VERSION ""

NS_ :

BS_:

BU_: SGW RFHM MPAD IPC GNMM EVCU2 ESL ECM DTCM DMSM BSM BCM AGSM ADCAM

BO_ 1056 EPS_FD_2: 32 BCM
 SG_ EPS_Warn_Disp_Rq : 87|3@0+ (1,0) [0|3] "" MPAD,SGW,BSM,IPC
 SG_ MessageCounter_EPS2 : 179|4@0+ (1,0) [0|15] ""  MPAD,BSM,IPC
 SG_ CRC_EPS2 : 191|8@0+ (1,0) [0|255] ""  MPAD,BSM,IPC
 SG_ MAC_EPS2 : 215|48@0+ (1,0) [0|0] "-"  MPAD,BSM
 SG_ Cntr_EPS2 : 199|16@0+ (1,0) [0|0] "-"  MPAD,BSM

BO_ 264 EPS_FD_1: 32 BCM
 SG_ LwsAngle : 7|16@0+ (0.1,-720) [-720|720] "°"  MPAD,EVCU2,DMSM,GNMM,BSM,IPC,DTCM
 SG_ LwsSpeed : 19|12@0+ (1,-2000) [-2000|2094] "°/s"  MPAD,EVCU2,BSM,DTCM
 SG_ MessageCounter_EPS1 : 179|4@0+ (1,0) [0|15] "-"  MPAD,EVCU2,BSM
 SG_ CRC_EPS1 : 191|8@0+ (1,0) [0|255] "-"  MPAD,EVCU2,BSM
 SG_ LwsCalibration : 36|1@0+ (1,0) [0|1] "-"  BSM,DTCM
 SG_ LwsAngleType : 52|2@0+ (1,0) [0|2] "-"  BSM
 SG_ EngineFanRequestActivation : 38|1@0+ (1,0) [0|1] "-"  MPAD,BSM
 SG_ ElectricSteeringFailSts : 37|1@0+ (1,0) [0|1] "-"  MPAD,BSM,DTCM
 SG_ LwsAngle_F : 105|16@0+ (0.1,-720) [-720|720] "°"  MPAD,BSM
 SG_ MAC_EPS1 : 215|48@0+ (1,0) [0|0] "-"  MPAD,BSM
 SG_ Cntr_EPS1 : 199|16@0+ (1,0) [0|0] "-"  MPAD,BSM

BO_ 1055 ENGINE_FD_8: 32 ECM
 SG_ RevOilLifeRst : 167|16@0+ (1000,0) [0|65534000] "Rev's"  BCM
 SG_ RefuelEvent : 44|3@0+ (1,0) [0|0] "-"  BCM
 SG_ OIL_PRESS : 159|8@0+ (4,0) [0|1016] "kPaG"  SGW,IPC
 SG_ MAP_4_BAR : 96|9@0+ (0.8,0) [0|408] "kPa"  SGW,BCM
 SG_ AM_ECM_Prsnt : 103|2@0+ (1,0) [0|2] "-"  BCM
 SG_ MessageCounter_ENGINE8 : 179|4@0+ (1,0) [0|15] "-"  EVCU2
 SG_ CRC_ENGINE8 : 191|8@0+ (1,0) [0|255] "-"  EVCU2
 SG_ RefuelIndication : 47|3@0+ (1,0) [0|7] "-"  IPC

BO_ 1448 ENGINE_FD_7: 32 EVCU2
 SG_ ExhaustTemperature : 135|8@0+ (4,0) [0|1020] "°C"  Vector__XXX
 SG_ ETCFailSts : 115|2@0+ (1,0) [0|3] "-"  IPC
 SG_ EngineOperatingMode : 124|3@0+ (1,0) [0|7] "-"  Vector__XXX
 SG_ EMSFailSts : 82|2@0+ (1,0) [0|3] "-"  BCM,IPC
 SG_ ECM_WARN : 159|5@0+ (1,0) [0|31] "-"  IPC
 SG_ OilPressureSts : 119|1@0+ (1,0) [0|1] "-"  SGW,BCM,IPC
 SG_ HoursOilLifeRst : 35|12@0+ (1,0) [0|4000] "Hours"  BCM
 SG_ MntncSts : 137|2@0+ (1,0) [0|3] "-"  IPC

BO_ 751 ENGINE_FD_6: 32 ECM
 SG_ EngineWaterTemp : 95|8@0+ (1,-40) [-40|215] "°C"  SGW,BCM,IPC
 SG_ MessageCounter_ENGINE6 : 179|4@0+ (1,0) [0|15] "-"  SGW
 SG_ LeakTestSts : 169|2@0+ (1,0) [0|0] ""  BCM
 SG_ LeakTestRequest : 160|1@0+ (1,0) [0|1] "-"  BCM
 SG_ LeakCheckTimerValue : 56|9@0+ (1,0) [0|510] "min"  BCM
 SG_ CRC_ENGINE6 : 191|8@0+ (1,0) [0|255] "-"  SGW
 SG_ ECM_FOTA_Conflict : 8|1@0+ (1,0) [0|1] "-"  Vector__XXX

BO_ 518 ENGINE_FD_5: 32 ECM
 SG_ RPMOverRev_W : 115|1@0+ (1,0) [0|1] "-"  Vector__XXX
 SG_ PdlPosActual : 87|8@0+ (0.4,0) [0|100] "%"  SGW,BCM
 SG_ MessageCounter_ENGINE5 : 179|4@0+ (1,0) [0|15] "-"  EVCU2
 SG_ ECM_READINESS_RESET_W : 140|1@0+ (1,0) [0|0] ""  EVCU2,BSM
 SG_ ECM_CODE_CLR_W : 141|1@0+ (1,0) [0|0] ""  EVCU2,BSM
 SG_ CRC_ENGINE5 : 191|8@0+ (1,0) [0|255] "-"  EVCU2

BO_ 1054 ENGINE_FD_1: 32 ECM
 SG_ ThrottlePosition : 87|8@0+ (0.392,0) [0|99.96] "%"  SGW,BCM
 SG_ ThermalManagementActive_W : 1|1@0+ (1,0) [0|1] "-"  EVCU2
 SG_ RawTPS2 : 55|8@0+ (0.019607843,0) [0|4.98] "V"  SGW
 SG_ RawTPS1 : 63|8@0+ (0.019607843,0) [0|4.98] "V"  SGW,BCM
 SG_ MessageCounter_ENGINE1 : 179|4@0+ (1,0) [0|15] "-"  EVCU2
 SG_ Lv1CrsCtrlOff : 7|1@0+ (1,0) [0|1] "-"  SGW,BCM
 SG_ ESP_TrqRqEnabl : 6|1@0+ (1,0) [0|1] "-"  SGW,BCM
 SG_ EngMaxRPM_W : 127|8@0+ (50,0) [0|10000] "-"  EVCU2
 SG_ CRC_ENGINE1 : 191|8@0+ (1,0) [0|255] "-"  EVCU2
 SG_ BrkSw2Stat : 5|1@0+ (1,0) [0|1] "-"  SGW,BCM
 SG_ BrkSw1Stat : 4|1@0+ (1,0) [0|1] "-"  SGW
 SG_ AtmosphericPressureFailSts_W : 0|1@0+ (1,0) [0|1] "-"  Vector__XXX
 SG_ AtmosphericPressure_W : 143|8@0+ (3.6,300) [300|1214.4] "mbar"  RFHM
 SG_ HighPressureFuelSystemFailure : 2|1@0+ (1,0) [0|1] "-"  IPC

BO_ 2654817991 ECU_APPL_FD_RFHM: 64 RFHM
 SG_ ECU_APPL_FD_RFHM : 455|64@0+ (1,0) [0|0] "" Vector__XXX

BO_ 2654817818 ECU_APPL_FD_DTCM: 64 DTCM
 SG_ ECU_APPL_FD_DTCM : 455|64@0+ (1,0) [0|0] "" SGW

BO_ 2654817823 ECU_APPL_FD_AGSM: 64 AGSM
 SG_ ECU_APPL_FD_AGSM : 455|64@0+ (1,0) [0|0] "" SGW

BO_ 1068 DRIVETRAIN_FD_3: 32 DTCM
 SG_ DTCM_Vehicle_Hold_Rq : 103|1@0+ (1,0) [0|1] "" Vector__XXX
 SG_ TCASERANGESTATUS : 89|2@0+ (1,0) [0|2] "" ADCAM,MPAD,EVCU2,SGW,BCM,BSM,IPC,DTCM
 SG_ RrAxleLockerIndRq : 5|2@0+ (1,0) [0|2] "" BCM,IPC
 SG_ AxleLckrEvicDisp : 23|5@0+ (1,0) [0|30] "" IPC
 SG_ AxleLckr_Stat : 7|2@0+ (1,0) [0|2] "" SGW,IPC
 SG_ AxleLckr_SRV_RQ : 1|2@0+ (1,0) [0|2] "" IPC
 SG_ MessageCounter_DRIVETRAIN3 : 179|4@0+ (1,0) [0|15] "-" BCM,EVCU2
 SG_ CRC__DRIVETRAIN3 : 191|8@0+ (1,0) [0|255] "-" BCM,EVCU2

BO_ 1447 DRIVETRAIN_FD_2: 32 DTCM
 SG_ TerSt_SWITCH2 : 87|2@0+ (1,0) [0|3] "-"  SGW,BCM,IPC
 SG_ TerSt_SWITCH1 : 85|2@0+ (1,0) [0|3] "-"  SGW,BCM,IPC
 SG_ DTCM_HMI_Rq : 109|5@0+ (1,0) [0|31] "-"  IPC
 SG_ Ft_RrCouplingTrq_percentage : 119|8@0+ (0.5,0) [0|127.5] "%"  Vector__XXX

BO_ 517 DRIVETRAIN_FD_1: 32 DTCM
 SG_ Ft_RrCouplingTrq_Desired : 111|8@0+ (12,0) [1|3000] "Nm"  EVCU2,SGW
 SG_ Ft_RrCouplingTrq_Actual : 103|8@0+ (12,0) [1|3000] "Nm"  EVCU2,SGW,BSM
 SG_ DrvLnMinTrqMd : 84|1@0+ (1,0) [0|1] "-"  EVCU2
 SG_ CCMFailSts : 83|1@0+ (1,0) [0|1] "-"  EVCU2,SGW,BSM,IPC
 SG_ AWDSysStat : 87|3@0+ (1,0) [0|7] "-"  EVCU2,SGW,BCM,BSM,IPC,RFHM,DTCM
 SG_ TCASE_TargetRangeState : 9|2@0+ (1,0) [0|3] "" EVCU2
 SG_ SpeedSyncRq : 20|3@0+ (1,0) [0|7] "" EVCU2
 SG_ RDU_State : 41|2@0+ (1,0) [0|3] "" EVCU2
 SG_ PTU_State : 44|3@0+ (1,0) [0|7] "" EVCU2
 SG_ DrvLnTrqRq_Axle : 31|16@0+ (1,0) [0|65535] "Nm"  EVCU2
 SG_ MessageCounter_DRIVETRAIN1 : 179|4@0+ (1,0) [0|15] "-" EVCU2
 SG_ CRC_DRIVETRAIN1 : 191|8@0+ (1,0) [0|255] "-" EVCU2

BO_ 2564682015 DIAGNOSTIC_ROE_SHIFTER: 8 AGSM
 SG_ N_PDU : 7|64@0+ (1,0) [0|0] "" SGW

BO_ 2564682183 DIAGNOSTIC_ROE_RFHM: 8 RFHM
 SG_ N_PDU : 7|64@0+ (1,0) [0|0] "" SGW

BO_ 2564682080 DIAGNOSTIC_ROE_IPC: 8 IPC
 SG_ N_PDU : 7|64@0+ (1,0) [0|0] "" SGW

BO_ 2564682256 DIAGNOSTIC_ROE_FD_ECM: 64 ECM
 SG_ N_PDU : 7|64@0+ (1,0) [0|0] "" SGW

BO_ 2564682266 DIAGNOSTIC_ROE_FD_DTCM: 64 DTCM
 SG_ N_PDU : 7|64@0+ (1,0) [0|0] "" SGW

BO_ 2564682180 DIAGNOSTIC_ROE_ESL: 8 ESL
 SG_ N_PDU : 7|64@0+ (1,0) [0|0] "" SGW

BO_ 2564682000 DIAGNOSTIC_ROE_ECM: 8 ECM
 SG_ N_PDU : 7|64@0+ (1,0) [0|0] "" SGW

BO_ 2564682010 DIAGNOSTIC_ROE_DTCM: 8 DTCM
 SG_ N_PDU : 7|64@0+ (1,0) [0|0] "" SGW

BO_ 2564682024 DIAGNOSTIC_ROE_BSM: 8 BSM
 SG_ N_PDU : 7|64@0+ (1,0) [0|0] "" SGW

BO_ 2564485663 DIAGNOSTIC_RESPONSE_FD_SHIFTER: 64 AGSM
 SG_ N_PDU : 7|64@0+ (1,0) [0|0] "" SGW

BO_ 2564485831 DIAGNOSTIC_RESPONSE_FD_RFHM: 64 RFHM
 SG_ N_PDU : 7|64@0+ (1,0) [0|0] "" SGW

BO_ 2564485728 DIAGNOSTIC_RESPONSE_FD_IPC: 64 IPC
 SG_ N_PDU : 7|64@0+ (1,0) [0|0] "" SGW

BO_ 2564485828 DIAGNOSTIC_RESPONSE_FD_ESL: 64 ESL
 SG_ N_PDU : 7|64@0+ (1,0) [0|0] "" SGW

BO_ 2564485648 DIAGNOSTIC_RESPONSE_FD_ECM: 64 ECM
 SG_ N_PDU : 7|64@0+ (1,0) [0|0] "" SGW

BO_ 2564485658 DIAGNOSTIC_RESPONSE_FD_DTCM: 64 DTCM
 SG_ N_PDU : 7|64@0+ (1,0) [0|0] "" SGW

BO_ 2564485672 DIAGNOSTIC_RESPONSE_FD_BSM: 64 BSM
 SG_ N_PDU : 7|64@0+ (1,0) [0|0] "" SGW

BO_ 2564431858 DIAGNOSTIC_REQUEST_FD_SHIFTER: 64 SGW
 SG_ N_PDU : 7|64@0+ (1,0) [0|0] "" AGSM

BO_ 2564474866 DIAGNOSTIC_REQUEST_FD_RFHM: 64 SGW
 SG_ N_PDU : 7|64@0+ (1,0) [0|0] "" RFHM

BO_ 2564448498 DIAGNOSTIC_REQUEST_FD_IPC: 64 SGW
 SG_ N_PDU : 7|64@0+ (1,0) [0|0] "" IPC

BO_ 2564554482 DIAGNOSTIC_REQUEST_FD_FUNCTIONAL: 64 SGW
 SG_ N_PDU : 7|64@0+ (1,0) [0|0] "" ADCAM,MPAD,EVCU2,DMSM,GNMM,AGSM,ESL,BCM,BSM,IPC,RFHM,ECM,DTCM

BO_ 2564474098 DIAGNOSTIC_REQUEST_FD_ESL: 64 SGW
 SG_ N_PDU : 7|64@0+ (1,0) [0|0] "" EVCU2,ESL

BO_ 2564428018 DIAGNOSTIC_REQUEST_FD_ECM: 64 SGW
 SG_ N_PDU : 7|64@0+ (1,0) [0|0] "" ECM

BO_ 2564430578 DIAGNOSTIC_REQUEST_FD_DTCM: 64 SGW
 SG_ N_PDU : 7|64@0+ (1,0) [0|0] "" DTCM

BO_ 2564434162 DIAGNOSTIC_REQUEST_FD_BSM: 64 SGW
 SG_ N_PDU : 7|64@0+ (1,0) [0|0] "" BSM

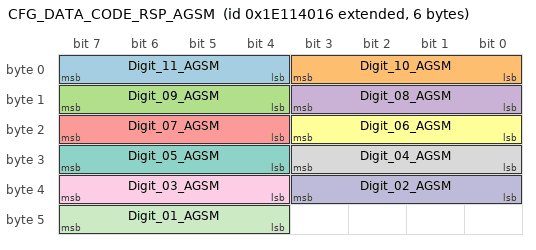
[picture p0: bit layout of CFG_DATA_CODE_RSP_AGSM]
BO_ 2651930646 CFG_DATA_CODE_RSP_AGSM: 6 AGSM
 SG_ Digit_11_AGSM : 7|4@0+ (1,0) [0|15] "-"  BCM
 SG_ Digit_10_AGSM : 3|4@0+ (1,0) [0|15] "-"  BCM
 SG_ Digit_09_AGSM : 15|4@0+ (1,0) [0|15] "-"  BCM
 SG_ Digit_08_AGSM : 11|4@0+ (1,0) [0|15] "-"  BCM
 SG_ Digit_07_AGSM : 23|4@0+ (1,0) [0|15] "-"  BCM
 SG_ Digit_06_AGSM : 19|4@0+ (1,0) [0|15] "-"  BCM
 SG_ Digit_05_AGSM : 31|4@0+ (1,0) [0|15] "-"  BCM
 SG_ Digit_04_AGSM : 27|4@0+ (1,0) [0|15] "-"  BCM
 SG_ Digit_03_AGSM : 39|4@0+ (1,0) [0|15] "-"  BCM
 SG_ Digit_02_AGSM : 35|4@0+ (1,0) [0|15] "-"  BCM
 SG_ Digit_01_AGSM : 47|4@0+ (1,0) [0|15] "-"  BCM

BO_ 514 BRAKE_FD_7: 32 BSM
 SG_ PAM_Brk_Rq_RspSts : 28|2@0+ (1,0) [0|3] "-"  BCM,IPC
 SG_ MessageCounter_BRAKE7 : 179|4@0+ (1,0) [0|15] "-"  ADCAM,MPAD,EVCU2,BCM
 SG_ HoldnGoLEDSts : 91|2@0+ (1,0) [0|2] "" BCM
 SG_ CRC_BRAKE7 : 191|8@0+ (1,0) [0|255] "-"  ADCAM,MPAD,EVCU2,BCM
 SG_ BrkPdl_Stat : 85|2@0+ (1,0) [0|2] "-"  MPAD,EVCU2,SGW,BCM,IPC,RFHM,ECM,DTCM
 SG_ BrkPdl_Flt : 86|1@0+ (1,0) [0|1] "-"  MPAD,EVCU2,SGW,BCM,ECM,DTCM
 SG_ BrakePdlPosn : 63|8@0+ (0.4,0) [0|100] "%"  EVCU2,SGW,BCM,ECM
 SG_ AVHTextDispaly : 71|4@0+ (1,0) [0|15] "-"  IPC
 SG_ AutoVehHoldSts : 30|2@0+ (1,0) [0|3] "-"  MPAD,EVCU2,BCM,IPC
 SG_ Rear_Diff_BSM_RQ : 77|2@0+ (1,0) [0|2] "-"  BCM,DTCM
 SG_ R_DIFF_TRQ_RQ : 40|9@0+ (10,0) [0|5100] "Nm"  DTCM
 SG_ BSM_OpStat : 74|3@0+ (1,0) [0|5] "" MPAD,BCM,DTCM
 SG_ Brake_OpStat_Prim : 82|3@0+ (1,0) [0|5] "" MPAD
 SG_ AEB_Type_Brk : 67|4@0+ (1,0) [0|14] "-"  ADCAM,MPAD

BO_ 1155 BRAKE_FD_5: 32 BSM
 SG_ TSCActive : 110|1@0+ (1,0) [0|1] "-"  MPAD,BCM
 SG_ RollsModeAct : 91|1@0+ (1,0) [0|1] "-"  MPAD,EVCU2,DTCM
 SG_ FunctionIntervention : 80|1@0+ (1,0) [0|1] "-"  DTCM
 SG_ FunctionFailSts : 81|1@0+ (1,0) [0|1] "-"  DTCM
 SG_ Function2Sts : 94|1@0+ (1,0) [0|1] "-"  MPAD,SGW,BCM,IPC,DTCM
 SG_ ESCIntervention : 82|1@0+ (1,0) [0|1] "-"  BCM,IPC,DTCM
 SG_ ESCFailSts : 83|1@0+ (1,0) [0|1] "-"  MPAD,EVCU2,SGW,BCM,IPC,DTCM
 SG_ ERMActive : 111|1@0+ (1,0) [0|1] "-"  BCM,DTCM
 SG_ EBDFailSts : 84|1@0+ (1,0) [0|1] "-"  SGW,BCM,IPC
 SG_ CMMIntervention : 86|1@0+ (1,0) [0|1] "-"  Vector__XXX
 SG_ BSMSysSts : 89|2@0+ (1,0) [0|3] "-"  SGW,DTCM
 SG_ ACCEngaged : 92|1@0+ (1,0) [0|1] "-"  EVCU2,SGW
 SG_ ABSFailSts : 87|1@0+ (1,0) [0|1] "-"  MPAD,EVCU2,SGW,BCM,IPC,DTCM
 SG_ MessageCounter_BRAKE5 : 179|4@0+ (1,0) [0|15] "-"  MPAD,EVCU2,IPC
 SG_ HDCUserFdBck : 124|2@0+ (1,0) [0|3] "-"  IPC
 SG_ CRC_BRAKE5 : 191|8@0+ (1,0) [0|255] "-"  MPAD,EVCU2,IPC
 SG_ FunctionSts : 95|1@0+ (1,0) [0|1] "-"  ADCAM,MPAD,BCM,IPC,DTCM
 SG_ HillHolderFailSts : 7|1@0+ (1,0) [0|1] "-"  Vector__XXX

BO_ 609 BRAKE_FD_4: 32 BSM
 SG_ TravelDistance : 87|8@0+ (1,0) [0|255] "m"  EVCU2,SGW,IPC,ECM
 SG_ RedLampReq : 131|2@0+ (1,0) [0|3] "-"  IPC
 SG_ MSRActive : 92|1@0+ (1,0) [0|1] "-"  EVCU2,BCM
 SG_ EPBSwitchPosition : 119|2@0+ (1,0) [0|3] "-"  BCM
 SG_ EPBSts : 115|4@0+ (1,0) [0|14] "-"  MPAD,EVCU2,SGW,BCM,IPC,DTCM
 SG_ EPBMaintenanceSts : 128|1@0+ (1,0) [0|1] "-"  SGW
 SG_ EPBAutoAppSts : 127|1@0+ (1,0) [0|1] "-"  Vector__XXX
 SG_ EPB_HMI_Management : 148|5@0+ (1,0) [0|31] "-"  SGW,IPC
 SG_ ClampForce : 88|9@0+ (0.1,-0.1) [0|51] "KN"  SGW,BCM
 SG_ ASRActive : 90|1@0+ (1,0) [0|1] "-"  MPAD,EVCU2,SGW,BCM,DTCM
 SG_ REPRGD_PFC_CLR_BSM : 175|1@0+ (1,0) [0|1] "-"  ECM
 SG_ MIL_OnRq_BSM : 172|1@0+ (1,0) [0|1] "-"  SGW,ECM
 SG_ MessageCounter_BRAKE4 : 179|4@0+ (1,0) [0|15] "-"  MPAD,EVCU2,BCM,IPC
 SG_ ESCSysEmsMlfAtv : 159|1@0+ (1,0) [0|0] "-"  Vector__XXX
 SG_ EPBWarningLampReq : 174|2@0+ (1,0) [0|0] "-"  BCM,IPC
 SG_ CRC_BRAKE4 : 191|8@0+ (1,0) [0|255] "-"  MPAD,EVCU2,BCM,IPC
 SG_ CODE_CLR_BSM : 160|1@0+ (1,0) [0|1] "-"  ECM
 SG_ ESC_OFF_Hrd_Sft_Button_sts : 151|3@0+ (1,0) [0|6] "-"  SGW,BCM

BO_ 259 BRAKE_FD_3: 32 BSM
 SG_ RHR_WheelSensorFailSts : 103|1@0+ (1,0) [0|1] "-"  MPAD,EVCU2,SGW,BCM,DTCM
 SG_ RHR_Spin : 102|2@0+ (1,0) [0|3] "-"  MPAD,EVCU2,SGW,BCM,DTCM
 SG_ RHR_FastPulseCounter : 159|8@0+ (1,0) [0|255] "pulse"  MPAD,EVCU2,GNMM,SGW,BCM,RFHM
 SG_ RHF_WheelSensorFailSts : 182|1@0+ (1,0) [0|1] "-"  MPAD,EVCU2,SGW,BCM,DTCM
 SG_ RHF_FastPulseCounter : 175|8@0+ (1,0) [0|255] "pulse"  MPAD,EVCU2,GNMM,SGW,BCM,RFHM
 SG_ LHR_WheelSensorFailSts : 87|1@0+ (1,0) [0|1] "-"  MPAD,EVCU2,SGW,BCM,DTCM
 SG_ LHR_Spin : 86|2@0+ (1,0) [0|3] "-"  MPAD,EVCU2,SGW,BCM,DTCM
 SG_ LHR_FastPulseCounter : 151|8@0+ (1,0) [0|255] "pulse"  MPAD,EVCU2,GNMM,SGW,BCM,RFHM
 SG_ LHF_WheelSensorFailSts : 181|1@0+ (1,0) [0|1] "-"  MPAD,EVCU2,SGW,BCM,DTCM
 SG_ LHF_FastPulseCounter : 167|8@0+ (1,0) [0|255] "pulse"  MPAD,EVCU2,GNMM,SGW,BCM,RFHM
 SG_ RHRWheelSpeed : 68|13@0+ (0.0625,0) [0|511.875] "Km/h"  MPAD,EVCU2,GNMM,SGW,BCM,ECM,DTCM
 SG_ RHFWheelSpeed : 52|13@0+ (0.0625,0) [0|511.875] "Km/h"  MPAD,EVCU2,GNMM,SGW,BCM,ECM,DTCM
 SG_ RHF_Spin : 7|2@0+ (1,0) [0|3] "-"  MPAD,EVCU2,SGW,BCM,DTCM
 SG_ MessageCounter_BRAKE3 : 179|4@0+ (1,0) [0|15] "-"  MPAD,EVCU2,GNMM,BCM
 SG_ LHRWheelSpeed : 4|13@0+ (0.0625,0) [0|511.875] "Km/h"  MPAD,EVCU2,GNMM,SGW,BCM,ECM,DTCM
 SG_ LHFWheelSpeed : 20|13@0+ (0.0625,0) [0|511.875] "Km/h"  MPAD,EVCU2,GNMM,SGW,BCM,ECM,DTCM
 SG_ LHF_Spin : 23|2@0+ (1,0) [0|3] "-"  MPAD,EVCU2,SGW,BCM,DTCM
 SG_ CRC__BRAKE3 : 191|8@0+ (1,0) [0|255] "-"  MPAD,EVCU2,GNMM,BCM
 SG_ LongAccelerationOffset_BSM : 119|8@0+ (0.02,-2.56) [-2.56|2.52] "m/s^2"  Vector__XXX
 SG_ LatAccelerationOffset_BSM : 127|8@0+ (0.02,-2.56) [-2.56|2.52] "m/s^2"  Vector__XXX
 SG_ LwsAngleOffset_BSM : 81|10@0+ (0.1,-51.1) [-51.1|51.1] "°"  GNMM

BO_TX_BU_ 1448 : EVCU2,ECM;
CM_ SG_ 1056 CRC_EPS2 "CRC according to SAE J1850 standard at each frame transmission.";
CM_ SG_ 1056 Cntr_EPS2 "-";
CM_ SG_ 1056 EPS_Warn_Disp_Rq "Electric Power Steering Warning Display Request";
CM_ SG_ 1056 MessageCounter_EPS2 "This signal is a counter used for safety checks strategies. This counter is incremented of 1 (one) unit at each frame transmission.";
CM_ SG_ 1056 MAC_EPS2 "-";
CM_ SG_ 264 LwsAngle "This signal indicates the steering angle value, counterclockwise positive.";
CM_ SG_ 264 LwsSpeed "This signal indicates the steering speed value, counterclockwise positive.";
CM_ SG_ 264 LwsAngle_F "This signal indicates the steering angle value, counterclockwise positive - duplicated signal for FUSA";
CM_ SG_ 264 LwsAngleType "This signal indicates whether the angle sensor is absolute (all the possible turns/degrees) or not absolute (relative, torque only, etc.).";
CM_ SG_ 264 LwsCalibration "This signal indicates if the sensor has been calibrated and therefore the steering angle value is exported over Can.";
CM_ SG_ 264 MAC_EPS1 "-";
CM_ SG_ 264 MessageCounter_EPS1 "This signal is a counter used for safety checks strategies. This counter is incremented of 1 (one) unit at each frame transmission.";
CM_ SG_ 264 EngineFanRequestActivation "This signal is used to activate the cooling fun by the electric power steering.";
CM_ SG_ 264 ElectricSteeringFailSts "It indicates if system EPS has an internal fault.";
CM_ SG_ 264 Cntr_EPS1 "-";
CM_ SG_ 264 CRC_EPS1 "CRC according to SAE J1850 standard at each frame transmission.";
CM_ SG_ 1055 RefuelIndication "Indication to the driver about the status of the refuel system";
CM_ SG_ 1055 RevOilLifeRst "Engine revolutions since last oil life reset";
CM_ SG_ 1055 AM_ECM_Prsnt "Aftermarket ECM present";
CM_ SG_ 1055 CRC_ENGINE8 "CRC according to SAE J1850 standard at each frame transmission.";
CM_ SG_ 1055 MAP_4_BAR "Engine manifold pressure (4 bar range)";
CM_ SG_ 1055 MessageCounter_ENGINE8 "This signal is a counter used for safety checks strategies. This counter is incremented of 1 (one) unit at each frame transmission.";
CM_ SG_ 1055 OIL_PRESS "Oil pressure";
CM_ SG_ 1055 RefuelEvent "Status of refuel event";
CM_ SG_ 1448 MntncSts "Maintenance reminder status";
CM_ SG_ 1448 ECM_WARN "This signal will be used to drive warning messages on Cluster.";
CM_ SG_ 1448 HoursOilLifeRst "Hours since last oil life reset";
CM_ SG_ 1448 OilPressureSts "This signal  indicates oil pressure status (High or low).";
CM_ SG_ 1448 EMSFailSts "This signal is used  to switch on and off the engine control system warning lamp (called MI for EOBD applications)";
CM_ SG_ 1448 EngineOperatingMode "This signal indicates the engine operating mode (normal or after-treatment systems regeneration)";
CM_ SG_ 1448 ETCFailSts "This signal is used  to switch on and off  ETC lamp to give informations about faults not EOBD relevant.";
CM_ SG_ 1448 ExhaustTemperature "This signal indicates the exhaust engine temperature after combustion or after-treatment systems (if applicable)";
CM_ SG_ 751 LeakTestRequest "Leak test is requested after powerdown; No request = [0], Leak test requested = [1]";
CM_ SG_ 751 LeakCheckTimerValue "Requested leak test timer value";
CM_ SG_ 751 ECM_FOTA_Conflict "ECM Conflict with FOTA";
CM_ SG_ 751 CRC_ENGINE6 "CRC according to SAE J1850 standard at each frame transmission.";
CM_ SG_ 751 EngineWaterTemp "-";
CM_ SG_ 751 MessageCounter_ENGINE6 "This signal is a counter used for safety checks strategies. This counter is incremented of 1 (one) unit at each frame transmission.";
CM_ SG_ 751 LeakTestSts "Status of leak test";
CM_ SG_ 518 RPMOverRev_W "-";
CM_ SG_ 518 PdlPosActual "Actual pedal position.";
CM_ SG_ 518 MessageCounter_ENGINE5 "This signal is a counter used for safety checks strategies. This counter is incremented of 1 (one) unit at each frame transmission.";
CM_ SG_ 518 ECM_READINESS_RESET_W "Handshake for not to send";
CM_ SG_ 518 ECM_CODE_CLR_W "Handshake for not to send";
CM_ SG_ 518 CRC_ENGINE5 "CRC according to SAE J1850 standard at each frame transmission.";
CM_ SG_ 1054 AtmosphericPressure_W "-";
CM_ SG_ 1054 AtmosphericPressureFailSts_W "-";
CM_ SG_ 1054 BrkSw1Stat "EDR ONLY - Brake switch1 status, off = [0]";
CM_ SG_ 1054 BrkSw2Stat "EDR ONLY - Brake switch2 status, off = [0]";
CM_ SG_ 1054 CRC_ENGINE1 "CRC according to SAE J1850 standard at each frame transmission.";
CM_ SG_ 1054 EngMaxRPM_W "-";
CM_ SG_ 1054 ESP_TrqRqEnabl "EDR ONLY - ESP torque requests are allowed = [1]";
CM_ SG_ 1054 HighPressureFuelSystemFailure "High Pressure Fuel Pump (HPFP) system failure where torque is limited to the amount of available fuel from supply pump.";
CM_ SG_ 1054 Lv1CrsCtrlOff "EDR ONLY - Level is requested cruise off";
CM_ SG_ 1054 MessageCounter_ENGINE1 "This signal is a counter used for safety checks strategies. This counter is incremented of 1 (one) unit at each frame transmission.";
CM_ SG_ 1054 RawTPS1 "EDR ONLY - Raw throttle position sensor #1";
CM_ SG_ 1054 RawTPS2 "EDR ONLY - Raw throttle position sensor #2";
CM_ SG_ 1054 ThermalManagementActive_W "-";
CM_ SG_ 1054 ThrottlePosition "GASOLINE APPLICATION ONLY This signal represents throttle position evaluated on the basis of throttle position sensor.";
CM_ SG_ 2654817991 ECU_APPL_FD_RFHM "ECU to external application";
CM_ SG_ 2654817818 ECU_APPL_FD_DTCM "ECU to external application";
CM_ SG_ 2654817823 ECU_APPL_FD_AGSM "ECU to external application";
CM_ SG_ 1068 DTCM_Vehicle_Hold_Rq "DTCM receives EPB status and triggers, then sends EPB hold request.";
CM_ SG_ 1068 TCASERANGESTATUS "This signal is used for update the Transfer case Range status";
CM_ SG_ 1068 RrAxleLockerIndRq "Rear Axle Locker LED Indicator";
CM_ SG_ 1068 AxleLckr_SRV_RQ "Axle Locker Service Request";
CM_ SG_ 1068 AxleLckr_Stat "Axle locker status";
CM_ SG_ 1068 AxleLckrEvicDisp "Axle Locker EVIC Display";
CM_ SG_ 1068 CRC__DRIVETRAIN3 "CRC according to SAE J1850 standard at each frame transmission.";
CM_ SG_ 1068 MessageCounter_DRIVETRAIN3 "This signal is a counter used for safety checks strategies. This counter is incremented of 1 (one) unit at each frame transmission.";
CM_ SG_ 1447 TerSt_SWITCH1 "Used to manage the signaling switch status";
CM_ SG_ 1447 TerSt_SWITCH2 "Used to manage the signaling switch status";
CM_ SG_ 1447 DTCM_HMI_Rq "DTCM AWD_4WD HMI display request";
CM_ SG_ 1447 Ft_RrCouplingTrq_percentage "Front Rear Coupling Torque percentage";
CM_ SG_ 517 Ft_RrCouplingTrq_Actual "-";
CM_ SG_ 517 Ft_RrCouplingTrq_Desired "-";
CM_ SG_ 517 SpeedSyncRq "Speed Sync Request by DTCM when transmission output is able to spin independently from driveline";
CM_ SG_ 517 AWDSysStat "-";
CM_ SG_ 517 CCMFailSts "-";
CM_ SG_ 517 DrvLnMinTrqMd "-";
CM_ SG_ 517 CRC_DRIVETRAIN1 "CRC according to SAE J1850 standard at each frame transmission.";
CM_ SG_ 517 MessageCounter_DRIVETRAIN1 "This signal is a counter used for safety checks strategies. This counter is incremented of 1 (one) unit at each frame transmission.";
CM_ SG_ 2564682015 N_PDU "This signal is used for diagnostic purposes";
CM_ SG_ 2564682183 N_PDU "This signal is used for diagnostic purposes";
CM_ SG_ 2564682080 N_PDU "This signal is used for diagnostic purposes";
CM_ SG_ 2564682256 N_PDU "This signal is used for diagnostic purposes";
CM_ SG_ 2564682266 N_PDU "This signal is used for diagnostic purposes";
CM_ SG_ 2564682180 N_PDU "This signal is used for diagnostic purposes";
CM_ SG_ 2564682000 N_PDU "This signal is used for diagnostic purposes";
CM_ SG_ 2564682010 N_PDU "This signal is used for diagnostic purposes";
CM_ SG_ 2564682024 N_PDU "This signal is used for diagnostic purposes";
CM_ SG_ 2564485663 N_PDU "This signal is used for diagnostic purposes";
CM_ SG_ 2564485831 N_PDU "This signal is used for diagnostic purposes";
CM_ SG_ 2564485728 N_PDU "This signal is used for diagnostic purposes";
CM_ SG_ 2564485828 N_PDU "This signal is used for diagnostic purposes";
CM_ SG_ 2564485648 N_PDU "This signal is used for diagnostic purposes";
CM_ SG_ 2564485658 N_PDU "This signal is used for diagnostic purposes";
CM_ SG_ 2564485672 N_PDU "This signal is used for diagnostic purposes";
CM_ SG_ 2564431858 N_PDU "This signal is used for diagnostic purposes";
CM_ SG_ 2564474866 N_PDU "This signal is used for diagnostic purposes";
CM_ SG_ 2564448498 N_PDU "This signal is used for diagnostic purposes";
CM_ SG_ 2564554482 N_PDU "This signal is used for diagnostic purposes";
CM_ SG_ 2564474098 N_PDU "This signal is used for diagnostic purposes";
CM_ SG_ 2564428018 N_PDU "This signal is used for diagnostic purposes";
CM_ SG_ 2564430578 N_PDU "This signal is used for diagnostic purposes";
CM_ SG_ 2564434162 N_PDU "This signal is used for diagnostic purposes";
CM_ SG_ 514 Rear_Diff_BSM_RQ "ESP Requested Rear Differential State";
CM_ SG_ 514 R_DIFF_TRQ_RQ "Desired Torque for Rear Diff.";
CM_ SG_ 514 PAM_Brk_Rq_RspSts "PAM Brake Request Response Status made by the BSM for Park Assist with Stop.";
CM_ SG_ 514 HoldnGoLEDSts "Command BCM to illuminate Hold n Go LED";
CM_ SG_ 514 MessageCounter_BRAKE7 "This signal is a counter used for safety checks strategies. This counter is incremented of 1 (one) unit at each frame transmission.";
CM_ SG_ 514 CRC_BRAKE7 "CRC according to SAE J1850 standard at each frame transmission.";
CM_ SG_ 514 BSM_OpStat "Capability of the primary brake control module to provide deceleration and/or stability control";
CM_ SG_ 514 BrkPdl_Stat "Brake pedal state";
CM_ SG_ 514 BrkPdl_Flt "Brake Pedal Fault is active, 1=Faulted";
CM_ SG_ 514 BrakePdlPosn "Brake pedal travel sensor 0-100% (0 = upstop)";
CM_ SG_ 514 Brake_OpStat_Prim "Capability of the Braking system to perform deceleration and/or stability control as reported by primary actuator";
CM_ SG_ 514 AVHTextDispaly "Command Cluster to indicate right messages";
CM_ SG_ 514 AEB_Type_Brk "AEB type brake signal";
CM_ SG_ 514 AutoVehHoldSts "New ESC comfort feature called auto vehicle hold. Allows driver to remove his foor from the brake and the vehicle will hydraulically hold vehicle still until throttle is applied";
CM_ SG_ 1155 RollsModeAct "This signal indicates when the brake system module is in the Rolls Test mode.";
CM_ SG_ 1155 HillHolderFailSts "Hill Holder function fail status";
CM_ SG_ 1155 HDCUserFdBck "This signal is used by BSM drive the feedback to the driver command";
CM_ SG_ 1155 ACCEngaged "ACC is engaged";
CM_ SG_ 1155 CRC_BRAKE5 "CRC according to SAE J1850 standard at each frame transmission.";
CM_ SG_ 1155 ABSFailSts "0";
CM_ SG_ 1155 MessageCounter_BRAKE5 "This signal is a counter used for safety checks strategies. This counter is incremented of 1 (one) unit at each frame transmission.";
CM_ SG_ 1155 FunctionSts "Indicates the full off status of the ESC/TCS system. [0]: Not_Active - Indicates that the ESC/TCS system is enabled, [1]: Active - Indicates that the ESC/TCS system is completely disabled";
CM_ SG_ 1155 FunctionIntervention "This signal indicates the BSM is actively controlling the vehicle through either engine torque management or brake pressure modulation.";
CM_ SG_ 1155 FunctionFailSts "This signal indicates the health status of the traction control system. [0]: Fail_Not_Present, [1]: Fail_Present";
CM_ SG_ 1155 Function2Sts "Indicates the partial off status of the ESC/TCS system. [0]: Not_Active - Indicates that the ESC/TCS system is enabled, [1]: Active - Indicates that the ESC/TCS engine management is disabled";
CM_ SG_ 1155 ESCIntervention "0";
CM_ SG_ 1155 ERMActive "This signal is set to \"active\" when Electronic Roll Mitigation functionality is acting.";
CM_ SG_ 1155 ESCFailSts "0";
CM_ SG_ 1155 EBDFailSts "0";
CM_ SG_ 1155 CMMIntervention "0";
CM_ SG_ 1155 BSMSysSts "This signal is used by BSM to indicate its mode";
CM_ SG_ 1155 TSCActive "This signal is set to \"active\" when Trailer Sway Control functionality is acting";
CM_ SG_ 609 ASRActive "This signal is set to Active when the intervention by ASR is Active";
CM_ SG_ 609 ClampForce "This signal is used to give information about the EPB Clamp Force";
CM_ SG_ 609 CODE_CLR_BSM "Clear emission related faults";
CM_ SG_ 609 CRC_BRAKE4 "CRC according to SAE J1850 standard at each frame transmission.";
CM_ SG_ 609 EPBSts "0";
CM_ SG_ 609 EPB_HMI_Management "Management IPC/VP pop-up";
CM_ SG_ 609 EPBAutoAppSts "Status of AutoApply Functionality";
CM_ SG_ 609 EPBMaintenanceSts "Status of Maintenance Functionality";
CM_ SG_ 609 EPBSwitchPosition "This signal is used to give information about the postition of the EPB switch";
CM_ SG_ 609 EPBWarningLampReq "EPB warning (fault) lamp active request";
CM_ SG_ 609 ESC_OFF_Hrd_Sft_Button_sts "ESC hard button status";
CM_ SG_ 609 ESCSysEmsMlfAtv "ESC emissions related malfunction active";
CM_ SG_ 609 MessageCounter_BRAKE4 "This signal is a counter used for safety checks strategies. This counter is incremented of 1 (one) unit at each frame transmission.";
CM_ SG_ 609 TravelDistance "This signal indicates the travel distance value.";
CM_ SG_ 609 MIL_OnRq_BSM "MIL switch on request";
CM_ SG_ 609 MSRActive "0";
CM_ SG_ 609 RedLampReq "This signal is used to request the EPB RED Indication";
CM_ SG_ 609 REPRGD_PFC_CLR_BSM "Set readiness to \"incomplete\"";
CM_ SG_ 259 LongAccelerationOffset_BSM "LongAccelerationOffset_BSM";
CM_ SG_ 259 LHRWheelSpeed "This is the value of the left rear wheel speed";
CM_ SG_ 259 LHR_WheelSensorFailSts "This signal indicates the fail status of LHR sensor";
CM_ SG_ 259 LHR_Spin "This signal indicates the left hand rear wheel status";
CM_ SG_ 259 LHR_FastPulseCounter "This signal is the left rear wheel pulse counter.";
CM_ SG_ 259 LHFWheelSpeed "This is the value of the left front wheel speed";
CM_ SG_ 259 LHF_WheelSensorFailSts "This signal indicates the fail status of LHF sensor";
CM_ SG_ 259 LHF_Spin "This signal indicates the left hand front wheel status";
CM_ SG_ 259 LHF_FastPulseCounter "This signal is the left front wheel pulse counter.";
CM_ SG_ 259 LatAccelerationOffset_BSM "LatAccelerationOffset_BSM";
CM_ SG_ 259 CRC__BRAKE3 "CRC according to SAE J1850 standard at each frame transmission.";
CM_ SG_ 259 RHFWheelSpeed "This is the value of the right front wheel speed";
CM_ SG_ 259 RHF_WheelSensorFailSts "This signal indicates the fail status of RHF sensor";
CM_ SG_ 259 RHF_Spin "This signal indicates the right hand front wheel status";
CM_ SG_ 259 RHF_FastPulseCounter "This signal is the right front wheel pulse counter.";
CM_ SG_ 259 MessageCounter_BRAKE3 "This signal is a counter used for safety checks strategies. This counter is incremented of 1 (one) unit at each frame transmission.";
CM_ SG_ 259 LwsAngleOffset_BSM "LwsAngleOffset_BSM";
CM_ SG_ 259 RHR_FastPulseCounter "This signal is the right rear wheel pulse counter.";
CM_ SG_ 259 RHR_Spin "This signal indicates the right hand rear wheel status";
CM_ SG_ 259 RHR_WheelSensorFailSts "This signal indicates the fail status of RHR sensor";
CM_ SG_ 259 RHRWheelSpeed "This is the value of the right rear wheel speed";
BA_DEF_ BO_ "CANFD_BRS" ENUM "0","1";
BA_DEF_ BO_ "VFrameFormat" ENUM "StandardCAN","ExtendedCAN","reserved","reserved","reserved","reserved","reserved","reserved","reserved","reserved","reserved","reserved","reserved","reserved","StandardCAN_FD","ExtendedCAN_FD";
BA_DEF_ BO_ "DiagConnection" HEX 0 65535;
BA_DEF_ BO_ "DiagState" ENUM "No","Yes";
BA_DEF_ BO_ "NmAsrMessage" ENUM "No","Yes";
BA_DEF_ BO_ "GenMsgDelayTime" INT 0 65535;
BA_DEF_ BO_ "GenMsgCycleTime" INT 0 65535;
BA_DEF_ BO_ "GenMsgCycleTimeFast" INT 0 65535;
BA_DEF_ BO_ "GenMsgStartDelayTime" INT 0 65535;
BA_DEF_ BO_ "GenMsgILSupport" ENUM "No","Yes";
BA_DEF_ BO_ "GenMsgNrOfRepetition" INT 0 255;
BA_DEF_ BO_ "GenMsgSendType" ENUM "Cyclic","NotUsed","NotUsed","NotUsed","NotUsed","NotUsed","NotUsed","NotUsed","NoMsgSendType";
BA_DEF_ BO_ "NmMessage" ENUM "No","Yes";
BA_DEF_ BO_ "DiagResponse" ENUM "No","Yes";
BA_DEF_ BO_ "Type" ENUM "P","C","PE","COC","PE_Cntrl","E","E_Cntrl","OC","S","BAF","DC","EM","MM","ISO-TP","-";
BA_DEF_ BO_ "DiagRequest" ENUM "No","Yes";
BA_DEF_ SG_ "GenSigTimeoutTime_SGW" INT 0 65535;
BA_DEF_ SG_ "GenSigTimeoutTime_RFHM" INT 0 65535;
BA_DEF_ SG_ "GenSigTimeoutTime_MPAD" INT 0 65535;
BA_DEF_ SG_ "GenSigTimeoutTime_IPC" INT 0 65535;
BA_DEF_ SG_ "GenSigTimeoutTime_GNMM" INT 0 65535;
BA_DEF_ SG_ "GenSigTimeoutTime_EVCU2" INT 0 65535;
BA_DEF_ SG_ "GenSigTimeoutTime_ESL" INT 0 65535;
BA_DEF_ SG_ "GenSigTimeoutTime_ECM" INT 0 65535;
BA_DEF_ SG_ "GenSigTimeoutTime_DTCM" INT 0 65535;
BA_DEF_ SG_ "GenSigTimeoutTime_DMSM" INT 0 65535;
BA_DEF_ SG_ "GenSigTimeoutTime_BSM" INT 0 65535;
BA_DEF_ SG_ "GenSigTimeoutTime_BCM" INT 0 65535;
BA_DEF_ SG_ "GenSigTimeoutTime_AGSM" INT 0 65535;
BA_DEF_ SG_ "GenSigTimeoutTime_ADCAM" INT 0 65535;
BA_DEF_ SG_ "SystemSignalLongSymbol" STRING ;
BA_DEF_ SG_ "GenSigSendType" ENUM "NotUsed","OnWrite","OnWriteWithRepetition","OnChange","OnChangeWithRepetition","IfActive","IfActiveWithRepetition","NoSigSendType";
BA_DEF_ SG_ "GenSigInactiveValue" INT 0 2147483647;
BA_DEF_ SG_ "GenSigStartValue" INT 0 2147483647;
BA_DEF_DEF_ "CANFD_BRS" "0";
BA_DEF_DEF_ "VFrameFormat" "StandardCAN_FD";
BA_DEF_DEF_ "DiagConnection" 0;
BA_DEF_DEF_ "DiagState" "No";
BA_DEF_DEF_ "NmAsrMessage" "No";
BA_DEF_DEF_ "GenMsgDelayTime" 0;
BA_DEF_DEF_ "GenMsgCycleTime" 0;
BA_DEF_DEF_ "GenMsgCycleTimeFast" 0;
BA_DEF_DEF_ "GenMsgStartDelayTime" 0;
BA_DEF_DEF_ "GenMsgILSupport" "No";
BA_DEF_DEF_ "GenMsgNrOfRepetition" 0;
BA_DEF_DEF_ "GenMsgSendType" "NoMsgSendType";
BA_DEF_DEF_ "NmMessage" "No";
BA_DEF_DEF_ "DiagResponse" "No";
BA_DEF_DEF_ "Type" "-";
BA_DEF_DEF_ "DiagRequest" "No";
BA_DEF_DEF_ "GenSigTimeoutTime_SGW" 2500;
BA_DEF_DEF_ "GenSigTimeoutTime_RFHM" 2500;
BA_DEF_DEF_ "GenSigTimeoutTime_MPAD" 2500;
BA_DEF_DEF_ "GenSigTimeoutTime_IPC" 2500;
BA_DEF_DEF_ "GenSigTimeoutTime_GNMM" 2500;
BA_DEF_DEF_ "GenSigTimeoutTime_EVCU2" 2500;
BA_DEF_DEF_ "GenSigTimeoutTime_ESL" 2500;
BA_DEF_DEF_ "GenSigTimeoutTime_ECM" 2500;
BA_DEF_DEF_ "GenSigTimeoutTime_DTCM" 2500;
BA_DEF_DEF_ "GenSigTimeoutTime_DMSM" 2500;
BA_DEF_DEF_ "GenSigTimeoutTime_BSM" 2500;
BA_DEF_DEF_ "GenSigTimeoutTime_BCM" 2500;
BA_DEF_DEF_ "GenSigTimeoutTime_AGSM" 2500;
BA_DEF_DEF_ "GenSigTimeoutTime_ADCAM" 2500;
BA_DEF_DEF_ "SystemSignalLongSymbol" "";
BA_DEF_DEF_ "GenSigSendType" "NoSigSendType";
BA_DEF_DEF_ "GenSigInactiveValue" 0;
BA_DEF_DEF_ "GenSigStartValue" 0;
BA_ "CANFD_BRS" BO_ 1056 1;
BA_ "GenMsgCycleTime" BO_ 1056 100;
BA_ "GenMsgStartDelayTime" BO_ 1056 70;
BA_ "GenMsgILSupport" BO_ 1056 1;
BA_ "GenMsgSendType" BO_ 1056 0;
BA_ "Type" BO_ 1056 1;
BA_ "CANFD_BRS" BO_ 264 1;
BA_ "GenMsgCycleTime" BO_ 264 10;
BA_ "GenMsgStartDelayTime" BO_ 264 5;
BA_ "GenMsgILSupport" BO_ 264 1;
BA_ "GenMsgSendType" BO_ 264 0;
BA_ "Type" BO_ 264 1;
BA_ "CANFD_BRS" BO_ 1055 1;
BA_ "GenMsgCycleTime" BO_ 1055 100;
BA_ "GenMsgILSupport" BO_ 1055 1;
BA_ "GenMsgSendType" BO_ 1055 0;
BA_ "Type" BO_ 1055 1;
BA_ "CANFD_BRS" BO_ 1448 1;
BA_ "GenMsgDelayTime" BO_ 1448 20;
BA_ "GenMsgCycleTime" BO_ 1448 1000;
BA_ "GenMsgCycleTimeFast" BO_ 1448 20;
BA_ "GenMsgILSupport" BO_ 1448 1;
BA_ "GenMsgNrOfRepetition" BO_ 1448 2;
BA_ "GenMsgSendType" BO_ 1448 0;
BA_ "Type" BO_ 1448 3;
BA_ "GenMsgCycleTime" BO_ 751 50;
BA_ "GenMsgILSupport" BO_ 751 1;
BA_ "GenMsgSendType" BO_ 751 0;
BA_ "Type" BO_ 751 1;
BA_ "CANFD_BRS" BO_ 751 1;
BA_ "CANFD_BRS" BO_ 518 1;
BA_ "GenMsgCycleTime" BO_ 518 20;
BA_ "GenMsgILSupport" BO_ 518 1;
BA_ "GenMsgSendType" BO_ 518 0;
BA_ "Type" BO_ 518 1;
BA_ "GenMsgSendType" BO_ 1054 0;
BA_ "CANFD_BRS" BO_ 1054 1;
BA_ "GenMsgCycleTime" BO_ 1054 100;
BA_ "GenMsgILSupport" BO_ 1054 1;
BA_ "Type" BO_ 1054 1;
BA_ "CANFD_BRS" BO_ 2654817991 1;
BA_ "VFrameFormat" BO_ 2654817991 15;
BA_ "GenMsgILSupport" BO_ 2654817991 1;
BA_ "Type" BO_ 2654817991 8;
BA_ "CANFD_BRS" BO_ 2654817818 1;
BA_ "VFrameFormat" BO_ 2654817818 15;
BA_ "GenMsgILSupport" BO_ 2654817818 1;
BA_ "Type" BO_ 2654817818 8;
BA_ "CANFD_BRS" BO_ 2654817823 1;
BA_ "VFrameFormat" BO_ 2654817823 15;
BA_ "GenMsgILSupport" BO_ 2654817823 1;
BA_ "Type" BO_ 2654817823 8;
BA_ "CANFD_BRS" BO_ 1068 1;
BA_ "GenMsgDelayTime" BO_ 1068 20;
BA_ "GenMsgCycleTime" BO_ 1068 100;
BA_ "GenMsgCycleTimeFast" BO_ 1068 20;
BA_ "GenMsgILSupport" BO_ 1068 1;
BA_ "GenMsgNrOfRepetition" BO_ 1068 2;
BA_ "GenMsgSendType" BO_ 1068 0;
BA_ "Type" BO_ 1068 3;
BA_ "CANFD_BRS" BO_ 1447 1;
BA_ "GenMsgDelayTime" BO_ 1447 20;
BA_ "GenMsgCycleTime" BO_ 1447 1000;
BA_ "GenMsgCycleTimeFast" BO_ 1447 20;
BA_ "GenMsgILSupport" BO_ 1447 1;
BA_ "GenMsgNrOfRepetition" BO_ 1447 2;
BA_ "GenMsgSendType" BO_ 1447 0;
BA_ "Type" BO_ 1447 3;
BA_ "CANFD_BRS" BO_ 517 1;
BA_ "GenMsgCycleTime" BO_ 517 20;
BA_ "GenMsgILSupport" BO_ 517 1;
BA_ "GenMsgSendType" BO_ 517 0;
BA_ "Type" BO_ 517 1;
BA_ "VFrameFormat" BO_ 2564682015 1;
BA_ "DiagConnection" BO_ 2564682015 61727;
BA_ "DiagResponse" BO_ 2564682015 1;
BA_ "Type" BO_ 2564682015 8;
BA_ "VFrameFormat" BO_ 2564682183 1;
BA_ "DiagConnection" BO_ 2564682183 61895;
BA_ "DiagResponse" BO_ 2564682183 1;
BA_ "Type" BO_ 2564682183 8;
BA_ "VFrameFormat" BO_ 2564682080 1;
BA_ "DiagConnection" BO_ 2564682080 61792;
BA_ "DiagResponse" BO_ 2564682080 1;
BA_ "Type" BO_ 2564682080 8;
BA_ "CANFD_BRS" BO_ 2564682256 1;
BA_ "VFrameFormat" BO_ 2564682256 15;
BA_ "DiagConnection" BO_ 2564682256 61968;
BA_ "DiagResponse" BO_ 2564682256 1;
BA_ "Type" BO_ 2564682256 8;
BA_ "CANFD_BRS" BO_ 2564682266 1;
BA_ "VFrameFormat" BO_ 2564682266 15;
BA_ "DiagConnection" BO_ 2564682266 61978;
BA_ "DiagResponse" BO_ 2564682266 1;
BA_ "Type" BO_ 2564682266 8;
BA_ "VFrameFormat" BO_ 2564682180 1;
BA_ "DiagConnection" BO_ 2564682180 61892;
BA_ "DiagResponse" BO_ 2564682180 1;
BA_ "Type" BO_ 2564682180 8;
BA_ "VFrameFormat" BO_ 2564682000 1;
BA_ "DiagConnection" BO_ 2564682000 61712;
BA_ "DiagResponse" BO_ 2564682000 1;
BA_ "Type" BO_ 2564682000 8;
BA_ "VFrameFormat" BO_ 2564682010 1;
BA_ "DiagConnection" BO_ 2564682010 61722;
BA_ "DiagResponse" BO_ 2564682010 1;
BA_ "Type" BO_ 2564682010 8;
BA_ "VFrameFormat" BO_ 2564682024 1;
BA_ "DiagConnection" BO_ 2564682024 61736;
BA_ "DiagResponse" BO_ 2564682024 1;
BA_ "Type" BO_ 2564682024 8;
BA_ "CANFD_BRS" BO_ 2564485663 1;
BA_ "VFrameFormat" BO_ 2564485663 15;
BA_ "DiagConnection" BO_ 2564485663 61983;
BA_ "DiagResponse" BO_ 2564485663 1;
BA_ "Type" BO_ 2564485663 8;
BA_ "CANFD_BRS" BO_ 2564485831 1;
BA_ "VFrameFormat" BO_ 2564485831 15;
BA_ "DiagConnection" BO_ 2564485831 62151;
BA_ "DiagResponse" BO_ 2564485831 1;
BA_ "Type" BO_ 2564485831 8;
BA_ "CANFD_BRS" BO_ 2564485728 1;
BA_ "VFrameFormat" BO_ 2564485728 15;
BA_ "DiagConnection" BO_ 2564485728 62048;
BA_ "DiagResponse" BO_ 2564485728 1;
BA_ "Type" BO_ 2564485728 8;
BA_ "CANFD_BRS" BO_ 2564485828 1;
BA_ "VFrameFormat" BO_ 2564485828 15;
BA_ "DiagConnection" BO_ 2564485828 62148;
BA_ "DiagResponse" BO_ 2564485828 1;
BA_ "Type" BO_ 2564485828 8;
BA_ "CANFD_BRS" BO_ 2564485648 1;
BA_ "VFrameFormat" BO_ 2564485648 15;
BA_ "DiagConnection" BO_ 2564485648 61968;
BA_ "DiagResponse" BO_ 2564485648 1;
BA_ "Type" BO_ 2564485648 8;
BA_ "CANFD_BRS" BO_ 2564485658 1;
BA_ "VFrameFormat" BO_ 2564485658 15;
BA_ "DiagConnection" BO_ 2564485658 61978;
BA_ "DiagResponse" BO_ 2564485658 1;
BA_ "Type" BO_ 2564485658 8;
BA_ "CANFD_BRS" BO_ 2564485672 1;
BA_ "VFrameFormat" BO_ 2564485672 15;
BA_ "DiagConnection" BO_ 2564485672 61992;
BA_ "DiagResponse" BO_ 2564485672 1;
BA_ "Type" BO_ 2564485672 8;
BA_ "CANFD_BRS" BO_ 2564431858 1;
BA_ "VFrameFormat" BO_ 2564431858 15;
BA_ "DiagConnection" BO_ 2564431858 61983;
BA_ "Type" BO_ 2564431858 8;
BA_ "DiagRequest" BO_ 2564431858 1;
BA_ "CANFD_BRS" BO_ 2564474866 1;
BA_ "VFrameFormat" BO_ 2564474866 15;
BA_ "DiagConnection" BO_ 2564474866 62151;
BA_ "Type" BO_ 2564474866 8;
BA_ "DiagRequest" BO_ 2564474866 1;
BA_ "CANFD_BRS" BO_ 2564448498 1;
BA_ "VFrameFormat" BO_ 2564448498 15;
BA_ "DiagConnection" BO_ 2564448498 62048;
BA_ "Type" BO_ 2564448498 8;
BA_ "DiagRequest" BO_ 2564448498 1;
BA_ "CANFD_BRS" BO_ 2564554482 1;
BA_ "VFrameFormat" BO_ 2564554482 15;
BA_ "DiagConnection" BO_ 2564554482 62206;
BA_ "DiagState" BO_ 2564554482 1;
BA_ "Type" BO_ 2564554482 8;
BA_ "CANFD_BRS" BO_ 2564474098 1;
BA_ "VFrameFormat" BO_ 2564474098 15;
BA_ "DiagConnection" BO_ 2564474098 62148;
BA_ "Type" BO_ 2564474098 8;
BA_ "DiagRequest" BO_ 2564474098 1;
BA_ "CANFD_BRS" BO_ 2564428018 1;
BA_ "VFrameFormat" BO_ 2564428018 15;
BA_ "DiagConnection" BO_ 2564428018 61968;
BA_ "Type" BO_ 2564428018 8;
BA_ "DiagRequest" BO_ 2564428018 1;
BA_ "CANFD_BRS" BO_ 2564430578 1;
BA_ "VFrameFormat" BO_ 2564430578 15;
BA_ "DiagConnection" BO_ 2564430578 61978;
BA_ "Type" BO_ 2564430578 8;
BA_ "DiagRequest" BO_ 2564430578 1;
BA_ "CANFD_BRS" BO_ 2564434162 1;
BA_ "VFrameFormat" BO_ 2564434162 15;
BA_ "DiagConnection" BO_ 2564434162 61992;
BA_ "Type" BO_ 2564434162 8;
BA_ "DiagRequest" BO_ 2564434162 1;
BA_ "CANFD_BRS" BO_ 2651930646 1;
BA_ "VFrameFormat" BO_ 2651930646 15;
BA_ "GenMsgILSupport" BO_ 2651930646 1;
BA_ "Type" BO_ 2651930646 11;
BA_ "CANFD_BRS" BO_ 514 1;
BA_ "GenMsgCycleTime" BO_ 514 20;
BA_ "GenMsgILSupport" BO_ 514 1;
BA_ "GenMsgSendType" BO_ 514 0;
BA_ "Type" BO_ 514 1;
BA_ "GenMsgDelayTime" BO_ 1155 20;
BA_ "GenMsgCycleTime" BO_ 1155 500;
BA_ "GenMsgCycleTimeFast" BO_ 1155 20;
BA_ "GenMsgILSupport" BO_ 1155 1;
BA_ "GenMsgNrOfRepetition" BO_ 1155 2;
BA_ "GenMsgSendType" BO_ 1155 0;
BA_ "Type" BO_ 1155 3;
BA_ "CANFD_BRS" BO_ 1155 1;
BA_ "CANFD_BRS" BO_ 609 1;
BA_ "GenMsgCycleTime" BO_ 609 100;
BA_ "GenMsgCycleTimeFast" BO_ 609 20;
BA_ "GenMsgILSupport" BO_ 609 1;
BA_ "GenMsgNrOfRepetition" BO_ 609 2;
BA_ "GenMsgSendType" BO_ 609 0;
BA_ "Type" BO_ 609 3;
BA_ "CANFD_BRS" BO_ 259 1;
BA_ "GenMsgCycleTime" BO_ 259 10;
BA_ "GenMsgILSupport" BO_ 259 1;
BA_ "GenMsgSendType" BO_ 259 0;
BA_ "Type" BO_ 259 1;
BA_ "GenSigTimeoutTime_ESL" SG_ 264 LwsCalibration 0;
BA_ "GenSigTimeoutTime_ECM" SG_ 264 LwsCalibration 0;
BA_ "GenSigTimeoutTime_DMSM" SG_ 264 LwsCalibration 0;
BA_ "GenSigTimeoutTime_BCM" SG_ 264 LwsCalibration 0;
BA_ "GenSigTimeoutTime_AGSM" SG_ 264 LwsCalibration 0;
BA_ "GenSigTimeoutTime_ADCAM" SG_ 264 LwsCalibration 0;
BA_ "GenSigTimeoutTime_SGW" SG_ 264 LwsCalibration 0;
BA_ "GenSigTimeoutTime_RFHM" SG_ 264 LwsCalibration 0;
BA_ "GenSigTimeoutTime_MPAD" SG_ 264 LwsCalibration 0;
BA_ "GenSigTimeoutTime_IPC" SG_ 264 LwsCalibration 0;
BA_ "GenSigTimeoutTime_GNMM" SG_ 264 LwsCalibration 0;
BA_ "GenSigTimeoutTime_EVCU2" SG_ 264 LwsCalibration 0;
BA_ "GenSigTimeoutTime_SGW" SG_ 264 LwsAngleType 0;
BA_ "GenSigTimeoutTime_RFHM" SG_ 264 LwsAngleType 0;
BA_ "GenSigTimeoutTime_MPAD" SG_ 264 LwsAngleType 0;
BA_ "GenSigTimeoutTime_IPC" SG_ 264 LwsAngleType 0;
BA_ "GenSigTimeoutTime_GNMM" SG_ 264 LwsAngleType 0;
BA_ "GenSigTimeoutTime_EVCU2" SG_ 264 LwsAngleType 0;
BA_ "GenSigTimeoutTime_ESL" SG_ 264 LwsAngleType 0;
BA_ "GenSigTimeoutTime_ECM" SG_ 264 LwsAngleType 0;
BA_ "GenSigTimeoutTime_DTCM" SG_ 264 LwsAngleType 0;
BA_ "GenSigTimeoutTime_DMSM" SG_ 264 LwsAngleType 0;
BA_ "GenSigTimeoutTime_BCM" SG_ 264 LwsAngleType 0;
BA_ "GenSigTimeoutTime_AGSM" SG_ 264 LwsAngleType 0;
BA_ "GenSigTimeoutTime_ADCAM" SG_ 264 LwsAngleType 0;
BA_ "GenSigTimeoutTime_SGW" SG_ 264 MessageCounter_EPS1 0;
BA_ "GenSigTimeoutTime_RFHM" SG_ 264 MessageCounter_EPS1 0;
BA_ "GenSigTimeoutTime_IPC" SG_ 264 MessageCounter_EPS1 0;
BA_ "GenSigTimeoutTime_GNMM" SG_ 264 MessageCounter_EPS1 0;
BA_ "GenSigTimeoutTime_ESL" SG_ 264 MessageCounter_EPS1 0;
BA_ "GenSigTimeoutTime_ECM" SG_ 264 MessageCounter_EPS1 0;
BA_ "GenSigTimeoutTime_DTCM" SG_ 264 MessageCounter_EPS1 0;
BA_ "GenSigTimeoutTime_DMSM" SG_ 264 MessageCounter_EPS1 0;
BA_ "GenSigTimeoutTime_BCM" SG_ 264 MessageCounter_EPS1 0;
BA_ "GenSigTimeoutTime_AGSM" SG_ 264 MessageCounter_EPS1 0;
BA_ "GenSigTimeoutTime_ADCAM" SG_ 264 MessageCounter_EPS1 0;
BA_ "GenSigTimeoutTime_SGW" SG_ 1055 RevOilLifeRst 0;
BA_ "GenSigTimeoutTime_RFHM" SG_ 1055 RevOilLifeRst 0;
BA_ "GenSigTimeoutTime_DMSM" SG_ 1448 ETCFailSts 0;
BA_ "GenSigTimeoutTime_BSM" SG_ 1448 ETCFailSts 0;
BA_ "GenSigTimeoutTime_BCM" SG_ 1448 ETCFailSts 0;
BA_ "GenSigTimeoutTime_AGSM" SG_ 1448 ETCFailSts 0;
BA_ "GenSigTimeoutTime_ADCAM" SG_ 1448 ETCFailSts 0;
BA_ "GenSigSendType" SG_ 1448 ETCFailSts 3;
BA_ "GenSigTimeoutTime_SGW" SG_ 1448 EngineOperatingMode 0;
BA_ "GenSigTimeoutTime_RFHM" SG_ 1448 EngineOperatingMode 0;
BA_ "GenSigTimeoutTime_MPAD" SG_ 1448 EngineOperatingMode 0;
BA_ "GenSigTimeoutTime_IPC" SG_ 1448 EngineOperatingMode 0;
BA_ "GenSigTimeoutTime_GNMM" SG_ 1448 EngineOperatingMode 0;
BA_ "GenSigTimeoutTime_EVCU2" SG_ 1448 EngineOperatingMode 0;
BA_ "GenSigTimeoutTime_ESL" SG_ 1448 EngineOperatingMode 0;
BA_ "GenSigTimeoutTime_ECM" SG_ 1448 EngineOperatingMode 0;
BA_ "GenSigTimeoutTime_DTCM" SG_ 1448 EngineOperatingMode 0;
BA_ "GenSigTimeoutTime_DMSM" SG_ 1448 EngineOperatingMode 0;
BA_ "GenSigTimeoutTime_BSM" SG_ 1448 EngineOperatingMode 0;
BA_ "GenSigTimeoutTime_BCM" SG_ 1448 EngineOperatingMode 0;
BA_ "GenSigTimeoutTime_AGSM" SG_ 1448 EngineOperatingMode 0;
BA_ "GenSigTimeoutTime_ADCAM" SG_ 1448 EngineOperatingMode 0;
BA_ "GenSigSendType" SG_ 1448 EngineOperatingMode 3;
BA_ "GenSigTimeoutTime_SGW" SG_ 1448 EMSFailSts 0;
BA_ "GenSigTimeoutTime_RFHM" SG_ 1448 EMSFailSts 0;
BA_ "GenSigTimeoutTime_MPAD" SG_ 1448 EMSFailSts 0;
BA_ "GenSigTimeoutTime_GNMM" SG_ 1448 EMSFailSts 0;
BA_ "GenSigTimeoutTime_EVCU2" SG_ 1448 EMSFailSts 0;
BA_ "GenSigTimeoutTime_ESL" SG_ 1448 EMSFailSts 0;
BA_ "GenSigTimeoutTime_SGW" SG_ 264 LwsAngle 0;
BA_ "GenSigTimeoutTime_RFHM" SG_ 264 LwsAngle 0;
BA_ "GenSigTimeoutTime_ESL" SG_ 264 LwsAngle 0;
BA_ "GenSigTimeoutTime_ECM" SG_ 264 LwsAngle 0;
BA_ "GenSigTimeoutTime_BCM" SG_ 264 LwsAngle 0;
BA_ "GenSigTimeoutTime_AGSM" SG_ 264 LwsAngle 0;
BA_ "GenSigTimeoutTime_ADCAM" SG_ 264 LwsAngle 0;
BA_ "GenSigTimeoutTime_RFHM" SG_ 1447 TerSt_SWITCH2 0;
BA_ "GenSigTimeoutTime_MPAD" SG_ 1447 TerSt_SWITCH2 0;
BA_ "GenSigTimeoutTime_GNMM" SG_ 1447 TerSt_SWITCH2 0;
BA_ "GenSigTimeoutTime_EVCU2" SG_ 1447 TerSt_SWITCH2 0;
BA_ "GenSigTimeoutTime_ESL" SG_ 1447 TerSt_SWITCH2 0;
BA_ "GenSigTimeoutTime_ECM" SG_ 1447 TerSt_SWITCH2 0;
BA_ "GenSigTimeoutTime_DTCM" SG_ 1447 TerSt_SWITCH2 0;
BA_ "GenSigTimeoutTime_DMSM" SG_ 1447 TerSt_SWITCH2 0;
BA_ "GenSigTimeoutTime_BSM" SG_ 1447 TerSt_SWITCH2 0;
BA_ "GenSigTimeoutTime_AGSM" SG_ 1447 TerSt_SWITCH2 0;
BA_ "GenSigTimeoutTime_ADCAM" SG_ 1447 TerSt_SWITCH2 0;
BA_ "GenSigSendType" SG_ 1447 TerSt_SWITCH2 3;
BA_ "GenSigTimeoutTime_RFHM" SG_ 1447 TerSt_SWITCH1 0;
BA_ "GenSigTimeoutTime_MPAD" SG_ 1447 TerSt_SWITCH1 0;
BA_ "GenSigTimeoutTime_GNMM" SG_ 1447 TerSt_SWITCH1 0;
BA_ "GenSigTimeoutTime_EVCU2" SG_ 1447 TerSt_SWITCH1 0;
BA_ "GenSigTimeoutTime_ESL" SG_ 1447 TerSt_SWITCH1 0;
BA_ "GenSigTimeoutTime_ECM" SG_ 1447 TerSt_SWITCH1 0;
BA_ "GenSigTimeoutTime_DTCM" SG_ 1447 TerSt_SWITCH1 0;
BA_ "GenSigTimeoutTime_DMSM" SG_ 1447 TerSt_SWITCH1 0;
BA_ "GenSigTimeoutTime_BSM" SG_ 1447 TerSt_SWITCH1 0;
BA_ "GenSigTimeoutTime_AGSM" SG_ 1447 TerSt_SWITCH1 0;
BA_ "GenSigTimeoutTime_ADCAM" SG_ 1447 TerSt_SWITCH1 0;
BA_ "GenSigSendType" SG_ 1447 TerSt_SWITCH1 3;
BA_ "GenSigTimeoutTime_SGW" SG_ 1447 DTCM_HMI_Rq 0;
BA_ "GenSigTimeoutTime_RFHM" SG_ 1447 DTCM_HMI_Rq 0;
BA_ "GenSigTimeoutTime_MPAD" SG_ 1447 DTCM_HMI_Rq 0;
BA_ "GenSigTimeoutTime_GNMM" SG_ 1447 DTCM_HMI_Rq 0;
BA_ "GenSigTimeoutTime_EVCU2" SG_ 1447 DTCM_HMI_Rq 0;
BA_ "GenSigTimeoutTime_ESL" SG_ 1447 DTCM_HMI_Rq 0;
BA_ "GenSigTimeoutTime_ECM" SG_ 1447 DTCM_HMI_Rq 0;
BA_ "GenSigTimeoutTime_DTCM" SG_ 1447 DTCM_HMI_Rq 0;
BA_ "GenSigTimeoutTime_DMSM" SG_ 1447 DTCM_HMI_Rq 0;
BA_ "GenSigTimeoutTime_BSM" SG_ 1447 DTCM_HMI_Rq 0;
BA_ "GenSigTimeoutTime_BCM" SG_ 1447 DTCM_HMI_Rq 0;
BA_ "GenSigTimeoutTime_AGSM" SG_ 1447 DTCM_HMI_Rq 0;
BA_ "GenSigTimeoutTime_ADCAM" SG_ 1447 DTCM_HMI_Rq 0;
BA_ "GenSigSendType" SG_ 1447 DTCM_HMI_Rq 3;
BA_ "GenSigTimeoutTime_RFHM" SG_ 517 Ft_RrCouplingTrq_Desired 0;
BA_ "GenSigTimeoutTime_MPAD" SG_ 517 Ft_RrCouplingTrq_Desired 0;
BA_ "GenSigTimeoutTime_IPC" SG_ 517 Ft_RrCouplingTrq_Desired 0;
BA_ "GenSigTimeoutTime_GNMM" SG_ 517 Ft_RrCouplingTrq_Desired 0;
BA_ "GenSigTimeoutTime_ESL" SG_ 517 Ft_RrCouplingTrq_Desired 0;
BA_ "GenSigTimeoutTime_ECM" SG_ 517 Ft_RrCouplingTrq_Desired 0;
BA_ "GenSigTimeoutTime_DTCM" SG_ 517 Ft_RrCouplingTrq_Desired 0;
BA_ "GenSigTimeoutTime_DMSM" SG_ 517 Ft_RrCouplingTrq_Desired 0;
BA_ "GenSigTimeoutTime_BSM" SG_ 517 Ft_RrCouplingTrq_Desired 0;
BA_ "GenSigTimeoutTime_BCM" SG_ 517 Ft_RrCouplingTrq_Desired 0;
BA_ "GenSigTimeoutTime_AGSM" SG_ 517 Ft_RrCouplingTrq_Desired 0;
BA_ "GenSigTimeoutTime_ADCAM" SG_ 517 Ft_RrCouplingTrq_Desired 0;
BA_ "GenSigStartValue" SG_ 517 Ft_RrCouplingTrq_Desired 255;
BA_ "GenSigTimeoutTime_SGW" SG_ 517 DrvLnMinTrqMd 0;
BA_ "GenSigTimeoutTime_RFHM" SG_ 517 DrvLnMinTrqMd 0;
BA_ "GenSigTimeoutTime_MPAD" SG_ 517 DrvLnMinTrqMd 0;
BA_ "GenSigTimeoutTime_IPC" SG_ 517 DrvLnMinTrqMd 0;
BA_ "GenSigTimeoutTime_GNMM" SG_ 517 DrvLnMinTrqMd 0;
BA_ "GenSigTimeoutTime_ESL" SG_ 517 DrvLnMinTrqMd 0;
BA_ "GenSigTimeoutTime_ECM" SG_ 517 DrvLnMinTrqMd 0;
BA_ "GenSigTimeoutTime_DTCM" SG_ 517 DrvLnMinTrqMd 0;
BA_ "GenSigTimeoutTime_DMSM" SG_ 517 DrvLnMinTrqMd 0;
BA_ "GenSigTimeoutTime_BSM" SG_ 517 DrvLnMinTrqMd 0;
BA_ "GenSigTimeoutTime_BCM" SG_ 517 DrvLnMinTrqMd 0;
BA_ "GenSigTimeoutTime_AGSM" SG_ 517 DrvLnMinTrqMd 0;
BA_ "GenSigTimeoutTime_ADCAM" SG_ 517 DrvLnMinTrqMd 0;
BA_ "GenSigTimeoutTime_DMSM" SG_ 517 AWDSysStat 0;
BA_ "GenSigTimeoutTime_AGSM" SG_ 517 AWDSysStat 0;
BA_ "GenSigTimeoutTime_ADCAM" SG_ 517 AWDSysStat 0;
BA_ "GenSigStartValue" SG_ 517 AWDSysStat 7;
BA_ "GenSigTimeoutTime_MPAD" SG_ 517 AWDSysStat 0;
BA_ "GenSigTimeoutTime_GNMM" SG_ 517 AWDSysStat 0;
BA_ "GenSigTimeoutTime_ESL" SG_ 517 AWDSysStat 0;
BA_ "GenSigTimeoutTime_ECM" SG_ 517 AWDSysStat 0;
BA_ "GenSigTimeoutTime_RFHM" SG_ 517 Ft_RrCouplingTrq_Actual 0;
BA_ "GenSigTimeoutTime_MPAD" SG_ 517 Ft_RrCouplingTrq_Actual 0;
BA_ "GenSigTimeoutTime_IPC" SG_ 517 Ft_RrCouplingTrq_Actual 0;
BA_ "GenSigTimeoutTime_GNMM" SG_ 517 Ft_RrCouplingTrq_Actual 0;
BA_ "GenSigTimeoutTime_ESL" SG_ 517 Ft_RrCouplingTrq_Actual 0;
BA_ "GenSigTimeoutTime_ECM" SG_ 517 Ft_RrCouplingTrq_Actual 0;
BA_ "GenSigTimeoutTime_DTCM" SG_ 517 Ft_RrCouplingTrq_Actual 0;
BA_ "GenSigTimeoutTime_DMSM" SG_ 517 Ft_RrCouplingTrq_Actual 0;
BA_ "GenSigTimeoutTime_BCM" SG_ 517 Ft_RrCouplingTrq_Actual 0;
BA_ "GenSigTimeoutTime_AGSM" SG_ 517 Ft_RrCouplingTrq_Actual 0;
BA_ "GenSigTimeoutTime_ADCAM" SG_ 517 Ft_RrCouplingTrq_Actual 0;
BA_ "GenSigStartValue" SG_ 517 Ft_RrCouplingTrq_Actual 255;
BA_ "GenSigTimeoutTime_RFHM" SG_ 517 CCMFailSts 0;
BA_ "GenSigTimeoutTime_MPAD" SG_ 517 CCMFailSts 0;
BA_ "GenSigTimeoutTime_GNMM" SG_ 517 CCMFailSts 0;
BA_ "GenSigTimeoutTime_ESL" SG_ 517 CCMFailSts 0;
BA_ "GenSigTimeoutTime_ECM" SG_ 517 CCMFailSts 0;
BA_ "GenSigTimeoutTime_DTCM" SG_ 517 CCMFailSts 0;
BA_ "GenSigTimeoutTime_DMSM" SG_ 517 CCMFailSts 0;
BA_ "GenSigTimeoutTime_BCM" SG_ 517 CCMFailSts 0;
BA_ "GenSigTimeoutTime_AGSM" SG_ 517 CCMFailSts 0;
BA_ "GenSigTimeoutTime_ADCAM" SG_ 517 CCMFailSts 0;
BA_ "GenSigTimeoutTime_SGW" SG_ 2564682015 N_PDU 0;
BA_ "GenSigTimeoutTime_RFHM" SG_ 2564682015 N_PDU 0;
BA_ "GenSigTimeoutTime_MPAD" SG_ 2564682015 N_PDU 0;
BA_ "GenSigTimeoutTime_IPC" SG_ 2564682015 N_PDU 0;
BA_ "GenSigTimeoutTime_GNMM" SG_ 2564682015 N_PDU 0;
BA_ "GenSigTimeoutTime_EVCU2" SG_ 2564682015 N_PDU 0;
BA_ "GenSigTimeoutTime_ESL" SG_ 2564682015 N_PDU 0;
BA_ "GenSigTimeoutTime_ECM" SG_ 2564682015 N_PDU 0;
BA_ "GenSigTimeoutTime_DTCM" SG_ 2564682015 N_PDU 0;
BA_ "GenSigTimeoutTime_DMSM" SG_ 2564682015 N_PDU 0;
BA_ "GenSigTimeoutTime_BSM" SG_ 2564682015 N_PDU 0;
BA_ "GenSigTimeoutTime_BCM" SG_ 2564682015 N_PDU 0;
BA_ "GenSigTimeoutTime_AGSM" SG_ 2564682015 N_PDU 0;
BA_ "GenSigTimeoutTime_ADCAM" SG_ 2564682015 N_PDU 0;
BA_ "GenSigTimeoutTime_BCM" SG_ 1068 DTCM_Vehicle_Hold_Rq 0;
BA_ "GenSigTimeoutTime_AGSM" SG_ 1068 DTCM_Vehicle_Hold_Rq 0;
BA_ "GenSigTimeoutTime_ADCAM" SG_ 1068 DTCM_Vehicle_Hold_Rq 0;
BA_ "GenSigSendType" SG_ 1068 DTCM_Vehicle_Hold_Rq 3;
BA_ "GenSigTimeoutTime_SGW" SG_ 2564682183 N_PDU 0;
BA_ "GenSigTimeoutTime_RFHM" SG_ 2564682183 N_PDU 0;
BA_ "GenSigTimeoutTime_MPAD" SG_ 2564682183 N_PDU 0;
BA_ "GenSigTimeoutTime_IPC" SG_ 2564682183 N_PDU 0;
BA_ "GenSigTimeoutTime_GNMM" SG_ 2564682183 N_PDU 0;
BA_ "GenSigTimeoutTime_EVCU2" SG_ 2564682183 N_PDU 0;
BA_ "GenSigTimeoutTime_ESL" SG_ 2564682183 N_PDU 0;
BA_ "GenSigTimeoutTime_ECM" SG_ 2564682183 N_PDU 0;
BA_ "GenSigTimeoutTime_DTCM" SG_ 2564682183 N_PDU 0;
BA_ "GenSigTimeoutTime_DMSM" SG_ 2564682183 N_PDU 0;
BA_ "GenSigTimeoutTime_BSM" SG_ 2564682183 N_PDU 0;
BA_ "GenSigTimeoutTime_BCM" SG_ 2564682183 N_PDU 0;
BA_ "GenSigTimeoutTime_AGSM" SG_ 2564682183 N_PDU 0;
BA_ "GenSigTimeoutTime_ADCAM" SG_ 2564682183 N_PDU 0;
BA_ "GenSigTimeoutTime_SGW" SG_ 2564682080 N_PDU 0;
BA_ "GenSigTimeoutTime_RFHM" SG_ 2564682080 N_PDU 0;
BA_ "GenSigTimeoutTime_MPAD" SG_ 2564682080 N_PDU 0;
BA_ "GenSigTimeoutTime_IPC" SG_ 2564682080 N_PDU 0;
BA_ "GenSigTimeoutTime_GNMM" SG_ 2564682080 N_PDU 0;
BA_ "GenSigTimeoutTime_EVCU2" SG_ 2564682080 N_PDU 0;
BA_ "GenSigTimeoutTime_ESL" SG_ 2564682080 N_PDU 0;
BA_ "GenSigTimeoutTime_ECM" SG_ 2564682080 N_PDU 0;
BA_ "GenSigTimeoutTime_DTCM" SG_ 2564682080 N_PDU 0;
BA_ "GenSigTimeoutTime_DMSM" SG_ 2564682080 N_PDU 0;
BA_ "GenSigTimeoutTime_BSM" SG_ 2564682080 N_PDU 0;
BA_ "GenSigTimeoutTime_BCM" SG_ 2564682080 N_PDU 0;
BA_ "GenSigTimeoutTime_AGSM" SG_ 2564682080 N_PDU 0;
BA_ "GenSigTimeoutTime_ADCAM" SG_ 2564682080 N_PDU 0;
BA_ "GenSigTimeoutTime_SGW" SG_ 2564682256 N_PDU 0;
BA_ "GenSigTimeoutTime_RFHM" SG_ 2564682256 N_PDU 0;
BA_ "GenSigTimeoutTime_MPAD" SG_ 2564682256 N_PDU 0;
BA_ "GenSigTimeoutTime_IPC" SG_ 2564682256 N_PDU 0;
BA_ "GenSigTimeoutTime_GNMM" SG_ 2564682256 N_PDU 0;
BA_ "GenSigTimeoutTime_EVCU2" SG_ 2564682256 N_PDU 0;
BA_ "GenSigTimeoutTime_ESL" SG_ 2564682256 N_PDU 0;
BA_ "GenSigTimeoutTime_ECM" SG_ 2564682256 N_PDU 0;
BA_ "GenSigTimeoutTime_DTCM" SG_ 2564682256 N_PDU 0;
BA_ "GenSigTimeoutTime_DMSM" SG_ 2564682256 N_PDU 0;
BA_ "GenSigTimeoutTime_BSM" SG_ 2564682256 N_PDU 0;
BA_ "GenSigTimeoutTime_BCM" SG_ 2564682256 N_PDU 0;
BA_ "GenSigTimeoutTime_AGSM" SG_ 2564682256 N_PDU 0;
BA_ "GenSigTimeoutTime_ADCAM" SG_ 2564682256 N_PDU 0;
BA_ "GenSigTimeoutTime_SGW" SG_ 2564682266 N_PDU 0;
BA_ "GenSigTimeoutTime_RFHM" SG_ 2564682266 N_PDU 0;
BA_ "GenSigTimeoutTime_MPAD" SG_ 2564682266 N_PDU 0;
BA_ "GenSigTimeoutTime_IPC" SG_ 2564682266 N_PDU 0;
BA_ "GenSigTimeoutTime_GNMM" SG_ 2564682266 N_PDU 0;
BA_ "GenSigTimeoutTime_EVCU2" SG_ 2564682266 N_PDU 0;
BA_ "GenSigTimeoutTime_ESL" SG_ 2564682266 N_PDU 0;
BA_ "GenSigTimeoutTime_ECM" SG_ 2564682266 N_PDU 0;
BA_ "GenSigTimeoutTime_DTCM" SG_ 2564682266 N_PDU 0;
BA_ "GenSigTimeoutTime_DMSM" SG_ 2564682266 N_PDU 0;
BA_ "GenSigTimeoutTime_BSM" SG_ 2564682266 N_PDU 0;
BA_ "GenSigTimeoutTime_BCM" SG_ 2564682266 N_PDU 0;
BA_ "GenSigTimeoutTime_AGSM" SG_ 2564682266 N_PDU 0;
BA_ "GenSigTimeoutTime_ADCAM" SG_ 2564682266 N_PDU 0;
BA_ "GenSigTimeoutTime_SGW" SG_ 2564682000 N_PDU 0;
BA_ "GenSigTimeoutTime_RFHM" SG_ 2564682000 N_PDU 0;
BA_ "GenSigTimeoutTime_MPAD" SG_ 2564682000 N_PDU 0;
BA_ "GenSigTimeoutTime_IPC" SG_ 2564682000 N_PDU 0;
BA_ "GenSigTimeoutTime_GNMM" SG_ 2564682000 N_PDU 0;
BA_ "GenSigTimeoutTime_EVCU2" SG_ 2564682000 N_PDU 0;
BA_ "GenSigTimeoutTime_ESL" SG_ 2564682000 N_PDU 0;
BA_ "GenSigTimeoutTime_ECM" SG_ 2564682000 N_PDU 0;
BA_ "GenSigTimeoutTime_DTCM" SG_ 2564682000 N_PDU 0;
BA_ "GenSigTimeoutTime_DMSM" SG_ 2564682000 N_PDU 0;
BA_ "GenSigTimeoutTime_BSM" SG_ 2564682000 N_PDU 0;
BA_ "GenSigTimeoutTime_BCM" SG_ 2564682000 N_PDU 0;
BA_ "GenSigTimeoutTime_AGSM" SG_ 2564682000 N_PDU 0;
BA_ "GenSigTimeoutTime_ADCAM" SG_ 2564682000 N_PDU 0;
BA_ "GenSigTimeoutTime_SGW" SG_ 2564682010 N_PDU 0;
BA_ "GenSigTimeoutTime_RFHM" SG_ 2564682010 N_PDU 0;
BA_ "GenSigTimeoutTime_MPAD" SG_ 2564682010 N_PDU 0;
BA_ "GenSigTimeoutTime_IPC" SG_ 2564682010 N_PDU 0;
BA_ "GenSigTimeoutTime_GNMM" SG_ 2564682010 N_PDU 0;
BA_ "GenSigTimeoutTime_EVCU2" SG_ 2564682010 N_PDU 0;
BA_ "GenSigTimeoutTime_ESL" SG_ 2564682010 N_PDU 0;
BA_ "GenSigTimeoutTime_ECM" SG_ 2564682010 N_PDU 0;
BA_ "GenSigTimeoutTime_DTCM" SG_ 2564682010 N_PDU 0;
BA_ "GenSigTimeoutTime_DMSM" SG_ 2564682010 N_PDU 0;
BA_ "GenSigTimeoutTime_BSM" SG_ 2564682010 N_PDU 0;
BA_ "GenSigTimeoutTime_BCM" SG_ 2564682010 N_PDU 0;
BA_ "GenSigTimeoutTime_AGSM" SG_ 2564682010 N_PDU 0;
BA_ "GenSigTimeoutTime_ADCAM" SG_ 2564682010 N_PDU 0;
BA_ "GenSigTimeoutTime_SGW" SG_ 2564682024 N_PDU 0;
BA_ "GenSigTimeoutTime_RFHM" SG_ 2564682024 N_PDU 0;
BA_ "GenSigTimeoutTime_MPAD" SG_ 2564682024 N_PDU 0;
BA_ "GenSigTimeoutTime_IPC" SG_ 2564682024 N_PDU 0;
BA_ "GenSigTimeoutTime_GNMM" SG_ 2564682024 N_PDU 0;
BA_ "GenSigTimeoutTime_EVCU2" SG_ 2564682024 N_PDU 0;
BA_ "GenSigTimeoutTime_ESL" SG_ 2564682024 N_PDU 0;
BA_ "GenSigTimeoutTime_ECM" SG_ 2564682024 N_PDU 0;
BA_ "GenSigTimeoutTime_DTCM" SG_ 2564682024 N_PDU 0;
BA_ "GenSigTimeoutTime_DMSM" SG_ 2564682024 N_PDU 0;
BA_ "GenSigTimeoutTime_BSM" SG_ 2564682024 N_PDU 0;
BA_ "GenSigTimeoutTime_BCM" SG_ 2564682024 N_PDU 0;
BA_ "GenSigTimeoutTime_AGSM" SG_ 2564682024 N_PDU 0;
BA_ "GenSigTimeoutTime_ADCAM" SG_ 2564682024 N_PDU 0;
BA_ "GenSigTimeoutTime_SGW" SG_ 2564682180 N_PDU 0;
BA_ "GenSigTimeoutTime_RFHM" SG_ 2564682180 N_PDU 0;
BA_ "GenSigTimeoutTime_MPAD" SG_ 2564682180 N_PDU 0;
BA_ "GenSigTimeoutTime_IPC" SG_ 2564682180 N_PDU 0;
BA_ "GenSigTimeoutTime_GNMM" SG_ 2564682180 N_PDU 0;
BA_ "GenSigTimeoutTime_EVCU2" SG_ 2564682180 N_PDU 0;
BA_ "GenSigTimeoutTime_ESL" SG_ 2564682180 N_PDU 0;
BA_ "GenSigTimeoutTime_ECM" SG_ 2564682180 N_PDU 0;
BA_ "GenSigTimeoutTime_DTCM" SG_ 2564682180 N_PDU 0;
BA_ "GenSigTimeoutTime_DMSM" SG_ 2564682180 N_PDU 0;
BA_ "GenSigTimeoutTime_BSM" SG_ 2564682180 N_PDU 0;
BA_ "GenSigTimeoutTime_BCM" SG_ 2564682180 N_PDU 0;
BA_ "GenSigTimeoutTime_AGSM" SG_ 2564682180 N_PDU 0;
BA_ "GenSigTimeoutTime_ADCAM" SG_ 2564682180 N_PDU 0;
BA_ "GenSigTimeoutTime_SGW" SG_ 2564485663 N_PDU 0;
BA_ "GenSigTimeoutTime_RFHM" SG_ 2564485663 N_PDU 0;
BA_ "GenSigTimeoutTime_MPAD" SG_ 2564485663 N_PDU 0;
BA_ "GenSigTimeoutTime_IPC" SG_ 2564485663 N_PDU 0;
BA_ "GenSigTimeoutTime_GNMM" SG_ 2564485663 N_PDU 0;
BA_ "GenSigTimeoutTime_EVCU2" SG_ 2564485663 N_PDU 0;
BA_ "GenSigTimeoutTime_ESL" SG_ 2564485663 N_PDU 0;
BA_ "GenSigTimeoutTime_ECM" SG_ 2564485663 N_PDU 0;
BA_ "GenSigTimeoutTime_DTCM" SG_ 2564485663 N_PDU 0;
BA_ "GenSigTimeoutTime_DMSM" SG_ 2564485663 N_PDU 0;
BA_ "GenSigTimeoutTime_BSM" SG_ 2564485663 N_PDU 0;
BA_ "GenSigTimeoutTime_BCM" SG_ 2564485663 N_PDU 0;
BA_ "GenSigTimeoutTime_AGSM" SG_ 2564485663 N_PDU 0;
BA_ "GenSigTimeoutTime_ADCAM" SG_ 2564485663 N_PDU 0;
BA_ "GenSigTimeoutTime_SGW" SG_ 2564485831 N_PDU 0;
BA_ "GenSigTimeoutTime_RFHM" SG_ 2564485831 N_PDU 0;
BA_ "GenSigTimeoutTime_MPAD" SG_ 2564485831 N_PDU 0;
BA_ "GenSigTimeoutTime_IPC" SG_ 2564485831 N_PDU 0;
BA_ "GenSigTimeoutTime_GNMM" SG_ 2564485831 N_PDU 0;
BA_ "GenSigTimeoutTime_EVCU2" SG_ 2564485831 N_PDU 0;
BA_ "GenSigTimeoutTime_ESL" SG_ 2564485831 N_PDU 0;
BA_ "GenSigTimeoutTime_ECM" SG_ 2564485831 N_PDU 0;
BA_ "GenSigTimeoutTime_DTCM" SG_ 2564485831 N_PDU 0;
BA_ "GenSigTimeoutTime_DMSM" SG_ 2564485831 N_PDU 0;
BA_ "GenSigTimeoutTime_BSM" SG_ 2564485831 N_PDU 0;
BA_ "GenSigTimeoutTime_BCM" SG_ 2564485831 N_PDU 0;
BA_ "GenSigTimeoutTime_AGSM" SG_ 2564485831 N_PDU 0;
BA_ "GenSigTimeoutTime_ADCAM" SG_ 2564485831 N_PDU 0;
BA_ "GenSigTimeoutTime_SGW" SG_ 2564474098 N_PDU 0;
BA_ "GenSigTimeoutTime_RFHM" SG_ 2564474098 N_PDU 0;
BA_ "GenSigTimeoutTime_MPAD" SG_ 2564474098 N_PDU 0;
BA_ "GenSigTimeoutTime_IPC" SG_ 2564474098 N_PDU 0;
BA_ "GenSigTimeoutTime_GNMM" SG_ 2564474098 N_PDU 0;
BA_ "GenSigTimeoutTime_EVCU2" SG_ 2564474098 N_PDU 0;
BA_ "GenSigTimeoutTime_ESL" SG_ 2564474098 N_PDU 0;
BA_ "GenSigTimeoutTime_ECM" SG_ 2564474098 N_PDU 0;
BA_ "GenSigTimeoutTime_SGW" SG_ 2564448498 N_PDU 0;
BA_ "GenSigTimeoutTime_RFHM" SG_ 2564448498 N_PDU 0;
BA_ "GenSigTimeoutTime_MPAD" SG_ 2564448498 N_PDU 0;
BA_ "GenSigTimeoutTime_IPC" SG_ 2564448498 N_PDU 0;
BA_ "GenSigTimeoutTime_GNMM" SG_ 2564448498 N_PDU 0;
BA_ "GenSigTimeoutTime_EVCU2" SG_ 2564448498 N_PDU 0;
BA_ "GenSigTimeoutTime_ESL" SG_ 2564448498 N_PDU 0;
BA_ "GenSigTimeoutTime_ECM" SG_ 2564448498 N_PDU 0;
BA_ "GenSigTimeoutTime_DTCM" SG_ 2564448498 N_PDU 0;
BA_ "GenSigTimeoutTime_DMSM" SG_ 2564448498 N_PDU 0;
BA_ "GenSigTimeoutTime_BSM" SG_ 2564448498 N_PDU 0;
BA_ "GenSigTimeoutTime_BCM" SG_ 2564448498 N_PDU 0;
BA_ "GenSigTimeoutTime_AGSM" SG_ 2564448498 N_PDU 0;
BA_ "GenSigTimeoutTime_ADCAM" SG_ 2564448498 N_PDU 0;
BA_ "GenSigTimeoutTime_MPAD" SG_ 2564554482 N_PDU 0;
BA_ "GenSigTimeoutTime_IPC" SG_ 2564554482 N_PDU 0;
BA_ "GenSigTimeoutTime_GNMM" SG_ 2564554482 N_PDU 0;
BA_ "GenSigTimeoutTime_EVCU2" SG_ 2564554482 N_PDU 0;
BA_ "GenSigTimeoutTime_ESL" SG_ 2564554482 N_PDU 0;
BA_ "GenSigTimeoutTime_ECM" SG_ 2564554482 N_PDU 0;
BA_ "GenSigTimeoutTime_DTCM" SG_ 2564554482 N_PDU 0;
BA_ "GenSigTimeoutTime_DMSM" SG_ 2564554482 N_PDU 0;
BA_ "GenSigTimeoutTime_BSM" SG_ 2564554482 N_PDU 0;
BA_ "GenSigTimeoutTime_BCM" SG_ 2564554482 N_PDU 0;
BA_ "GenSigTimeoutTime_AGSM" SG_ 2564554482 N_PDU 0;
BA_ "GenSigTimeoutTime_ADCAM" SG_ 2564554482 N_PDU 0;
BA_ "GenSigTimeoutTime_SGW" SG_ 2564554482 N_PDU 0;
BA_ "GenSigTimeoutTime_RFHM" SG_ 2564554482 N_PDU 0;
BA_ "GenSigTimeoutTime_SGW" SG_ 2564431858 N_PDU 0;
BA_ "GenSigTimeoutTime_RFHM" SG_ 2564431858 N_PDU 0;
BA_ "GenSigTimeoutTime_MPAD" SG_ 2564431858 N_PDU 0;
BA_ "GenSigTimeoutTime_IPC" SG_ 2564431858 N_PDU 0;
BA_ "GenSigTimeoutTime_GNMM" SG_ 2564431858 N_PDU 0;
BA_ "GenSigTimeoutTime_EVCU2" SG_ 2564431858 N_PDU 0;
BA_ "GenSigTimeoutTime_ESL" SG_ 2564431858 N_PDU 0;
BA_ "GenSigTimeoutTime_ECM" SG_ 2564431858 N_PDU 0;
BA_ "GenSigTimeoutTime_DTCM" SG_ 2564431858 N_PDU 0;
BA_ "GenSigTimeoutTime_DMSM" SG_ 2564431858 N_PDU 0;
BA_ "GenSigTimeoutTime_BSM" SG_ 2564431858 N_PDU 0;
BA_ "GenSigTimeoutTime_BCM" SG_ 2564431858 N_PDU 0;
BA_ "GenSigTimeoutTime_AGSM" SG_ 2564431858 N_PDU 0;
BA_ "GenSigTimeoutTime_ADCAM" SG_ 2564431858 N_PDU 0;
BA_ "GenSigTimeoutTime_SGW" SG_ 2564474866 N_PDU 0;
BA_ "GenSigTimeoutTime_RFHM" SG_ 2564474866 N_PDU 0;
BA_ "GenSigTimeoutTime_MPAD" SG_ 2564474866 N_PDU 0;
BA_ "GenSigTimeoutTime_IPC" SG_ 2564474866 N_PDU 0;
BA_ "GenSigTimeoutTime_GNMM" SG_ 2564474866 N_PDU 0;
BA_ "GenSigTimeoutTime_EVCU2" SG_ 2564474866 N_PDU 0;
BA_ "GenSigTimeoutTime_ESL" SG_ 2564474866 N_PDU 0;
BA_ "GenSigTimeoutTime_ECM" SG_ 2564474866 N_PDU 0;
BA_ "GenSigTimeoutTime_DTCM" SG_ 2564474866 N_PDU 0;
BA_ "GenSigTimeoutTime_DMSM" SG_ 2564474866 N_PDU 0;
BA_ "GenSigTimeoutTime_BSM" SG_ 2564474866 N_PDU 0;
BA_ "GenSigTimeoutTime_BCM" SG_ 2564474866 N_PDU 0;
BA_ "GenSigTimeoutTime_AGSM" SG_ 2564474866 N_PDU 0;
BA_ "GenSigTimeoutTime_ADCAM" SG_ 2564474866 N_PDU 0;
BA_ "GenSigTimeoutTime_GNMM" SG_ 1448 OilPressureSts 0;
BA_ "GenSigTimeoutTime_EVCU2" SG_ 1448 OilPressureSts 0;
BA_ "GenSigTimeoutTime_ESL" SG_ 1448 OilPressureSts 0;
BA_ "GenSigTimeoutTime_ECM" SG_ 1448 OilPressureSts 0;
BA_ "GenSigTimeoutTime_DTCM" SG_ 1448 OilPressureSts 0;
BA_ "GenSigTimeoutTime_DMSM" SG_ 1448 OilPressureSts 0;
BA_ "GenSigTimeoutTime_BSM" SG_ 1448 OilPressureSts 0;
BA_ "GenSigTimeoutTime_AGSM" SG_ 1448 OilPressureSts 0;
BA_ "GenSigTimeoutTime_ADCAM" SG_ 1448 OilPressureSts 0;
BA_ "GenSigSendType" SG_ 1448 OilPressureSts 3;
BA_ "GenSigStartValue" SG_ 1448 OilPressureSts 1;
BA_ "GenSigTimeoutTime_SGW" SG_ 264 EngineFanRequestActivation 0;
BA_ "GenSigTimeoutTime_RFHM" SG_ 264 EngineFanRequestActivation 0;
BA_ "GenSigTimeoutTime_IPC" SG_ 264 EngineFanRequestActivation 0;
BA_ "GenSigTimeoutTime_GNMM" SG_ 264 EngineFanRequestActivation 0;
BA_ "GenSigTimeoutTime_EVCU2" SG_ 264 EngineFanRequestActivation 0;
BA_ "GenSigTimeoutTime_ESL" SG_ 264 EngineFanRequestActivation 0;
BA_ "GenSigTimeoutTime_ECM" SG_ 264 EngineFanRequestActivation 0;
BA_ "GenSigTimeoutTime_DTCM" SG_ 264 EngineFanRequestActivation 0;
BA_ "GenSigTimeoutTime_DMSM" SG_ 264 EngineFanRequestActivation 0;
BA_ "GenSigTimeoutTime_BCM" SG_ 264 EngineFanRequestActivation 0;
BA_ "GenSigTimeoutTime_AGSM" SG_ 264 EngineFanRequestActivation 0;
BA_ "GenSigTimeoutTime_ADCAM" SG_ 264 EngineFanRequestActivation 0;
BA_ "GenSigTimeoutTime_SGW" SG_ 1055 MessageCounter_ENGINE8 0;
BA_ "GenSigTimeoutTime_RFHM" SG_ 1055 MessageCounter_ENGINE8 0;
BA_ "GenSigTimeoutTime_MPAD" SG_ 1055 MessageCounter_ENGINE8 0;
BA_ "GenSigTimeoutTime_IPC" SG_ 1055 MessageCounter_ENGINE8 0;
BA_ "GenSigTimeoutTime_GNMM" SG_ 1055 MessageCounter_ENGINE8 0;
BA_ "GenSigTimeoutTime_ESL" SG_ 1055 MessageCounter_ENGINE8 0;
BA_ "GenSigTimeoutTime_ECM" SG_ 1055 MessageCounter_ENGINE8 0;
BA_ "GenSigTimeoutTime_DTCM" SG_ 1055 MessageCounter_ENGINE8 0;
BA_ "GenSigTimeoutTime_DMSM" SG_ 1055 MessageCounter_ENGINE8 0;
BA_ "GenSigTimeoutTime_BSM" SG_ 1055 MessageCounter_ENGINE8 0;
BA_ "GenSigTimeoutTime_BCM" SG_ 1055 MessageCounter_ENGINE8 0;
BA_ "GenSigTimeoutTime_AGSM" SG_ 1055 MessageCounter_ENGINE8 0;
BA_ "GenSigTimeoutTime_ADCAM" SG_ 1055 MessageCounter_ENGINE8 0;
BA_ "GenSigTimeoutTime_SGW" SG_ 1055 CRC_ENGINE8 0;
BA_ "GenSigTimeoutTime_RFHM" SG_ 1055 CRC_ENGINE8 0;
BA_ "GenSigTimeoutTime_MPAD" SG_ 1055 CRC_ENGINE8 0;
BA_ "GenSigTimeoutTime_IPC" SG_ 1055 CRC_ENGINE8 0;
BA_ "GenSigTimeoutTime_GNMM" SG_ 1055 CRC_ENGINE8 0;
BA_ "GenSigTimeoutTime_ESL" SG_ 1055 CRC_ENGINE8 0;
BA_ "GenSigTimeoutTime_ECM" SG_ 1055 CRC_ENGINE8 0;
BA_ "GenSigTimeoutTime_DTCM" SG_ 1055 CRC_ENGINE8 0;
BA_ "GenSigTimeoutTime_DMSM" SG_ 1055 CRC_ENGINE8 0;
BA_ "GenSigTimeoutTime_BSM" SG_ 1055 CRC_ENGINE8 0;
BA_ "GenSigTimeoutTime_BCM" SG_ 1055 CRC_ENGINE8 0;
BA_ "GenSigTimeoutTime_AGSM" SG_ 1055 CRC_ENGINE8 0;
BA_ "GenSigTimeoutTime_ADCAM" SG_ 1055 CRC_ENGINE8 0;
BA_ "GenSigTimeoutTime_SGW" SG_ 264 ElectricSteeringFailSts 0;
BA_ "GenSigTimeoutTime_RFHM" SG_ 264 ElectricSteeringFailSts 0;
BA_ "GenSigTimeoutTime_IPC" SG_ 264 ElectricSteeringFailSts 0;
BA_ "GenSigTimeoutTime_GNMM" SG_ 264 ElectricSteeringFailSts 0;
BA_ "GenSigTimeoutTime_EVCU2" SG_ 264 ElectricSteeringFailSts 0;
BA_ "GenSigTimeoutTime_ESL" SG_ 264 ElectricSteeringFailSts 0;
BA_ "GenSigTimeoutTime_ECM" SG_ 264 ElectricSteeringFailSts 0;
BA_ "GenSigTimeoutTime_DMSM" SG_ 264 ElectricSteeringFailSts 0;
BA_ "GenSigTimeoutTime_BCM" SG_ 264 ElectricSteeringFailSts 0;
BA_ "GenSigTimeoutTime_AGSM" SG_ 264 ElectricSteeringFailSts 0;
BA_ "GenSigTimeoutTime_ADCAM" SG_ 264 ElectricSteeringFailSts 0;
BA_ "GenSigTimeoutTime_SGW" SG_ 1448 ExhaustTemperature 0;
BA_ "GenSigTimeoutTime_RFHM" SG_ 1448 ExhaustTemperature 0;
BA_ "GenSigTimeoutTime_MPAD" SG_ 1448 ExhaustTemperature 0;
BA_ "GenSigTimeoutTime_IPC" SG_ 1448 ExhaustTemperature 0;
BA_ "GenSigTimeoutTime_GNMM" SG_ 1448 ExhaustTemperature 0;
BA_ "GenSigTimeoutTime_EVCU2" SG_ 1448 ExhaustTemperature 0;
BA_ "GenSigTimeoutTime_ESL" SG_ 1448 ExhaustTemperature 0;
BA_ "GenSigTimeoutTime_ECM" SG_ 1448 ExhaustTemperature 0;
BA_ "GenSigTimeoutTime_DTCM" SG_ 1448 ExhaustTemperature 0;
BA_ "GenSigTimeoutTime_DMSM" SG_ 1448 ExhaustTemperature 0;
BA_ "GenSigTimeoutTime_BSM" SG_ 1448 ExhaustTemperature 0;
BA_ "GenSigTimeoutTime_BCM" SG_ 1448 ExhaustTemperature 0;
BA_ "GenSigTimeoutTime_AGSM" SG_ 1448 ExhaustTemperature 0;
BA_ "GenSigTimeoutTime_ADCAM" SG_ 1448 ExhaustTemperature 0;
BA_ "GenSigSendType" SG_ 1448 ExhaustTemperature 3;
BA_ "GenSigTimeoutTime_SGW" SG_ 1448 ETCFailSts 0;
BA_ "GenSigTimeoutTime_RFHM" SG_ 1448 ETCFailSts 0;
BA_ "GenSigTimeoutTime_MPAD" SG_ 1448 ETCFailSts 0;
BA_ "GenSigTimeoutTime_GNMM" SG_ 1448 ETCFailSts 0;
BA_ "GenSigTimeoutTime_EVCU2" SG_ 1448 ETCFailSts 0;
BA_ "GenSigTimeoutTime_ESL" SG_ 1448 ETCFailSts 0;
BA_ "GenSigTimeoutTime_ECM" SG_ 1448 ETCFailSts 0;
BA_ "GenSigTimeoutTime_DTCM" SG_ 1448 ETCFailSts 0;
BA_ "GenSigTimeoutTime_GNMM" SG_ 1155 EBDFailSts 0;
BA_ "GenSigTimeoutTime_EVCU2" SG_ 1155 EBDFailSts 0;
BA_ "GenSigTimeoutTime_ESL" SG_ 1155 EBDFailSts 0;
BA_ "GenSigTimeoutTime_ECM" SG_ 1155 EBDFailSts 0;
BA_ "GenSigTimeoutTime_DTCM" SG_ 1155 EBDFailSts 0;
BA_ "GenSigTimeoutTime_DMSM" SG_ 1155 EBDFailSts 0;
BA_ "GenSigTimeoutTime_BSM" SG_ 1155 EBDFailSts 0;
BA_ "GenSigTimeoutTime_AGSM" SG_ 1155 EBDFailSts 0;
BA_ "GenSigTimeoutTime_ADCAM" SG_ 1155 EBDFailSts 0;
BA_ "GenSigSendType" SG_ 1155 EBDFailSts 3;
BA_ "GenSigTimeoutTime_RFHM" SG_ 1155 ESCFailSts 0;
BA_ "GenSigTimeoutTime_GNMM" SG_ 1155 ESCFailSts 0;
BA_ "GenSigTimeoutTime_ESL" SG_ 1155 ESCFailSts 0;
BA_ "GenSigTimeoutTime_ECM" SG_ 1155 ESCFailSts 0;
BA_ "GenSigTimeoutTime_DMSM" SG_ 1155 ESCFailSts 0;
BA_ "GenSigTimeoutTime_BSM" SG_ 1155 ESCFailSts 0;
BA_ "GenSigTimeoutTime_AGSM" SG_ 1155 ESCFailSts 0;
BA_ "GenSigTimeoutTime_ADCAM" SG_ 1155 ESCFailSts 0;
BA_ "GenSigSendType" SG_ 1155 ESCFailSts 3;
BA_ "GenSigTimeoutTime_SGW" SG_ 1155 ERMActive 0;
BA_ "GenSigTimeoutTime_RFHM" SG_ 1155 ERMActive 0;
BA_ "GenSigTimeoutTime_MPAD" SG_ 1155 ERMActive 0;
BA_ "GenSigTimeoutTime_IPC" SG_ 1155 ERMActive 0;
BA_ "GenSigTimeoutTime_GNMM" SG_ 1155 ERMActive 0;
BA_ "GenSigTimeoutTime_EVCU2" SG_ 1155 ERMActive 0;
BA_ "GenSigTimeoutTime_ESL" SG_ 1155 ERMActive 0;
BA_ "GenSigTimeoutTime_ECM" SG_ 1155 ERMActive 0;
BA_ "GenSigTimeoutTime_DMSM" SG_ 1155 ERMActive 0;
BA_ "GenSigTimeoutTime_BSM" SG_ 1155 ERMActive 0;
BA_ "GenSigTimeoutTime_AGSM" SG_ 1155 ERMActive 0;
BA_ "GenSigTimeoutTime_ADCAM" SG_ 1155 ERMActive 0;
BA_ "GenSigSendType" SG_ 1155 ERMActive 3;
BA_ "GenSigTimeoutTime_SGW" SG_ 1155 ESCIntervention 0;
BA_ "GenSigTimeoutTime_RFHM" SG_ 1155 ESCIntervention 0;
BA_ "GenSigTimeoutTime_MPAD" SG_ 1155 ESCIntervention 0;
BA_ "GenSigTimeoutTime_GNMM" SG_ 1155 ESCIntervention 0;
BA_ "GenSigTimeoutTime_EVCU2" SG_ 1155 ESCIntervention 0;
BA_ "GenSigTimeoutTime_ESL" SG_ 1155 ESCIntervention 0;
BA_ "GenSigTimeoutTime_ECM" SG_ 1155 ESCIntervention 0;
BA_ "GenSigTimeoutTime_DMSM" SG_ 1155 ESCIntervention 0;
BA_ "GenSigTimeoutTime_BSM" SG_ 1155 ESCIntervention 0;
BA_ "GenSigTimeoutTime_AGSM" SG_ 1155 ESCIntervention 0;
BA_ "GenSigTimeoutTime_ADCAM" SG_ 1155 ESCIntervention 0;
BA_ "GenSigSendType" SG_ 1155 ESCIntervention 3;
BA_ "GenSigTimeoutTime_RFHM" SG_ 1155 Function2Sts 0;
BA_ "GenSigTimeoutTime_GNMM" SG_ 1155 Function2Sts 0;
BA_ "GenSigTimeoutTime_EVCU2" SG_ 1155 Function2Sts 0;
BA_ "GenSigTimeoutTime_ESL" SG_ 1155 Function2Sts 0;
BA_ "GenSigTimeoutTime_ECM" SG_ 1155 Function2Sts 0;
BA_ "GenSigTimeoutTime_DMSM" SG_ 1155 Function2Sts 0;
BA_ "GenSigTimeoutTime_BSM" SG_ 1155 Function2Sts 0;
BA_ "GenSigTimeoutTime_AGSM" SG_ 1155 Function2Sts 0;
BA_ "GenSigTimeoutTime_ADCAM" SG_ 1155 Function2Sts 0;
BA_ "GenSigSendType" SG_ 1155 Function2Sts 3;
BA_ "GenSigTimeoutTime_SGW" SG_ 1155 FunctionFailSts 0;
BA_ "GenSigTimeoutTime_RFHM" SG_ 1155 FunctionFailSts 0;
BA_ "GenSigTimeoutTime_MPAD" SG_ 1155 FunctionFailSts 0;
BA_ "GenSigTimeoutTime_IPC" SG_ 1155 FunctionFailSts 0;
BA_ "GenSigTimeoutTime_GNMM" SG_ 1155 FunctionFailSts 0;
BA_ "GenSigTimeoutTime_EVCU2" SG_ 1155 FunctionFailSts 0;
BA_ "GenSigTimeoutTime_ESL" SG_ 1155 FunctionFailSts 0;
BA_ "GenSigTimeoutTime_ECM" SG_ 1155 FunctionFailSts 0;
BA_ "GenSigTimeoutTime_DMSM" SG_ 1155 FunctionFailSts 0;
BA_ "GenSigTimeoutTime_BSM" SG_ 1155 FunctionFailSts 0;
BA_ "GenSigTimeoutTime_BCM" SG_ 1155 FunctionFailSts 0;
BA_ "GenSigTimeoutTime_AGSM" SG_ 1155 FunctionFailSts 0;
BA_ "GenSigTimeoutTime_ADCAM" SG_ 1155 FunctionFailSts 0;
BA_ "GenSigSendType" SG_ 1155 FunctionFailSts 3;
BA_ "GenSigTimeoutTime_SGW" SG_ 1155 FunctionIntervention 0;
BA_ "GenSigTimeoutTime_RFHM" SG_ 1155 FunctionIntervention 0;
BA_ "GenSigTimeoutTime_MPAD" SG_ 1155 FunctionIntervention 0;
BA_ "GenSigTimeoutTime_IPC" SG_ 1155 FunctionIntervention 0;
BA_ "GenSigTimeoutTime_GNMM" SG_ 1155 FunctionIntervention 0;
BA_ "GenSigTimeoutTime_EVCU2" SG_ 1155 FunctionIntervention 0;
BA_ "GenSigTimeoutTime_ESL" SG_ 1155 FunctionIntervention 0;
BA_ "GenSigTimeoutTime_ECM" SG_ 1155 FunctionIntervention 0;
BA_ "GenSigTimeoutTime_DMSM" SG_ 1155 FunctionIntervention 0;
BA_ "GenSigTimeoutTime_BSM" SG_ 1155 FunctionIntervention 0;
BA_ "GenSigTimeoutTime_BCM" SG_ 1155 FunctionIntervention 0;
BA_ "GenSigTimeoutTime_AGSM" SG_ 1155 FunctionIntervention 0;
BA_ "GenSigTimeoutTime_ADCAM" SG_ 1155 FunctionIntervention 0;
BA_ "GenSigSendType" SG_ 1155 FunctionIntervention 3;
BA_ "GenSigTimeoutTime_SGW" SG_ 1155 TSCActive 0;
BA_ "GenSigTimeoutTime_RFHM" SG_ 1155 TSCActive 0;
BA_ "GenSigTimeoutTime_IPC" SG_ 1155 TSCActive 0;
BA_ "GenSigTimeoutTime_GNMM" SG_ 1155 TSCActive 0;
BA_ "GenSigTimeoutTime_EVCU2" SG_ 1155 TSCActive 0;
BA_ "GenSigTimeoutTime_ESL" SG_ 1155 TSCActive 0;
BA_ "GenSigTimeoutTime_ECM" SG_ 1155 TSCActive 0;
BA_ "GenSigTimeoutTime_DTCM" SG_ 1155 TSCActive 0;
BA_ "GenSigTimeoutTime_DMSM" SG_ 1155 TSCActive 0;
BA_ "GenSigTimeoutTime_BSM" SG_ 1155 TSCActive 0;
BA_ "GenSigTimeoutTime_AGSM" SG_ 1155 TSCActive 0;
BA_ "GenSigTimeoutTime_ADCAM" SG_ 1155 TSCActive 0;
BA_ "GenSigSendType" SG_ 1155 TSCActive 3;
BA_ "GenSigTimeoutTime_SGW" SG_ 1155 RollsModeAct 0;
BA_ "GenSigTimeoutTime_RFHM" SG_ 1155 RollsModeAct 0;
BA_ "GenSigTimeoutTime_IPC" SG_ 1155 RollsModeAct 0;
BA_ "GenSigTimeoutTime_GNMM" SG_ 1155 RollsModeAct 0;
BA_ "GenSigTimeoutTime_ESL" SG_ 1155 RollsModeAct 0;
BA_ "GenSigTimeoutTime_ECM" SG_ 1155 RollsModeAct 0;
BA_ "GenSigTimeoutTime_DMSM" SG_ 1155 RollsModeAct 0;
BA_ "GenSigTimeoutTime_BSM" SG_ 1155 RollsModeAct 0;
BA_ "GenSigTimeoutTime_BCM" SG_ 1155 RollsModeAct 0;
BA_ "GenSigTimeoutTime_AGSM" SG_ 1155 RollsModeAct 0;
BA_ "GenSigTimeoutTime_ADCAM" SG_ 1155 RollsModeAct 0;
BA_ "GenSigSendType" SG_ 1155 RollsModeAct 3;
BA_ "GenSigTimeoutTime_IPC" SG_ 1155 ACCEngaged 0;
BA_ "GenSigTimeoutTime_GNMM" SG_ 1155 ACCEngaged 0;
BA_ "GenSigTimeoutTime_ESL" SG_ 1155 ACCEngaged 0;
BA_ "GenSigTimeoutTime_ECM" SG_ 1155 ACCEngaged 0;
BA_ "GenSigTimeoutTime_DTCM" SG_ 1155 ACCEngaged 0;
BA_ "GenSigTimeoutTime_DMSM" SG_ 1155 ACCEngaged 0;
BA_ "GenSigTimeoutTime_BSM" SG_ 1155 ACCEngaged 0;
BA_ "GenSigTimeoutTime_BCM" SG_ 1155 ACCEngaged 0;
BA_ "GenSigTimeoutTime_AGSM" SG_ 1155 ACCEngaged 0;
BA_ "GenSigTimeoutTime_ADCAM" SG_ 1155 ACCEngaged 0;
BA_ "GenSigSendType" SG_ 1155 ACCEngaged 3;
BA_ "GenSigTimeoutTime_RFHM" SG_ 1155 ACCEngaged 0;
BA_ "GenSigTimeoutTime_MPAD" SG_ 1155 ACCEngaged 0;
BA_ "GenSigTimeoutTime_RFHM" SG_ 1155 BSMSysSts 0;
BA_ "GenSigTimeoutTime_MPAD" SG_ 1155 BSMSysSts 0;
BA_ "GenSigTimeoutTime_IPC" SG_ 1155 BSMSysSts 0;
BA_ "GenSigTimeoutTime_GNMM" SG_ 1155 BSMSysSts 0;
BA_ "GenSigTimeoutTime_EVCU2" SG_ 1155 BSMSysSts 0;
BA_ "GenSigTimeoutTime_ESL" SG_ 1155 BSMSysSts 0;
BA_ "GenSigTimeoutTime_ECM" SG_ 1155 BSMSysSts 0;
BA_ "GenSigTimeoutTime_DMSM" SG_ 1155 BSMSysSts 0;
BA_ "GenSigTimeoutTime_BSM" SG_ 1155 BSMSysSts 0;
BA_ "GenSigTimeoutTime_BCM" SG_ 1155 BSMSysSts 0;
BA_ "GenSigTimeoutTime_AGSM" SG_ 1155 BSMSysSts 0;
BA_ "GenSigTimeoutTime_ADCAM" SG_ 1155 BSMSysSts 0;
BA_ "GenSigSendType" SG_ 1155 BSMSysSts 3;
BA_ "GenSigTimeoutTime_RFHM" SG_ 609 TravelDistance 0;
BA_ "GenSigTimeoutTime_MPAD" SG_ 609 TravelDistance 0;
BA_ "GenSigTimeoutTime_GNMM" SG_ 609 TravelDistance 0;
BA_ "GenSigTimeoutTime_ESL" SG_ 609 TravelDistance 0;
BA_ "GenSigTimeoutTime_DTCM" SG_ 609 TravelDistance 0;
BA_ "GenSigTimeoutTime_DMSM" SG_ 609 TravelDistance 0;
BA_ "GenSigTimeoutTime_BSM" SG_ 609 TravelDistance 0;
BA_ "GenSigTimeoutTime_BCM" SG_ 609 TravelDistance 0;
BA_ "GenSigTimeoutTime_AGSM" SG_ 609 TravelDistance 0;
BA_ "GenSigTimeoutTime_ADCAM" SG_ 609 TravelDistance 0;
BA_ "GenSigTimeoutTime_RFHM" SG_ 1155 ABSFailSts 0;
BA_ "GenSigTimeoutTime_GNMM" SG_ 1155 ABSFailSts 0;
BA_ "GenSigTimeoutTime_ESL" SG_ 1155 ABSFailSts 0;
BA_ "GenSigTimeoutTime_ECM" SG_ 1155 ABSFailSts 0;
BA_ "GenSigTimeoutTime_DMSM" SG_ 1155 ABSFailSts 0;
BA_ "GenSigTimeoutTime_BSM" SG_ 1155 ABSFailSts 0;
BA_ "GenSigTimeoutTime_AGSM" SG_ 1155 ABSFailSts 0;
BA_ "GenSigTimeoutTime_ADCAM" SG_ 1155 ABSFailSts 0;
BA_ "GenSigSendType" SG_ 1155 ABSFailSts 3;
BA_ "GenSigTimeoutTime_SGW" SG_ 259 CRC__BRAKE3 0;
BA_ "GenSigTimeoutTime_RFHM" SG_ 259 CRC__BRAKE3 0;
BA_ "GenSigTimeoutTime_IPC" SG_ 259 CRC__BRAKE3 0;
BA_ "GenSigTimeoutTime_ESL" SG_ 259 CRC__BRAKE3 0;
BA_ "GenSigTimeoutTime_ECM" SG_ 259 CRC__BRAKE3 0;
BA_ "GenSigTimeoutTime_DTCM" SG_ 259 CRC__BRAKE3 0;
BA_ "GenSigTimeoutTime_DMSM" SG_ 259 CRC__BRAKE3 0;
BA_ "GenSigTimeoutTime_BSM" SG_ 259 CRC__BRAKE3 0;
BA_ "GenSigTimeoutTime_AGSM" SG_ 259 CRC__BRAKE3 0;
BA_ "GenSigTimeoutTime_ADCAM" SG_ 259 CRC__BRAKE3 0;
BA_ "GenSigTimeoutTime_RFHM" SG_ 259 LHF_Spin 0;
BA_ "GenSigTimeoutTime_IPC" SG_ 259 LHF_Spin 0;
BA_ "GenSigTimeoutTime_GNMM" SG_ 259 LHF_Spin 0;
BA_ "GenSigTimeoutTime_ESL" SG_ 259 LHF_Spin 0;
BA_ "GenSigTimeoutTime_ECM" SG_ 259 LHF_Spin 0;
BA_ "GenSigTimeoutTime_DMSM" SG_ 259 LHF_Spin 0;
BA_ "GenSigTimeoutTime_BSM" SG_ 259 LHF_Spin 0;
BA_ "GenSigTimeoutTime_AGSM" SG_ 259 LHF_Spin 0;
BA_ "GenSigTimeoutTime_ADCAM" SG_ 259 LHF_Spin 0;
BA_ "GenSigTimeoutTime_RFHM" SG_ 259 LHFWheelSpeed 0;
BA_ "GenSigTimeoutTime_IPC" SG_ 259 LHFWheelSpeed 0;
BA_ "GenSigTimeoutTime_ESL" SG_ 259 LHFWheelSpeed 0;
BA_ "GenSigTimeoutTime_DMSM" SG_ 259 LHFWheelSpeed 0;
BA_ "GenSigTimeoutTime_BSM" SG_ 259 LHFWheelSpeed 0;
BA_ "GenSigTimeoutTime_AGSM" SG_ 259 LHFWheelSpeed 0;
BA_ "GenSigTimeoutTime_ADCAM" SG_ 259 LHFWheelSpeed 0;
BA_ "GenSigTimeoutTime_RFHM" SG_ 259 LHRWheelSpeed 0;
BA_ "GenSigTimeoutTime_IPC" SG_ 259 LHRWheelSpeed 0;
BA_ "GenSigTimeoutTime_ESL" SG_ 259 LHRWheelSpeed 0;
BA_ "GenSigTimeoutTime_DMSM" SG_ 259 LHRWheelSpeed 0;
BA_ "GenSigTimeoutTime_BSM" SG_ 259 LHRWheelSpeed 0;
BA_ "GenSigTimeoutTime_AGSM" SG_ 259 LHRWheelSpeed 0;
BA_ "GenSigTimeoutTime_ADCAM" SG_ 259 LHRWheelSpeed 0;
BA_ "GenSigTimeoutTime_SGW" SG_ 259 MessageCounter_BRAKE3 0;
BA_ "GenSigTimeoutTime_RFHM" SG_ 259 MessageCounter_BRAKE3 0;
BA_ "GenSigTimeoutTime_IPC" SG_ 259 MessageCounter_BRAKE3 0;
BA_ "GenSigTimeoutTime_ESL" SG_ 259 MessageCounter_BRAKE3 0;
BA_ "GenSigTimeoutTime_ECM" SG_ 259 MessageCounter_BRAKE3 0;
BA_ "GenSigTimeoutTime_DTCM" SG_ 259 MessageCounter_BRAKE3 0;
BA_ "GenSigTimeoutTime_DMSM" SG_ 259 MessageCounter_BRAKE3 0;
BA_ "GenSigTimeoutTime_BSM" SG_ 259 MessageCounter_BRAKE3 0;
BA_ "GenSigTimeoutTime_AGSM" SG_ 259 MessageCounter_BRAKE3 0;
BA_ "GenSigTimeoutTime_ADCAM" SG_ 259 MessageCounter_BRAKE3 0;
BA_ "GenSigTimeoutTime_RFHM" SG_ 259 RHF_Spin 0;
BA_ "GenSigTimeoutTime_IPC" SG_ 259 RHF_Spin 0;
BA_ "GenSigTimeoutTime_GNMM" SG_ 259 RHF_Spin 0;
BA_ "GenSigTimeoutTime_SGW" SG_ 751 ECM_FOTA_Conflict 0;
BA_ "GenSigTimeoutTime_RFHM" SG_ 751 ECM_FOTA_Conflict 0;
BA_ "GenSigTimeoutTime_MPAD" SG_ 751 ECM_FOTA_Conflict 0;
BA_ "GenSigTimeoutTime_IPC" SG_ 751 ECM_FOTA_Conflict 0;
BA_ "GenSigTimeoutTime_GNMM" SG_ 751 ECM_FOTA_Conflict 0;
BA_ "GenSigTimeoutTime_EVCU2" SG_ 751 ECM_FOTA_Conflict 0;
BA_ "GenSigTimeoutTime_ESL" SG_ 751 ECM_FOTA_Conflict 0;
BA_ "GenSigTimeoutTime_ECM" SG_ 751 ECM_FOTA_Conflict 0;
BA_ "GenSigTimeoutTime_DTCM" SG_ 751 ECM_FOTA_Conflict 0;
BA_ "GenSigTimeoutTime_DMSM" SG_ 751 ECM_FOTA_Conflict 0;
BA_ "GenSigTimeoutTime_BSM" SG_ 751 ECM_FOTA_Conflict 0;
BA_ "GenSigTimeoutTime_BCM" SG_ 751 ECM_FOTA_Conflict 0;
BA_ "GenSigTimeoutTime_AGSM" SG_ 751 ECM_FOTA_Conflict 0;
BA_ "GenSigTimeoutTime_ADCAM" SG_ 751 ECM_FOTA_Conflict 0;
BA_ "GenSigTimeoutTime_SGW" SG_ 1068 RrAxleLockerIndRq 0;
BA_ "GenSigTimeoutTime_RFHM" SG_ 1068 RrAxleLockerIndRq 0;
BA_ "GenSigTimeoutTime_MPAD" SG_ 1068 RrAxleLockerIndRq 0;
BA_ "GenSigTimeoutTime_GNMM" SG_ 1068 RrAxleLockerIndRq 0;
BA_ "GenSigTimeoutTime_EVCU2" SG_ 1068 RrAxleLockerIndRq 0;
BA_ "GenSigTimeoutTime_ESL" SG_ 1068 RrAxleLockerIndRq 0;
BA_ "GenSigTimeoutTime_ECM" SG_ 1068 RrAxleLockerIndRq 0;
BA_ "GenSigTimeoutTime_DTCM" SG_ 1068 RrAxleLockerIndRq 0;
BA_ "GenSigTimeoutTime_DMSM" SG_ 1068 RrAxleLockerIndRq 0;
BA_ "GenSigTimeoutTime_BSM" SG_ 1068 RrAxleLockerIndRq 0;
BA_ "GenSigTimeoutTime_AGSM" SG_ 1068 RrAxleLockerIndRq 0;
BA_ "GenSigTimeoutTime_ADCAM" SG_ 1068 RrAxleLockerIndRq 0;
BA_ "GenSigSendType" SG_ 1068 RrAxleLockerIndRq 3;
BA_ "GenSigTimeoutTime_RFHM" SG_ 1068 TCASERANGESTATUS 0;
BA_ "GenSigTimeoutTime_GNMM" SG_ 1068 TCASERANGESTATUS 0;
BA_ "GenSigTimeoutTime_ESL" SG_ 1068 TCASERANGESTATUS 0;
BA_ "GenSigTimeoutTime_ECM" SG_ 1068 TCASERANGESTATUS 0;
BA_ "GenSigTimeoutTime_DMSM" SG_ 1068 TCASERANGESTATUS 0;
BA_ "GenSigTimeoutTime_AGSM" SG_ 1068 TCASERANGESTATUS 0;
BA_ "GenSigSendType" SG_ 1068 TCASERANGESTATUS 3;
BA_ "GenSigTimeoutTime_MPAD" SG_ 1055 RevOilLifeRst 0;
BA_ "GenSigTimeoutTime_IPC" SG_ 1055 RevOilLifeRst 0;
BA_ "GenSigTimeoutTime_GNMM" SG_ 1055 RevOilLifeRst 0;
BA_ "GenSigTimeoutTime_EVCU2" SG_ 1055 RevOilLifeRst 0;
BA_ "GenSigTimeoutTime_ESL" SG_ 1055 RevOilLifeRst 0;
BA_ "GenSigTimeoutTime_ECM" SG_ 1055 RevOilLifeRst 0;
BA_ "GenSigTimeoutTime_DTCM" SG_ 1055 RevOilLifeRst 0;
BA_ "GenSigTimeoutTime_DMSM" SG_ 1055 RevOilLifeRst 0;
BA_ "GenSigTimeoutTime_BSM" SG_ 1055 RevOilLifeRst 0;
BA_ "GenSigTimeoutTime_AGSM" SG_ 1055 RevOilLifeRst 0;
BA_ "GenSigTimeoutTime_ADCAM" SG_ 1055 RevOilLifeRst 0;
BA_ "GenSigStartValue" SG_ 1055 RevOilLifeRst 65535;
BA_ "GenSigTimeoutTime_SGW" SG_ 1055 RefuelEvent 0;
BA_ "GenSigTimeoutTime_RFHM" SG_ 1055 RefuelEvent 0;
BA_ "GenSigTimeoutTime_MPAD" SG_ 1055 RefuelEvent 0;
BA_ "GenSigTimeoutTime_IPC" SG_ 1055 RefuelEvent 0;
BA_ "GenSigTimeoutTime_GNMM" SG_ 1055 RefuelEvent 0;
BA_ "GenSigTimeoutTime_EVCU2" SG_ 1055 RefuelEvent 0;
BA_ "GenSigTimeoutTime_ESL" SG_ 1055 RefuelEvent 0;
BA_ "GenSigTimeoutTime_ECM" SG_ 1055 RefuelEvent 0;
BA_ "GenSigTimeoutTime_DTCM" SG_ 1055 RefuelEvent 0;
BA_ "GenSigTimeoutTime_DMSM" SG_ 1055 RefuelEvent 0;
BA_ "GenSigTimeoutTime_BSM" SG_ 1055 RefuelEvent 0;
BA_ "GenSigTimeoutTime_AGSM" SG_ 1055 RefuelEvent 0;
BA_ "GenSigTimeoutTime_ADCAM" SG_ 1055 RefuelEvent 0;
BA_ "GenSigTimeoutTime_RFHM" SG_ 1055 OIL_PRESS 0;
BA_ "GenSigTimeoutTime_MPAD" SG_ 1055 OIL_PRESS 0;
BA_ "GenSigTimeoutTime_GNMM" SG_ 1055 OIL_PRESS 0;
BA_ "GenSigTimeoutTime_EVCU2" SG_ 1055 OIL_PRESS 0;
BA_ "GenSigTimeoutTime_ESL" SG_ 1055 OIL_PRESS 0;
BA_ "GenSigTimeoutTime_ECM" SG_ 1055 OIL_PRESS 0;
BA_ "GenSigTimeoutTime_DTCM" SG_ 1055 OIL_PRESS 0;
BA_ "GenSigTimeoutTime_DMSM" SG_ 1055 OIL_PRESS 0;
BA_ "GenSigTimeoutTime_BSM" SG_ 1055 OIL_PRESS 0;
BA_ "GenSigTimeoutTime_BCM" SG_ 1055 OIL_PRESS 0;
BA_ "GenSigTimeoutTime_AGSM" SG_ 1055 OIL_PRESS 0;
BA_ "GenSigTimeoutTime_ADCAM" SG_ 1055 OIL_PRESS 0;
BA_ "GenSigStartValue" SG_ 1055 OIL_PRESS 255;
BA_ "GenSigTimeoutTime_RFHM" SG_ 1055 MAP_4_BAR 0;
BA_ "GenSigTimeoutTime_MPAD" SG_ 1055 MAP_4_BAR 0;
BA_ "GenSigTimeoutTime_IPC" SG_ 1055 MAP_4_BAR 0;
BA_ "GenSigTimeoutTime_GNMM" SG_ 1055 MAP_4_BAR 0;
BA_ "GenSigTimeoutTime_EVCU2" SG_ 1055 MAP_4_BAR 0;
BA_ "GenSigTimeoutTime_ESL" SG_ 1055 MAP_4_BAR 0;
BA_ "GenSigTimeoutTime_ECM" SG_ 1055 MAP_4_BAR 0;
BA_ "GenSigTimeoutTime_DTCM" SG_ 1055 MAP_4_BAR 0;
BA_ "GenSigTimeoutTime_DMSM" SG_ 1055 MAP_4_BAR 0;
BA_ "GenSigTimeoutTime_BSM" SG_ 1055 MAP_4_BAR 0;
BA_ "GenSigTimeoutTime_AGSM" SG_ 1055 MAP_4_BAR 0;
BA_ "GenSigTimeoutTime_ADCAM" SG_ 1055 MAP_4_BAR 0;
BA_ "GenSigStartValue" SG_ 1055 MAP_4_BAR 511;
BA_ "GenSigTimeoutTime_SGW" SG_ 1055 AM_ECM_Prsnt 0;
BA_ "GenSigTimeoutTime_RFHM" SG_ 1055 AM_ECM_Prsnt 0;
BA_ "GenSigTimeoutTime_MPAD" SG_ 1055 AM_ECM_Prsnt 0;
BA_ "GenSigTimeoutTime_IPC" SG_ 1055 AM_ECM_Prsnt 0;
BA_ "GenSigTimeoutTime_GNMM" SG_ 1055 AM_ECM_Prsnt 0;
BA_ "GenSigTimeoutTime_EVCU2" SG_ 1055 AM_ECM_Prsnt 0;
BA_ "GenSigTimeoutTime_ESL" SG_ 1055 AM_ECM_Prsnt 0;
BA_ "GenSigTimeoutTime_ECM" SG_ 1055 AM_ECM_Prsnt 0;
BA_ "GenSigTimeoutTime_DTCM" SG_ 1055 AM_ECM_Prsnt 0;
BA_ "GenSigTimeoutTime_DMSM" SG_ 1055 AM_ECM_Prsnt 0;
BA_ "GenSigTimeoutTime_BSM" SG_ 1055 AM_ECM_Prsnt 0;
BA_ "GenSigTimeoutTime_AGSM" SG_ 1055 AM_ECM_Prsnt 0;
BA_ "GenSigTimeoutTime_ADCAM" SG_ 1055 AM_ECM_Prsnt 0;
BA_ "GenSigTimeoutTime_SGW" SG_ 1448 HoursOilLifeRst 0;
BA_ "GenSigTimeoutTime_RFHM" SG_ 1448 HoursOilLifeRst 0;
BA_ "GenSigTimeoutTime_MPAD" SG_ 1448 HoursOilLifeRst 0;
BA_ "GenSigTimeoutTime_IPC" SG_ 1448 HoursOilLifeRst 0;
BA_ "GenSigTimeoutTime_GNMM" SG_ 1448 HoursOilLifeRst 0;
BA_ "GenSigTimeoutTime_EVCU2" SG_ 1448 HoursOilLifeRst 0;
BA_ "GenSigTimeoutTime_ESL" SG_ 1448 HoursOilLifeRst 0;
BA_ "GenSigTimeoutTime_ECM" SG_ 1448 HoursOilLifeRst 0;
BA_ "GenSigTimeoutTime_DTCM" SG_ 1448 HoursOilLifeRst 0;
BA_ "GenSigTimeoutTime_DMSM" SG_ 1448 HoursOilLifeRst 0;
BA_ "GenSigTimeoutTime_BSM" SG_ 1448 HoursOilLifeRst 0;
BA_ "GenSigTimeoutTime_AGSM" SG_ 1448 HoursOilLifeRst 0;
BA_ "GenSigTimeoutTime_ADCAM" SG_ 1448 HoursOilLifeRst 0;
BA_ "GenSigStartValue" SG_ 1448 HoursOilLifeRst 4095;
BA_ "GenSigTimeoutTime_SGW" SG_ 264 CRC_EPS1 0;
BA_ "GenSigTimeoutTime_RFHM" SG_ 264 CRC_EPS1 0;
BA_ "GenSigTimeoutTime_IPC" SG_ 264 CRC_EPS1 0;
BA_ "GenSigTimeoutTime_GNMM" SG_ 264 CRC_EPS1 0;
BA_ "GenSigTimeoutTime_ESL" SG_ 264 CRC_EPS1 0;
BA_ "GenSigTimeoutTime_ECM" SG_ 264 CRC_EPS1 0;
BA_ "GenSigTimeoutTime_DTCM" SG_ 264 CRC_EPS1 0;
BA_ "GenSigTimeoutTime_DMSM" SG_ 264 CRC_EPS1 0;
BA_ "GenSigTimeoutTime_BCM" SG_ 264 CRC_EPS1 0;
BA_ "GenSigTimeoutTime_AGSM" SG_ 264 CRC_EPS1 0;
BA_ "GenSigTimeoutTime_ADCAM" SG_ 264 CRC_EPS1 0;
BA_ "GenSigTimeoutTime_RFHM" SG_ 1448 OilPressureSts 0;
BA_ "GenSigTimeoutTime_MPAD" SG_ 1448 OilPressureSts 0;
BA_ "GenSigTimeoutTime_RFHM" SG_ 1054 ThermalManagementActive_W 0;
BA_ "GenSigTimeoutTime_MPAD" SG_ 1054 ThermalManagementActive_W 0;
BA_ "GenSigTimeoutTime_IPC" SG_ 1054 ThermalManagementActive_W 0;
BA_ "GenSigTimeoutTime_GNMM" SG_ 1054 ThermalManagementActive_W 0;
BA_ "GenSigTimeoutTime_ESL" SG_ 1054 ThermalManagementActive_W 0;
BA_ "GenSigTimeoutTime_ECM" SG_ 1054 ThermalManagementActive_W 0;
BA_ "GenSigTimeoutTime_DTCM" SG_ 1054 ThermalManagementActive_W 0;
BA_ "GenSigTimeoutTime_DMSM" SG_ 1054 ThermalManagementActive_W 0;
BA_ "GenSigTimeoutTime_BSM" SG_ 1054 ThermalManagementActive_W 0;
BA_ "GenSigTimeoutTime_BCM" SG_ 1054 ThermalManagementActive_W 0;
BA_ "GenSigTimeoutTime_AGSM" SG_ 1054 ThermalManagementActive_W 0;
BA_ "GenSigTimeoutTime_ADCAM" SG_ 1054 ThermalManagementActive_W 0;
BA_ "GenSigTimeoutTime_SGW" SG_ 1054 ThermalManagementActive_W 0;
BA_ "GenSigTimeoutTime_RFHM" SG_ 1054 RawTPS2 0;
BA_ "GenSigTimeoutTime_MPAD" SG_ 1054 RawTPS2 0;
BA_ "GenSigTimeoutTime_IPC" SG_ 1054 RawTPS2 0;
BA_ "GenSigTimeoutTime_GNMM" SG_ 1054 RawTPS2 0;
BA_ "GenSigTimeoutTime_EVCU2" SG_ 1054 RawTPS2 0;
BA_ "GenSigTimeoutTime_ESL" SG_ 1054 RawTPS2 0;
BA_ "GenSigTimeoutTime_ECM" SG_ 1054 RawTPS2 0;
BA_ "GenSigTimeoutTime_DTCM" SG_ 1054 RawTPS2 0;
BA_ "GenSigTimeoutTime_DMSM" SG_ 1054 RawTPS2 0;
BA_ "GenSigTimeoutTime_BSM" SG_ 1054 RawTPS2 0;
BA_ "GenSigTimeoutTime_BCM" SG_ 1054 RawTPS2 0;
BA_ "GenSigTimeoutTime_AGSM" SG_ 1054 RawTPS2 0;
BA_ "GenSigTimeoutTime_ADCAM" SG_ 1054 RawTPS2 0;
BA_ "GenSigStartValue" SG_ 1054 RawTPS2 255;
BA_ "GenSigTimeoutTime_RFHM" SG_ 1054 RawTPS1 0;
BA_ "GenSigTimeoutTime_MPAD" SG_ 1054 RawTPS1 0;
BA_ "GenSigTimeoutTime_IPC" SG_ 1054 RawTPS1 0;
BA_ "GenSigTimeoutTime_GNMM" SG_ 1054 RawTPS1 0;
BA_ "GenSigTimeoutTime_EVCU2" SG_ 1054 RawTPS1 0;
BA_ "GenSigTimeoutTime_ESL" SG_ 1054 RawTPS1 0;
BA_ "GenSigTimeoutTime_ECM" SG_ 1054 RawTPS1 0;
BA_ "GenSigTimeoutTime_DTCM" SG_ 1054 RawTPS1 0;
BA_ "GenSigTimeoutTime_DMSM" SG_ 1054 RawTPS1 0;
BA_ "GenSigTimeoutTime_SGW" SG_ 2564428018 N_PDU 0;
BA_ "GenSigTimeoutTime_RFHM" SG_ 2564428018 N_PDU 0;
BA_ "GenSigTimeoutTime_MPAD" SG_ 2564428018 N_PDU 0;
BA_ "GenSigTimeoutTime_IPC" SG_ 2564428018 N_PDU 0;
BA_ "GenSigTimeoutTime_GNMM" SG_ 2564428018 N_PDU 0;
BA_ "GenSigTimeoutTime_EVCU2" SG_ 2564428018 N_PDU 0;
BA_ "GenSigTimeoutTime_ESL" SG_ 2564428018 N_PDU 0;
BA_ "GenSigTimeoutTime_ECM" SG_ 2564428018 N_PDU 0;
BA_ "GenSigTimeoutTime_DTCM" SG_ 2564428018 N_PDU 0;
BA_ "GenSigTimeoutTime_DMSM" SG_ 2564428018 N_PDU 0;
BA_ "GenSigTimeoutTime_BSM" SG_ 2564428018 N_PDU 0;
BA_ "GenSigTimeoutTime_BCM" SG_ 2564428018 N_PDU 0;
BA_ "GenSigTimeoutTime_AGSM" SG_ 2564428018 N_PDU 0;
BA_ "GenSigTimeoutTime_ADCAM" SG_ 2564428018 N_PDU 0;
BA_ "GenSigTimeoutTime_SGW" SG_ 2564430578 N_PDU 0;
BA_ "GenSigTimeoutTime_RFHM" SG_ 2564430578 N_PDU 0;
BA_ "GenSigTimeoutTime_MPAD" SG_ 2564430578 N_PDU 0;
BA_ "GenSigTimeoutTime_IPC" SG_ 2564430578 N_PDU 0;
BA_ "GenSigTimeoutTime_GNMM" SG_ 2564430578 N_PDU 0;
BA_ "GenSigTimeoutTime_EVCU2" SG_ 2564430578 N_PDU 0;
BA_ "GenSigTimeoutTime_ESL" SG_ 2564430578 N_PDU 0;
BA_ "GenSigTimeoutTime_ECM" SG_ 2564430578 N_PDU 0;
BA_ "GenSigTimeoutTime_DTCM" SG_ 2564430578 N_PDU 0;
BA_ "GenSigTimeoutTime_DMSM" SG_ 2564430578 N_PDU 0;
BA_ "GenSigTimeoutTime_BSM" SG_ 2564430578 N_PDU 0;
BA_ "GenSigTimeoutTime_BCM" SG_ 2564430578 N_PDU 0;
BA_ "GenSigTimeoutTime_AGSM" SG_ 2564430578 N_PDU 0;
BA_ "GenSigTimeoutTime_ADCAM" SG_ 2564430578 N_PDU 0;
BA_ "GenSigTimeoutTime_SGW" SG_ 2564434162 N_PDU 0;
BA_ "GenSigTimeoutTime_RFHM" SG_ 2564434162 N_PDU 0;
BA_ "GenSigTimeoutTime_MPAD" SG_ 2564434162 N_PDU 0;
BA_ "GenSigTimeoutTime_IPC" SG_ 2564434162 N_PDU 0;
BA_ "GenSigTimeoutTime_GNMM" SG_ 2564434162 N_PDU 0;
BA_ "GenSigTimeoutTime_EVCU2" SG_ 2564434162 N_PDU 0;
BA_ "GenSigTimeoutTime_ESL" SG_ 2564434162 N_PDU 0;
BA_ "GenSigTimeoutTime_ECM" SG_ 2564434162 N_PDU 0;
BA_ "GenSigTimeoutTime_DTCM" SG_ 2564434162 N_PDU 0;
BA_ "GenSigTimeoutTime_DMSM" SG_ 2564434162 N_PDU 0;
BA_ "GenSigTimeoutTime_BSM" SG_ 2564434162 N_PDU 0;
BA_ "GenSigTimeoutTime_BCM" SG_ 2564434162 N_PDU 0;
BA_ "GenSigTimeoutTime_AGSM" SG_ 2564434162 N_PDU 0;
BA_ "GenSigTimeoutTime_ADCAM" SG_ 2564434162 N_PDU 0;
BA_ "GenSigTimeoutTime_DTCM" SG_ 2564474098 N_PDU 0;
BA_ "GenSigTimeoutTime_DMSM" SG_ 2564474098 N_PDU 0;
BA_ "GenSigTimeoutTime_BSM" SG_ 2564474098 N_PDU 0;
BA_ "GenSigTimeoutTime_BCM" SG_ 2564474098 N_PDU 0;
BA_ "GenSigTimeoutTime_AGSM" SG_ 2564474098 N_PDU 0;
BA_ "GenSigTimeoutTime_ADCAM" SG_ 2564474098 N_PDU 0;
BA_ "GenSigTimeoutTime_RFHM" SG_ 609 ESC_OFF_Hrd_Sft_Button_sts 0;
BA_ "GenSigTimeoutTime_MPAD" SG_ 609 ESC_OFF_Hrd_Sft_Button_sts 0;
BA_ "GenSigTimeoutTime_IPC" SG_ 609 ESC_OFF_Hrd_Sft_Button_sts 0;
BA_ "GenSigTimeoutTime_GNMM" SG_ 609 ESC_OFF_Hrd_Sft_Button_sts 0;
BA_ "GenSigTimeoutTime_EVCU2" SG_ 609 ESC_OFF_Hrd_Sft_Button_sts 0;
BA_ "GenSigTimeoutTime_ESL" SG_ 609 ESC_OFF_Hrd_Sft_Button_sts 0;
BA_ "GenSigTimeoutTime_ECM" SG_ 609 ESC_OFF_Hrd_Sft_Button_sts 0;
BA_ "GenSigTimeoutTime_DTCM" SG_ 609 ESC_OFF_Hrd_Sft_Button_sts 0;
BA_ "GenSigTimeoutTime_DMSM" SG_ 609 ESC_OFF_Hrd_Sft_Button_sts 0;
BA_ "GenSigTimeoutTime_BSM" SG_ 609 ESC_OFF_Hrd_Sft_Button_sts 0;
BA_ "GenSigTimeoutTime_AGSM" SG_ 609 ESC_OFF_Hrd_Sft_Button_sts 0;
BA_ "GenSigTimeoutTime_ADCAM" SG_ 609 ESC_OFF_Hrd_Sft_Button_sts 0;
BA_ "GenSigTimeoutTime_SGW" SG_ 264 LwsSpeed 0;
BA_ "GenSigTimeoutTime_RFHM" SG_ 264 LwsSpeed 0;
BA_ "GenSigTimeoutTime_IPC" SG_ 264 LwsSpeed 0;
BA_ "GenSigTimeoutTime_GNMM" SG_ 264 LwsSpeed 0;
BA_ "GenSigTimeoutTime_ESL" SG_ 264 LwsSpeed 0;
BA_ "GenSigTimeoutTime_ECM" SG_ 264 LwsSpeed 0;
BA_ "GenSigTimeoutTime_DMSM" SG_ 264 LwsSpeed 0;
BA_ "GenSigTimeoutTime_BCM" SG_ 264 LwsSpeed 0;
BA_ "GenSigTimeoutTime_AGSM" SG_ 264 LwsSpeed 0;
BA_ "GenSigTimeoutTime_ADCAM" SG_ 264 LwsSpeed 0;
BA_ "GenSigTimeoutTime_SGW" SG_ 2564485658 N_PDU 0;
BA_ "GenSigTimeoutTime_RFHM" SG_ 2564485658 N_PDU 0;
BA_ "GenSigTimeoutTime_MPAD" SG_ 2564485658 N_PDU 0;
BA_ "GenSigTimeoutTime_IPC" SG_ 2564485658 N_PDU 0;
BA_ "GenSigTimeoutTime_GNMM" SG_ 2564485658 N_PDU 0;
BA_ "GenSigTimeoutTime_EVCU2" SG_ 2564485658 N_PDU 0;
BA_ "GenSigTimeoutTime_ESL" SG_ 2564485658 N_PDU 0;
BA_ "GenSigTimeoutTime_ECM" SG_ 2564485658 N_PDU 0;
BA_ "GenSigTimeoutTime_DTCM" SG_ 2564485658 N_PDU 0;
BA_ "GenSigTimeoutTime_DMSM" SG_ 2564485658 N_PDU 0;
BA_ "GenSigTimeoutTime_BSM" SG_ 2564485658 N_PDU 0;
BA_ "GenSigTimeoutTime_BCM" SG_ 2564485658 N_PDU 0;
BA_ "GenSigTimeoutTime_AGSM" SG_ 2564485658 N_PDU 0;
BA_ "GenSigTimeoutTime_ADCAM" SG_ 2564485658 N_PDU 0;
BA_ "GenSigTimeoutTime_SGW" SG_ 2564485648 N_PDU 0;
BA_ "GenSigTimeoutTime_RFHM" SG_ 2564485648 N_PDU 0;
BA_ "GenSigTimeoutTime_MPAD" SG_ 2564485648 N_PDU 0;
BA_ "GenSigTimeoutTime_IPC" SG_ 2564485648 N_PDU 0;
BA_ "GenSigTimeoutTime_GNMM" SG_ 2564485648 N_PDU 0;
BA_ "GenSigTimeoutTime_EVCU2" SG_ 2564485648 N_PDU 0;
BA_ "GenSigTimeoutTime_ESL" SG_ 2564485648 N_PDU 0;
BA_ "GenSigTimeoutTime_ECM" SG_ 2564485648 N_PDU 0;
BA_ "GenSigTimeoutTime_DTCM" SG_ 2564485648 N_PDU 0;
BA_ "GenSigTimeoutTime_DMSM" SG_ 2564485648 N_PDU 0;
BA_ "GenSigTimeoutTime_BSM" SG_ 2564485648 N_PDU 0;
BA_ "GenSigTimeoutTime_BCM" SG_ 2564485648 N_PDU 0;
BA_ "GenSigTimeoutTime_AGSM" SG_ 2564485648 N_PDU 0;
BA_ "GenSigTimeoutTime_ADCAM" SG_ 2564485648 N_PDU 0;
BA_ "GenSigTimeoutTime_SGW" SG_ 2564485828 N_PDU 0;
BA_ "GenSigTimeoutTime_RFHM" SG_ 2564485828 N_PDU 0;
BA_ "GenSigTimeoutTime_MPAD" SG_ 2564485828 N_PDU 0;
BA_ "GenSigTimeoutTime_IPC" SG_ 2564485828 N_PDU 0;
BA_ "GenSigTimeoutTime_GNMM" SG_ 2564485828 N_PDU 0;
BA_ "GenSigTimeoutTime_EVCU2" SG_ 2564485828 N_PDU 0;
BA_ "GenSigTimeoutTime_ESL" SG_ 2564485828 N_PDU 0;
BA_ "GenSigTimeoutTime_ECM" SG_ 2564485828 N_PDU 0;
BA_ "GenSigTimeoutTime_DTCM" SG_ 2564485828 N_PDU 0;
BA_ "GenSigTimeoutTime_DMSM" SG_ 2564485828 N_PDU 0;
BA_ "GenSigTimeoutTime_BSM" SG_ 2564485828 N_PDU 0;
BA_ "GenSigTimeoutTime_BCM" SG_ 2564485828 N_PDU 0;
BA_ "GenSigTimeoutTime_AGSM" SG_ 2564485828 N_PDU 0;
BA_ "GenSigTimeoutTime_ADCAM" SG_ 2564485828 N_PDU 0;
BA_ "GenSigTimeoutTime_SGW" SG_ 2564485672 N_PDU 0;
BA_ "GenSigTimeoutTime_RFHM" SG_ 2564485672 N_PDU 0;
BA_ "GenSigTimeoutTime_MPAD" SG_ 2564485672 N_PDU 0;
BA_ "GenSigTimeoutTime_IPC" SG_ 2564485672 N_PDU 0;
BA_ "GenSigTimeoutTime_GNMM" SG_ 2564485672 N_PDU 0;
BA_ "GenSigTimeoutTime_EVCU2" SG_ 2564485672 N_PDU 0;
BA_ "GenSigTimeoutTime_ESL" SG_ 2564485672 N_PDU 0;
BA_ "GenSigTimeoutTime_ECM" SG_ 2564485672 N_PDU 0;
BA_ "GenSigTimeoutTime_DTCM" SG_ 2564485672 N_PDU 0;
BA_ "GenSigTimeoutTime_DMSM" SG_ 2564485672 N_PDU 0;
BA_ "GenSigTimeoutTime_BSM" SG_ 2564485672 N_PDU 0;
BA_ "GenSigTimeoutTime_BCM" SG_ 2564485672 N_PDU 0;
BA_ "GenSigTimeoutTime_AGSM" SG_ 2564485672 N_PDU 0;
BA_ "GenSigTimeoutTime_ADCAM" SG_ 2564485672 N_PDU 0;
BA_ "GenSigTimeoutTime_SGW" SG_ 2564485728 N_PDU 0;
BA_ "GenSigTimeoutTime_RFHM" SG_ 2564485728 N_PDU 0;
BA_ "GenSigTimeoutTime_MPAD" SG_ 2564485728 N_PDU 0;
BA_ "GenSigTimeoutTime_IPC" SG_ 2564485728 N_PDU 0;
BA_ "GenSigTimeoutTime_GNMM" SG_ 2564485728 N_PDU 0;
BA_ "GenSigTimeoutTime_EVCU2" SG_ 2564485728 N_PDU 0;
BA_ "GenSigTimeoutTime_ESL" SG_ 2564485728 N_PDU 0;
BA_ "GenSigTimeoutTime_ECM" SG_ 2564485728 N_PDU 0;
BA_ "GenSigTimeoutTime_DTCM" SG_ 2564485728 N_PDU 0;
BA_ "GenSigTimeoutTime_DMSM" SG_ 2564485728 N_PDU 0;
BA_ "GenSigTimeoutTime_BSM" SG_ 2564485728 N_PDU 0;
BA_ "GenSigTimeoutTime_BCM" SG_ 2564485728 N_PDU 0;
BA_ "GenSigTimeoutTime_AGSM" SG_ 2564485728 N_PDU 0;
BA_ "GenSigTimeoutTime_ADCAM" SG_ 2564485728 N_PDU 0;
BA_ "GenSigTimeoutTime_GNMM" SG_ 2651930646 Digit_09_AGSM 0;
BA_ "GenSigTimeoutTime_EVCU2" SG_ 2651930646 Digit_09_AGSM 0;
BA_ "GenSigTimeoutTime_ESL" SG_ 2651930646 Digit_09_AGSM 0;
BA_ "GenSigTimeoutTime_ECM" SG_ 2651930646 Digit_09_AGSM 0;
BA_ "GenSigTimeoutTime_DTCM" SG_ 2651930646 Digit_09_AGSM 0;
BA_ "GenSigTimeoutTime_DMSM" SG_ 2651930646 Digit_09_AGSM 0;
BA_ "GenSigTimeoutTime_BSM" SG_ 2651930646 Digit_09_AGSM 0;
BA_ "GenSigTimeoutTime_AGSM" SG_ 2651930646 Digit_09_AGSM 0;
BA_ "GenSigTimeoutTime_ADCAM" SG_ 2651930646 Digit_09_AGSM 0;
BA_ "GenSigTimeoutTime_SGW" SG_ 2651930646 Digit_09_AGSM 0;
BA_ "GenSigTimeoutTime_RFHM" SG_ 2651930646 Digit_09_AGSM 0;
BA_ "GenSigTimeoutTime_MPAD" SG_ 2651930646 Digit_09_AGSM 0;
BA_ "GenSigTimeoutTime_IPC" SG_ 2651930646 Digit_09_AGSM 0;
BA_ "GenSigTimeoutTime_SGW" SG_ 2651930646 Digit_10_AGSM 0;
BA_ "GenSigTimeoutTime_RFHM" SG_ 2651930646 Digit_10_AGSM 0;
BA_ "GenSigTimeoutTime_MPAD" SG_ 2651930646 Digit_10_AGSM 0;
BA_ "GenSigTimeoutTime_IPC" SG_ 2651930646 Digit_10_AGSM 0;
BA_ "GenSigTimeoutTime_GNMM" SG_ 2651930646 Digit_10_AGSM 0;
BA_ "GenSigTimeoutTime_EVCU2" SG_ 2651930646 Digit_10_AGSM 0;
BA_ "GenSigTimeoutTime_ESL" SG_ 2651930646 Digit_10_AGSM 0;
BA_ "GenSigTimeoutTime_ECM" SG_ 2651930646 Digit_10_AGSM 0;
BA_ "GenSigTimeoutTime_DTCM" SG_ 2651930646 Digit_10_AGSM 0;
BA_ "GenSigTimeoutTime_DMSM" SG_ 2651930646 Digit_10_AGSM 0;
BA_ "GenSigTimeoutTime_BSM" SG_ 2651930646 Digit_10_AGSM 0;
BA_ "GenSigTimeoutTime_AGSM" SG_ 2651930646 Digit_10_AGSM 0;
BA_ "GenSigTimeoutTime_ADCAM" SG_ 2651930646 Digit_10_AGSM 0;
BA_ "GenSigTimeoutTime_SGW" SG_ 2651930646 Digit_11_AGSM 0;
BA_ "GenSigTimeoutTime_RFHM" SG_ 2651930646 Digit_11_AGSM 0;
BA_ "GenSigTimeoutTime_MPAD" SG_ 2651930646 Digit_11_AGSM 0;
BA_ "GenSigTimeoutTime_IPC" SG_ 2651930646 Digit_11_AGSM 0;
BA_ "GenSigTimeoutTime_GNMM" SG_ 2651930646 Digit_11_AGSM 0;
BA_ "GenSigTimeoutTime_EVCU2" SG_ 2651930646 Digit_11_AGSM 0;
BA_ "GenSigTimeoutTime_ESL" SG_ 2651930646 Digit_11_AGSM 0;
BA_ "GenSigTimeoutTime_ECM" SG_ 2651930646 Digit_11_AGSM 0;
BA_ "GenSigTimeoutTime_DTCM" SG_ 2651930646 Digit_11_AGSM 0;
BA_ "GenSigTimeoutTime_DMSM" SG_ 2651930646 Digit_11_AGSM 0;
BA_ "GenSigTimeoutTime_BSM" SG_ 2651930646 Digit_11_AGSM 0;
BA_ "GenSigTimeoutTime_AGSM" SG_ 2651930646 Digit_11_AGSM 0;
BA_ "GenSigTimeoutTime_ADCAM" SG_ 2651930646 Digit_11_AGSM 0;
BA_ "GenSigTimeoutTime_SGW" SG_ 2651930646 Digit_07_AGSM 0;
BA_ "GenSigTimeoutTime_RFHM" SG_ 2651930646 Digit_07_AGSM 0;
BA_ "GenSigTimeoutTime_MPAD" SG_ 2651930646 Digit_07_AGSM 0;
BA_ "GenSigTimeoutTime_IPC" SG_ 2651930646 Digit_07_AGSM 0;
BA_ "GenSigTimeoutTime_GNMM" SG_ 2651930646 Digit_07_AGSM 0;
BA_ "GenSigTimeoutTime_EVCU2" SG_ 2651930646 Digit_07_AGSM 0;
BA_ "GenSigTimeoutTime_ESL" SG_ 2651930646 Digit_07_AGSM 0;
BA_ "GenSigTimeoutTime_ECM" SG_ 2651930646 Digit_07_AGSM 0;
BA_ "GenSigTimeoutTime_DTCM" SG_ 2651930646 Digit_07_AGSM 0;
BA_ "GenSigTimeoutTime_DMSM" SG_ 2651930646 Digit_07_AGSM 0;
BA_ "GenSigTimeoutTime_BSM" SG_ 2651930646 Digit_07_AGSM 0;
BA_ "GenSigTimeoutTime_AGSM" SG_ 2651930646 Digit_07_AGSM 0;
BA_ "GenSigTimeoutTime_SGW" SG_ 2651930646 Digit_08_AGSM 0;
BA_ "GenSigTimeoutTime_RFHM" SG_ 2651930646 Digit_08_AGSM 0;
BA_ "GenSigTimeoutTime_MPAD" SG_ 2651930646 Digit_08_AGSM 0;
BA_ "GenSigTimeoutTime_IPC" SG_ 2651930646 Digit_08_AGSM 0;
BA_ "GenSigTimeoutTime_GNMM" SG_ 2651930646 Digit_08_AGSM 0;
BA_ "GenSigTimeoutTime_EVCU2" SG_ 2651930646 Digit_08_AGSM 0;
BA_ "GenSigTimeoutTime_ESL" SG_ 2651930646 Digit_08_AGSM 0;
BA_ "GenSigTimeoutTime_ECM" SG_ 2651930646 Digit_08_AGSM 0;
BA_ "GenSigTimeoutTime_DTCM" SG_ 2651930646 Digit_08_AGSM 0;
BA_ "GenSigTimeoutTime_DMSM" SG_ 2651930646 Digit_08_AGSM 0;
BA_ "GenSigTimeoutTime_BSM" SG_ 2651930646 Digit_08_AGSM 0;
BA_ "GenSigTimeoutTime_AGSM" SG_ 2651930646 Digit_08_AGSM 0;
BA_ "GenSigTimeoutTime_ADCAM" SG_ 2651930646 Digit_08_AGSM 0;
BA_ "GenSigTimeoutTime_SGW" SG_ 609 RedLampReq 0;
BA_ "GenSigTimeoutTime_RFHM" SG_ 609 RedLampReq 0;
BA_ "GenSigTimeoutTime_MPAD" SG_ 609 RedLampReq 0;
BA_ "GenSigTimeoutTime_GNMM" SG_ 609 RedLampReq 0;
BA_ "GenSigTimeoutTime_EVCU2" SG_ 609 RedLampReq 0;
BA_ "GenSigTimeoutTime_ESL" SG_ 609 RedLampReq 0;
BA_ "GenSigTimeoutTime_ECM" SG_ 609 RedLampReq 0;
BA_ "GenSigTimeoutTime_DTCM" SG_ 609 RedLampReq 0;
BA_ "GenSigTimeoutTime_DMSM" SG_ 609 RedLampReq 0;
BA_ "GenSigTimeoutTime_BSM" SG_ 609 RedLampReq 0;
BA_ "GenSigTimeoutTime_BCM" SG_ 609 RedLampReq 0;
BA_ "GenSigTimeoutTime_AGSM" SG_ 609 RedLampReq 0;
BA_ "GenSigTimeoutTime_ADCAM" SG_ 609 RedLampReq 0;
BA_ "GenSigTimeoutTime_SGW" SG_ 609 MSRActive 0;
BA_ "GenSigTimeoutTime_RFHM" SG_ 609 MSRActive 0;
BA_ "GenSigTimeoutTime_MPAD" SG_ 609 MSRActive 0;
BA_ "GenSigTimeoutTime_IPC" SG_ 609 MSRActive 0;
BA_ "GenSigTimeoutTime_GNMM" SG_ 609 MSRActive 0;
BA_ "GenSigTimeoutTime_ESL" SG_ 609 MSRActive 0;
BA_ "GenSigTimeoutTime_ECM" SG_ 609 MSRActive 0;
BA_ "GenSigTimeoutTime_DTCM" SG_ 609 MSRActive 0;
BA_ "GenSigTimeoutTime_DMSM" SG_ 609 MSRActive 0;
BA_ "GenSigTimeoutTime_BSM" SG_ 609 MSRActive 0;
BA_ "GenSigTimeoutTime_AGSM" SG_ 609 MSRActive 0;
BA_ "GenSigTimeoutTime_ADCAM" SG_ 609 MSRActive 0;
BA_ "GenSigSendType" SG_ 609 MSRActive 3;
BA_ "GenSigTimeoutTime_SGW" SG_ 609 EPBSwitchPosition 0;
BA_ "GenSigTimeoutTime_RFHM" SG_ 609 EPBSwitchPosition 0;
BA_ "GenSigTimeoutTime_MPAD" SG_ 609 EPBSwitchPosition 0;
BA_ "GenSigTimeoutTime_IPC" SG_ 609 EPBSwitchPosition 0;
BA_ "GenSigTimeoutTime_GNMM" SG_ 609 EPBSwitchPosition 0;
BA_ "GenSigTimeoutTime_EVCU2" SG_ 609 EPBSwitchPosition 0;
BA_ "GenSigTimeoutTime_ESL" SG_ 609 EPBSwitchPosition 0;
BA_ "GenSigTimeoutTime_ECM" SG_ 609 EPBSwitchPosition 0;
BA_ "GenSigTimeoutTime_DTCM" SG_ 609 EPBSwitchPosition 0;
BA_ "GenSigTimeoutTime_DMSM" SG_ 609 EPBSwitchPosition 0;
BA_ "GenSigTimeoutTime_BSM" SG_ 609 EPBSwitchPosition 0;
BA_ "GenSigTimeoutTime_AGSM" SG_ 609 EPBSwitchPosition 0;
BA_ "GenSigTimeoutTime_ADCAM" SG_ 609 EPBSwitchPosition 0;
BA_ "GenSigTimeoutTime_RFHM" SG_ 609 EPBMaintenanceSts 0;
BA_ "GenSigTimeoutTime_MPAD" SG_ 609 EPBMaintenanceSts 0;
BA_ "GenSigTimeoutTime_IPC" SG_ 609 EPBMaintenanceSts 0;
BA_ "GenSigTimeoutTime_GNMM" SG_ 609 EPBMaintenanceSts 0;
BA_ "GenSigTimeoutTime_EVCU2" SG_ 609 EPBMaintenanceSts 0;
BA_ "GenSigTimeoutTime_ESL" SG_ 609 EPBMaintenanceSts 0;
BA_ "GenSigTimeoutTime_ECM" SG_ 609 EPBMaintenanceSts 0;
BA_ "GenSigTimeoutTime_DTCM" SG_ 609 EPBMaintenanceSts 0;
BA_ "GenSigTimeoutTime_DMSM" SG_ 609 EPBMaintenanceSts 0;
BA_ "GenSigTimeoutTime_BSM" SG_ 609 EPBMaintenanceSts 0;
BA_ "GenSigTimeoutTime_BCM" SG_ 609 EPBMaintenanceSts 0;
BA_ "GenSigTimeoutTime_AGSM" SG_ 609 EPBMaintenanceSts 0;
BA_ "GenSigTimeoutTime_ADCAM" SG_ 609 EPBMaintenanceSts 0;
BA_ "GenSigTimeoutTime_SGW" SG_ 609 EPBAutoAppSts 0;
BA_ "GenSigTimeoutTime_RFHM" SG_ 609 EPBAutoAppSts 0;
BA_ "GenSigTimeoutTime_MPAD" SG_ 609 EPBAutoAppSts 0;
BA_ "GenSigTimeoutTime_IPC" SG_ 609 EPBAutoAppSts 0;
BA_ "GenSigTimeoutTime_GNMM" SG_ 609 EPBAutoAppSts 0;
BA_ "GenSigTimeoutTime_EVCU2" SG_ 609 EPBAutoAppSts 0;
BA_ "GenSigTimeoutTime_ESL" SG_ 609 EPBAutoAppSts 0;
BA_ "GenSigTimeoutTime_ECM" SG_ 609 EPBAutoAppSts 0;
BA_ "GenSigTimeoutTime_DTCM" SG_ 609 EPBAutoAppSts 0;
BA_ "GenSigTimeoutTime_DMSM" SG_ 609 EPBAutoAppSts 0;
BA_ "GenSigTimeoutTime_BSM" SG_ 609 EPBAutoAppSts 0;
BA_ "GenSigTimeoutTime_BCM" SG_ 609 EPBAutoAppSts 0;
BA_ "GenSigTimeoutTime_AGSM" SG_ 609 EPBAutoAppSts 0;
BA_ "GenSigTimeoutTime_ADCAM" SG_ 609 EPBAutoAppSts 0;
BA_ "GenSigStartValue" SG_ 609 EPBAutoAppSts 1;
BA_ "GenSigTimeoutTime_RFHM" SG_ 609 EPB_HMI_Management 0;
BA_ "GenSigTimeoutTime_MPAD" SG_ 609 EPB_HMI_Management 0;
BA_ "GenSigTimeoutTime_GNMM" SG_ 609 EPB_HMI_Management 0;
BA_ "GenSigTimeoutTime_EVCU2" SG_ 609 EPB_HMI_Management 0;
BA_ "GenSigTimeoutTime_ESL" SG_ 609 EPB_HMI_Management 0;
BA_ "GenSigTimeoutTime_ECM" SG_ 609 EPB_HMI_Management 0;
BA_ "GenSigTimeoutTime_DTCM" SG_ 609 EPB_HMI_Management 0;
BA_ "GenSigTimeoutTime_DMSM" SG_ 609 EPB_HMI_Management 0;
BA_ "GenSigTimeoutTime_BSM" SG_ 609 EPB_HMI_Management 0;
BA_ "GenSigTimeoutTime_BCM" SG_ 609 EPB_HMI_Management 0;
BA_ "GenSigTimeoutTime_AGSM" SG_ 609 EPB_HMI_Management 0;
BA_ "GenSigTimeoutTime_ADCAM" SG_ 609 EPB_HMI_Management 0;
BA_ "GenSigTimeoutTime_RFHM" SG_ 609 ClampForce 0;
BA_ "GenSigTimeoutTime_MPAD" SG_ 609 ClampForce 0;
BA_ "GenSigTimeoutTime_IPC" SG_ 609 ClampForce 0;
BA_ "GenSigTimeoutTime_GNMM" SG_ 609 ClampForce 0;
BA_ "GenSigTimeoutTime_EVCU2" SG_ 609 ClampForce 0;
BA_ "GenSigTimeoutTime_ESL" SG_ 609 ClampForce 0;
BA_ "GenSigTimeoutTime_ECM" SG_ 609 ClampForce 0;
BA_ "GenSigTimeoutTime_DTCM" SG_ 609 ClampForce 0;
BA_ "GenSigTimeoutTime_DMSM" SG_ 609 ClampForce 0;
BA_ "GenSigTimeoutTime_BSM" SG_ 609 ClampForce 0;
BA_ "GenSigTimeoutTime_AGSM" SG_ 609 ClampForce 0;
BA_ "GenSigTimeoutTime_ADCAM" SG_ 609 ClampForce 0;
BA_ "GenSigTimeoutTime_RFHM" SG_ 609 EPBSts 0;
BA_ "GenSigTimeoutTime_GNMM" SG_ 609 EPBSts 0;
BA_ "GenSigTimeoutTime_ESL" SG_ 609 EPBSts 0;
BA_ "GenSigTimeoutTime_ECM" SG_ 609 EPBSts 0;
BA_ "GenSigTimeoutTime_DMSM" SG_ 609 EPBSts 0;
BA_ "GenSigTimeoutTime_BSM" SG_ 609 EPBSts 0;
BA_ "GenSigTimeoutTime_AGSM" SG_ 609 EPBSts 0;
BA_ "GenSigTimeoutTime_ADCAM" SG_ 609 EPBSts 0;
BA_ "GenSigSendType" SG_ 609 EPBSts 3;
BA_ "GenSigTimeoutTime_RFHM" SG_ 609 ASRActive 0;
BA_ "GenSigTimeoutTime_IPC" SG_ 609 ASRActive 0;
BA_ "GenSigTimeoutTime_GNMM" SG_ 609 ASRActive 0;
BA_ "GenSigTimeoutTime_ESL" SG_ 609 ASRActive 0;
BA_ "GenSigTimeoutTime_ECM" SG_ 609 ASRActive 0;
BA_ "GenSigTimeoutTime_DMSM" SG_ 609 ASRActive 0;
BA_ "GenSigTimeoutTime_BSM" SG_ 609 ASRActive 0;
BA_ "GenSigTimeoutTime_AGSM" SG_ 609 ASRActive 0;
BA_ "GenSigTimeoutTime_ADCAM" SG_ 609 ASRActive 0;
BA_ "GenSigSendType" SG_ 609 ASRActive 3;
BA_ "GenSigTimeoutTime_RFHM" SG_ 259 RHR_WheelSensorFailSts 0;
BA_ "GenSigTimeoutTime_IPC" SG_ 259 RHR_WheelSensorFailSts 0;
BA_ "GenSigTimeoutTime_GNMM" SG_ 259 RHR_WheelSensorFailSts 0;
BA_ "GenSigTimeoutTime_ESL" SG_ 259 RHR_WheelSensorFailSts 0;
BA_ "GenSigTimeoutTime_ECM" SG_ 259 RHR_WheelSensorFailSts 0;
BA_ "GenSigTimeoutTime_DMSM" SG_ 259 RHR_WheelSensorFailSts 0;
BA_ "GenSigTimeoutTime_BSM" SG_ 259 RHR_WheelSensorFailSts 0;
BA_ "GenSigTimeoutTime_AGSM" SG_ 259 RHR_WheelSensorFailSts 0;
BA_ "GenSigTimeoutTime_ADCAM" SG_ 259 RHR_WheelSensorFailSts 0;
BA_ "GenSigTimeoutTime_RFHM" SG_ 259 RHR_Spin 0;
BA_ "GenSigTimeoutTime_IPC" SG_ 259 RHR_Spin 0;
BA_ "GenSigTimeoutTime_GNMM" SG_ 259 RHR_Spin 0;
BA_ "GenSigTimeoutTime_ESL" SG_ 259 RHR_Spin 0;
BA_ "GenSigTimeoutTime_ECM" SG_ 259 RHR_Spin 0;
BA_ "GenSigTimeoutTime_DMSM" SG_ 259 RHR_Spin 0;
BA_ "GenSigTimeoutTime_BSM" SG_ 259 RHR_Spin 0;
BA_ "GenSigTimeoutTime_AGSM" SG_ 259 RHR_Spin 0;
BA_ "GenSigTimeoutTime_ADCAM" SG_ 259 RHR_Spin 0;
BA_ "GenSigTimeoutTime_IPC" SG_ 259 RHR_FastPulseCounter 0;
BA_ "GenSigTimeoutTime_ESL" SG_ 259 RHR_FastPulseCounter 0;
BA_ "GenSigTimeoutTime_ECM" SG_ 259 RHR_FastPulseCounter 0;
BA_ "GenSigTimeoutTime_DTCM" SG_ 259 RHR_FastPulseCounter 0;
BA_ "GenSigTimeoutTime_DMSM" SG_ 259 RHR_FastPulseCounter 0;
BA_ "GenSigTimeoutTime_BSM" SG_ 259 RHR_FastPulseCounter 0;
BA_ "GenSigTimeoutTime_AGSM" SG_ 259 RHR_FastPulseCounter 0;
BA_ "GenSigTimeoutTime_ADCAM" SG_ 259 RHR_FastPulseCounter 0;
BA_ "GenSigTimeoutTime_IPC" SG_ 609 REPRGD_PFC_CLR_BSM 0;
BA_ "GenSigTimeoutTime_GNMM" SG_ 609 REPRGD_PFC_CLR_BSM 0;
BA_ "GenSigTimeoutTime_EVCU2" SG_ 609 REPRGD_PFC_CLR_BSM 0;
BA_ "GenSigTimeoutTime_ESL" SG_ 609 REPRGD_PFC_CLR_BSM 0;
BA_ "GenSigTimeoutTime_DTCM" SG_ 609 REPRGD_PFC_CLR_BSM 0;
BA_ "GenSigTimeoutTime_DMSM" SG_ 609 REPRGD_PFC_CLR_BSM 0;
BA_ "GenSigTimeoutTime_BSM" SG_ 609 REPRGD_PFC_CLR_BSM 0;
BA_ "GenSigTimeoutTime_BCM" SG_ 609 REPRGD_PFC_CLR_BSM 0;
BA_ "GenSigTimeoutTime_AGSM" SG_ 609 REPRGD_PFC_CLR_BSM 0;
BA_ "GenSigTimeoutTime_ADCAM" SG_ 609 REPRGD_PFC_CLR_BSM 0;
BA_ "GenSigTimeoutTime_RFHM" SG_ 609 MIL_OnRq_BSM 0;
BA_ "GenSigTimeoutTime_MPAD" SG_ 609 MIL_OnRq_BSM 0;
BA_ "GenSigTimeoutTime_IPC" SG_ 609 MIL_OnRq_BSM 0;
BA_ "GenSigTimeoutTime_GNMM" SG_ 609 MIL_OnRq_BSM 0;
BA_ "GenSigTimeoutTime_EVCU2" SG_ 609 MIL_OnRq_BSM 0;
BA_ "GenSigTimeoutTime_ESL" SG_ 609 MIL_OnRq_BSM 0;
BA_ "GenSigTimeoutTime_DTCM" SG_ 609 MIL_OnRq_BSM 0;
BA_ "GenSigTimeoutTime_DMSM" SG_ 609 MIL_OnRq_BSM 0;
BA_ "GenSigTimeoutTime_BSM" SG_ 609 MIL_OnRq_BSM 0;
BA_ "GenSigTimeoutTime_BCM" SG_ 609 MIL_OnRq_BSM 0;
BA_ "GenSigTimeoutTime_AGSM" SG_ 609 MIL_OnRq_BSM 0;
BA_ "GenSigTimeoutTime_ADCAM" SG_ 609 MIL_OnRq_BSM 0;
BA_ "GenSigSendType" SG_ 609 MIL_OnRq_BSM 3;
BA_ "GenSigTimeoutTime_SGW" SG_ 609 ESCSysEmsMlfAtv 0;
BA_ "GenSigTimeoutTime_RFHM" SG_ 609 ESCSysEmsMlfAtv 0;
BA_ "GenSigTimeoutTime_MPAD" SG_ 609 ESCSysEmsMlfAtv 0;
BA_ "GenSigTimeoutTime_IPC" SG_ 609 ESCSysEmsMlfAtv 0;
BA_ "GenSigTimeoutTime_GNMM" SG_ 609 ESCSysEmsMlfAtv 0;
BA_ "GenSigTimeoutTime_EVCU2" SG_ 609 ESCSysEmsMlfAtv 0;
BA_ "GenSigTimeoutTime_ESL" SG_ 609 ESCSysEmsMlfAtv 0;
BA_ "GenSigTimeoutTime_ECM" SG_ 609 ESCSysEmsMlfAtv 0;
BA_ "GenSigTimeoutTime_DTCM" SG_ 609 ESCSysEmsMlfAtv 0;
BA_ "GenSigTimeoutTime_DMSM" SG_ 609 ESCSysEmsMlfAtv 0;
BA_ "GenSigTimeoutTime_BSM" SG_ 609 ESCSysEmsMlfAtv 0;
BA_ "GenSigTimeoutTime_BCM" SG_ 609 ESCSysEmsMlfAtv 0;
BA_ "GenSigTimeoutTime_AGSM" SG_ 609 ESCSysEmsMlfAtv 0;
BA_ "GenSigTimeoutTime_ADCAM" SG_ 609 ESCSysEmsMlfAtv 0;
BA_ "GenSigTimeoutTime_SGW" SG_ 609 EPBWarningLampReq 0;
BA_ "GenSigTimeoutTime_RFHM" SG_ 609 EPBWarningLampReq 0;
BA_ "GenSigTimeoutTime_MPAD" SG_ 609 EPBWarningLampReq 0;
BA_ "GenSigTimeoutTime_GNMM" SG_ 609 EPBWarningLampReq 0;
BA_ "GenSigTimeoutTime_EVCU2" SG_ 609 EPBWarningLampReq 0;
BA_ "GenSigTimeoutTime_ESL" SG_ 609 EPBWarningLampReq 0;
BA_ "GenSigTimeoutTime_ECM" SG_ 609 EPBWarningLampReq 0;
BA_ "GenSigTimeoutTime_DTCM" SG_ 609 EPBWarningLampReq 0;
BA_ "GenSigTimeoutTime_DMSM" SG_ 609 EPBWarningLampReq 0;
BA_ "GenSigTimeoutTime_BSM" SG_ 609 EPBWarningLampReq 0;
BA_ "GenSigTimeoutTime_AGSM" SG_ 609 EPBWarningLampReq 0;
BA_ "GenSigTimeoutTime_ADCAM" SG_ 609 EPBWarningLampReq 0;
BA_ "GenSigTimeoutTime_SGW" SG_ 609 MessageCounter_BRAKE4 0;
BA_ "GenSigTimeoutTime_RFHM" SG_ 609 MessageCounter_BRAKE4 0;
BA_ "GenSigTimeoutTime_GNMM" SG_ 609 MessageCounter_BRAKE4 0;
BA_ "GenSigTimeoutTime_ESL" SG_ 609 MessageCounter_BRAKE4 0;
BA_ "GenSigTimeoutTime_ECM" SG_ 609 MessageCounter_BRAKE4 0;
BA_ "GenSigTimeoutTime_DTCM" SG_ 609 MessageCounter_BRAKE4 0;
BA_ "GenSigTimeoutTime_DMSM" SG_ 609 MessageCounter_BRAKE4 0;
BA_ "GenSigTimeoutTime_BSM" SG_ 609 MessageCounter_BRAKE4 0;
BA_ "GenSigTimeoutTime_AGSM" SG_ 609 MessageCounter_BRAKE4 0;
BA_ "GenSigTimeoutTime_ADCAM" SG_ 609 MessageCounter_BRAKE4 0;
BA_ "GenSigTimeoutTime_SGW" SG_ 609 CRC_BRAKE4 0;
BA_ "GenSigTimeoutTime_RFHM" SG_ 609 CRC_BRAKE4 0;
BA_ "GenSigTimeoutTime_GNMM" SG_ 609 CRC_BRAKE4 0;
BA_ "GenSigTimeoutTime_ESL" SG_ 609 CRC_BRAKE4 0;
BA_ "GenSigTimeoutTime_ECM" SG_ 609 CRC_BRAKE4 0;
BA_ "GenSigTimeoutTime_DTCM" SG_ 609 CRC_BRAKE4 0;
BA_ "GenSigTimeoutTime_DMSM" SG_ 609 CRC_BRAKE4 0;
BA_ "GenSigTimeoutTime_BSM" SG_ 609 CRC_BRAKE4 0;
BA_ "GenSigTimeoutTime_AGSM" SG_ 609 CRC_BRAKE4 0;
BA_ "GenSigTimeoutTime_ADCAM" SG_ 609 CRC_BRAKE4 0;
BA_ "GenSigTimeoutTime_SGW" SG_ 609 CODE_CLR_BSM 0;
BA_ "GenSigTimeoutTime_RFHM" SG_ 609 CODE_CLR_BSM 0;
BA_ "GenSigTimeoutTime_MPAD" SG_ 609 CODE_CLR_BSM 0;
BA_ "GenSigTimeoutTime_IPC" SG_ 609 CODE_CLR_BSM 0;
BA_ "GenSigTimeoutTime_GNMM" SG_ 609 CODE_CLR_BSM 0;
BA_ "GenSigTimeoutTime_EVCU2" SG_ 609 CODE_CLR_BSM 0;
BA_ "GenSigTimeoutTime_ESL" SG_ 609 CODE_CLR_BSM 0;
BA_ "GenSigTimeoutTime_DTCM" SG_ 609 CODE_CLR_BSM 0;
BA_ "GenSigTimeoutTime_DMSM" SG_ 609 CODE_CLR_BSM 0;
BA_ "GenSigTimeoutTime_BSM" SG_ 609 CODE_CLR_BSM 0;
BA_ "GenSigTimeoutTime_BCM" SG_ 609 CODE_CLR_BSM 0;
BA_ "GenSigTimeoutTime_AGSM" SG_ 609 CODE_CLR_BSM 0;
BA_ "GenSigTimeoutTime_ADCAM" SG_ 609 CODE_CLR_BSM 0;
BA_ "GenSigTimeoutTime_ADCAM" SG_ 259 RHRWheelSpeed 0;
BA_ "GenSigTimeoutTime_RFHM" SG_ 259 RHRWheelSpeed 0;
BA_ "GenSigTimeoutTime_IPC" SG_ 259 RHRWheelSpeed 0;
BA_ "GenSigTimeoutTime_ESL" SG_ 259 RHRWheelSpeed 0;
BA_ "GenSigTimeoutTime_DMSM" SG_ 259 RHRWheelSpeed 0;
BA_ "GenSigTimeoutTime_BSM" SG_ 259 RHRWheelSpeed 0;
BA_ "GenSigTimeoutTime_AGSM" SG_ 259 RHRWheelSpeed 0;
BA_ "GenSigTimeoutTime_RFHM" SG_ 259 RHFWheelSpeed 0;
BA_ "GenSigTimeoutTime_ADCAM" SG_ 2651930646 Digit_07_AGSM 0;
BA_ "GenSigTimeoutTime_SGW" SG_ 2651930646 Digit_05_AGSM 0;
BA_ "GenSigTimeoutTime_RFHM" SG_ 2651930646 Digit_05_AGSM 0;
BA_ "GenSigTimeoutTime_MPAD" SG_ 2651930646 Digit_05_AGSM 0;
BA_ "GenSigTimeoutTime_IPC" SG_ 2651930646 Digit_05_AGSM 0;
BA_ "GenSigTimeoutTime_GNMM" SG_ 2651930646 Digit_05_AGSM 0;
BA_ "GenSigTimeoutTime_EVCU2" SG_ 2651930646 Digit_05_AGSM 0;
BA_ "GenSigTimeoutTime_ESL" SG_ 2651930646 Digit_05_AGSM 0;
BA_ "GenSigTimeoutTime_ECM" SG_ 2651930646 Digit_05_AGSM 0;
BA_ "GenSigTimeoutTime_DTCM" SG_ 2651930646 Digit_05_AGSM 0;
BA_ "GenSigTimeoutTime_DMSM" SG_ 2651930646 Digit_05_AGSM 0;
BA_ "GenSigTimeoutTime_BSM" SG_ 2651930646 Digit_05_AGSM 0;
BA_ "GenSigTimeoutTime_AGSM" SG_ 2651930646 Digit_05_AGSM 0;
BA_ "GenSigTimeoutTime_ADCAM" SG_ 2651930646 Digit_05_AGSM 0;
BA_ "GenSigTimeoutTime_SGW" SG_ 2651930646 Digit_06_AGSM 0;
BA_ "GenSigTimeoutTime_RFHM" SG_ 2651930646 Digit_06_AGSM 0;
BA_ "GenSigTimeoutTime_MPAD" SG_ 2651930646 Digit_06_AGSM 0;
BA_ "GenSigTimeoutTime_IPC" SG_ 2651930646 Digit_06_AGSM 0;
BA_ "GenSigTimeoutTime_GNMM" SG_ 2651930646 Digit_06_AGSM 0;
BA_ "GenSigTimeoutTime_EVCU2" SG_ 2651930646 Digit_06_AGSM 0;
BA_ "GenSigTimeoutTime_ESL" SG_ 2651930646 Digit_06_AGSM 0;
BA_ "GenSigTimeoutTime_ECM" SG_ 2651930646 Digit_06_AGSM 0;
BA_ "GenSigTimeoutTime_DTCM" SG_ 2651930646 Digit_06_AGSM 0;
BA_ "GenSigTimeoutTime_DMSM" SG_ 2651930646 Digit_06_AGSM 0;
BA_ "GenSigTimeoutTime_BSM" SG_ 2651930646 Digit_06_AGSM 0;
BA_ "GenSigTimeoutTime_AGSM" SG_ 2651930646 Digit_06_AGSM 0;
BA_ "GenSigTimeoutTime_ADCAM" SG_ 2651930646 Digit_06_AGSM 0;
BA_ "GenSigTimeoutTime_SGW" SG_ 2651930646 Digit_01_AGSM 0;
BA_ "GenSigTimeoutTime_RFHM" SG_ 2651930646 Digit_01_AGSM 0;
BA_ "GenSigTimeoutTime_MPAD" SG_ 2651930646 Digit_01_AGSM 0;
BA_ "GenSigTimeoutTime_IPC" SG_ 2651930646 Digit_01_AGSM 0;
BA_ "GenSigTimeoutTime_GNMM" SG_ 2651930646 Digit_01_AGSM 0;
BA_ "GenSigTimeoutTime_EVCU2" SG_ 2651930646 Digit_01_AGSM 0;
BA_ "GenSigTimeoutTime_ESL" SG_ 2651930646 Digit_01_AGSM 0;
BA_ "GenSigTimeoutTime_ECM" SG_ 2651930646 Digit_01_AGSM 0;
BA_ "GenSigTimeoutTime_DTCM" SG_ 2651930646 Digit_01_AGSM 0;
BA_ "GenSigTimeoutTime_DMSM" SG_ 2651930646 Digit_01_AGSM 0;
BA_ "GenSigTimeoutTime_BSM" SG_ 2651930646 Digit_01_AGSM 0;
BA_ "GenSigTimeoutTime_AGSM" SG_ 2651930646 Digit_01_AGSM 0;
BA_ "GenSigTimeoutTime_ADCAM" SG_ 2651930646 Digit_01_AGSM 0;
BA_ "GenSigSendType" SG_ 2651930646 Digit_01_AGSM 1;
BA_ "GenSigTimeoutTime_SGW" SG_ 2651930646 Digit_02_AGSM 0;
BA_ "GenSigTimeoutTime_RFHM" SG_ 2651930646 Digit_02_AGSM 0;
BA_ "GenSigTimeoutTime_MPAD" SG_ 2651930646 Digit_02_AGSM 0;
BA_ "GenSigTimeoutTime_IPC" SG_ 2651930646 Digit_02_AGSM 0;
BA_ "GenSigTimeoutTime_GNMM" SG_ 2651930646 Digit_02_AGSM 0;
BA_ "GenSigTimeoutTime_EVCU2" SG_ 2651930646 Digit_02_AGSM 0;
BA_ "GenSigTimeoutTime_ESL" SG_ 2651930646 Digit_02_AGSM 0;
BA_ "GenSigTimeoutTime_ECM" SG_ 2651930646 Digit_02_AGSM 0;
BA_ "GenSigTimeoutTime_DTCM" SG_ 2651930646 Digit_02_AGSM 0;
BA_ "GenSigTimeoutTime_DMSM" SG_ 2651930646 Digit_02_AGSM 0;
BA_ "GenSigTimeoutTime_BSM" SG_ 2651930646 Digit_02_AGSM 0;
BA_ "GenSigTimeoutTime_AGSM" SG_ 2651930646 Digit_02_AGSM 0;
BA_ "GenSigTimeoutTime_ADCAM" SG_ 2651930646 Digit_02_AGSM 0;
BA_ "GenSigTimeoutTime_SGW" SG_ 2651930646 Digit_03_AGSM 0;
BA_ "GenSigTimeoutTime_RFHM" SG_ 2651930646 Digit_03_AGSM 0;
BA_ "GenSigTimeoutTime_MPAD" SG_ 2651930646 Digit_03_AGSM 0;
BA_ "GenSigTimeoutTime_IPC" SG_ 2651930646 Digit_03_AGSM 0;
BA_ "GenSigTimeoutTime_GNMM" SG_ 2651930646 Digit_03_AGSM 0;
BA_ "GenSigTimeoutTime_EVCU2" SG_ 2651930646 Digit_03_AGSM 0;
BA_ "GenSigTimeoutTime_ESL" SG_ 2651930646 Digit_03_AGSM 0;
BA_ "GenSigTimeoutTime_ECM" SG_ 2651930646 Digit_03_AGSM 0;
BA_ "GenSigTimeoutTime_DTCM" SG_ 2651930646 Digit_03_AGSM 0;
BA_ "GenSigTimeoutTime_DMSM" SG_ 2651930646 Digit_03_AGSM 0;
BA_ "GenSigTimeoutTime_BSM" SG_ 2651930646 Digit_03_AGSM 0;
BA_ "GenSigTimeoutTime_AGSM" SG_ 2651930646 Digit_03_AGSM 0;
BA_ "GenSigTimeoutTime_ADCAM" SG_ 2651930646 Digit_03_AGSM 0;
BA_ "GenSigTimeoutTime_SGW" SG_ 2651930646 Digit_04_AGSM 0;
BA_ "GenSigTimeoutTime_RFHM" SG_ 2651930646 Digit_04_AGSM 0;
BA_ "GenSigTimeoutTime_MPAD" SG_ 2651930646 Digit_04_AGSM 0;
BA_ "GenSigTimeoutTime_IPC" SG_ 2651930646 Digit_04_AGSM 0;
BA_ "GenSigTimeoutTime_GNMM" SG_ 2651930646 Digit_04_AGSM 0;
BA_ "GenSigTimeoutTime_EVCU2" SG_ 2651930646 Digit_04_AGSM 0;
BA_ "GenSigTimeoutTime_ESL" SG_ 2651930646 Digit_04_AGSM 0;
BA_ "GenSigTimeoutTime_ECM" SG_ 2651930646 Digit_04_AGSM 0;
BA_ "GenSigTimeoutTime_DTCM" SG_ 2651930646 Digit_04_AGSM 0;
BA_ "GenSigTimeoutTime_DMSM" SG_ 2651930646 Digit_04_AGSM 0;
BA_ "GenSigTimeoutTime_BSM" SG_ 2651930646 Digit_04_AGSM 0;
BA_ "GenSigTimeoutTime_AGSM" SG_ 2651930646 Digit_04_AGSM 0;
BA_ "GenSigTimeoutTime_ADCAM" SG_ 2651930646 Digit_04_AGSM 0;
BA_ "GenSigTimeoutTime_SGW" SG_ 514 PAM_Brk_Rq_RspSts 0;
BA_ "GenSigTimeoutTime_RFHM" SG_ 514 PAM_Brk_Rq_RspSts 0;
BA_ "GenSigTimeoutTime_MPAD" SG_ 514 PAM_Brk_Rq_RspSts 0;
BA_ "GenSigTimeoutTime_GNMM" SG_ 514 PAM_Brk_Rq_RspSts 0;
BA_ "GenSigTimeoutTime_EVCU2" SG_ 514 PAM_Brk_Rq_RspSts 0;
BA_ "GenSigTimeoutTime_ESL" SG_ 514 PAM_Brk_Rq_RspSts 0;
BA_ "GenSigTimeoutTime_ECM" SG_ 514 PAM_Brk_Rq_RspSts 0;
BA_ "GenSigTimeoutTime_DTCM" SG_ 514 PAM_Brk_Rq_RspSts 0;
BA_ "GenSigTimeoutTime_DMSM" SG_ 514 PAM_Brk_Rq_RspSts 0;
BA_ "GenSigTimeoutTime_BSM" SG_ 514 PAM_Brk_Rq_RspSts 0;
BA_ "GenSigTimeoutTime_AGSM" SG_ 514 PAM_Brk_Rq_RspSts 0;
BA_ "GenSigTimeoutTime_ADCAM" SG_ 514 PAM_Brk_Rq_RspSts 0;
BA_ "GenSigTimeoutTime_SGW" SG_ 514 CRC_BRAKE7 0;
BA_ "GenSigTimeoutTime_RFHM" SG_ 514 CRC_BRAKE7 0;
BA_ "GenSigTimeoutTime_IPC" SG_ 514 CRC_BRAKE7 0;
BA_ "GenSigTimeoutTime_GNMM" SG_ 514 CRC_BRAKE7 0;
BA_ "GenSigTimeoutTime_ESL" SG_ 514 CRC_BRAKE7 0;
BA_ "GenSigTimeoutTime_ECM" SG_ 514 CRC_BRAKE7 0;
BA_ "GenSigTimeoutTime_DTCM" SG_ 514 CRC_BRAKE7 0;
BA_ "GenSigTimeoutTime_DMSM" SG_ 514 CRC_BRAKE7 0;
BA_ "GenSigTimeoutTime_BSM" SG_ 514 CRC_BRAKE7 0;
BA_ "GenSigTimeoutTime_AGSM" SG_ 514 CRC_BRAKE7 0;
BA_ "GenSigTimeoutTime_SGW" SG_ 514 MessageCounter_BRAKE7 0;
BA_ "GenSigTimeoutTime_RFHM" SG_ 514 MessageCounter_BRAKE7 0;
BA_ "GenSigTimeoutTime_IPC" SG_ 514 MessageCounter_BRAKE7 0;
BA_ "GenSigTimeoutTime_GNMM" SG_ 514 MessageCounter_BRAKE7 0;
BA_ "GenSigTimeoutTime_ESL" SG_ 514 MessageCounter_BRAKE7 0;
BA_ "GenSigTimeoutTime_ECM" SG_ 514 MessageCounter_BRAKE7 0;
BA_ "GenSigTimeoutTime_DTCM" SG_ 514 MessageCounter_BRAKE7 0;
BA_ "GenSigTimeoutTime_DMSM" SG_ 514 MessageCounter_BRAKE7 0;
BA_ "GenSigTimeoutTime_BSM" SG_ 514 MessageCounter_BRAKE7 0;
BA_ "GenSigTimeoutTime_AGSM" SG_ 514 MessageCounter_BRAKE7 0;
BA_ "GenSigTimeoutTime_SGW" SG_ 514 HoldnGoLEDSts 0;
BA_ "GenSigTimeoutTime_RFHM" SG_ 514 HoldnGoLEDSts 0;
BA_ "GenSigTimeoutTime_MPAD" SG_ 514 HoldnGoLEDSts 0;
BA_ "GenSigTimeoutTime_IPC" SG_ 514 HoldnGoLEDSts 0;
BA_ "GenSigTimeoutTime_GNMM" SG_ 514 HoldnGoLEDSts 0;
BA_ "GenSigTimeoutTime_EVCU2" SG_ 514 HoldnGoLEDSts 0;
BA_ "GenSigTimeoutTime_ESL" SG_ 514 HoldnGoLEDSts 0;
BA_ "GenSigTimeoutTime_ECM" SG_ 514 HoldnGoLEDSts 0;
BA_ "GenSigTimeoutTime_DTCM" SG_ 514 HoldnGoLEDSts 0;
BA_ "GenSigTimeoutTime_DMSM" SG_ 514 HoldnGoLEDSts 0;
BA_ "GenSigTimeoutTime_BSM" SG_ 514 HoldnGoLEDSts 0;
BA_ "GenSigTimeoutTime_AGSM" SG_ 514 HoldnGoLEDSts 0;
BA_ "GenSigTimeoutTime_ADCAM" SG_ 514 HoldnGoLEDSts 0;
BA_ "GenSigTimeoutTime_RFHM" SG_ 514 BrakePdlPosn 0;
BA_ "GenSigTimeoutTime_MPAD" SG_ 514 BrakePdlPosn 0;
BA_ "GenSigTimeoutTime_IPC" SG_ 514 BrakePdlPosn 0;
BA_ "GenSigTimeoutTime_GNMM" SG_ 514 BrakePdlPosn 0;
BA_ "GenSigTimeoutTime_ESL" SG_ 514 BrakePdlPosn 0;
BA_ "GenSigTimeoutTime_DTCM" SG_ 514 BrakePdlPosn 0;
BA_ "GenSigTimeoutTime_DMSM" SG_ 514 BrakePdlPosn 0;
BA_ "GenSigTimeoutTime_BSM" SG_ 514 BrakePdlPosn 0;
BA_ "GenSigTimeoutTime_AGSM" SG_ 514 BrakePdlPosn 0;
BA_ "GenSigTimeoutTime_ADCAM" SG_ 514 BrakePdlPosn 0;
BA_ "GenSigTimeoutTime_SGW" SG_ 514 AVHTextDispaly 0;
BA_ "GenSigTimeoutTime_RFHM" SG_ 514 AVHTextDispaly 0;
BA_ "GenSigTimeoutTime_MPAD" SG_ 514 AVHTextDispaly 0;
BA_ "GenSigTimeoutTime_GNMM" SG_ 514 AVHTextDispaly 0;
BA_ "GenSigTimeoutTime_EVCU2" SG_ 514 AVHTextDispaly 0;
BA_ "GenSigTimeoutTime_ESL" SG_ 514 AVHTextDispaly 0;
BA_ "GenSigTimeoutTime_ECM" SG_ 514 AVHTextDispaly 0;
BA_ "GenSigTimeoutTime_DTCM" SG_ 514 AVHTextDispaly 0;
BA_ "GenSigTimeoutTime_DMSM" SG_ 514 AVHTextDispaly 0;
BA_ "GenSigTimeoutTime_BSM" SG_ 514 AVHTextDispaly 0;
BA_ "GenSigTimeoutTime_RFHM" SG_ 514 BrkPdl_Flt 0;
BA_ "GenSigTimeoutTime_IPC" SG_ 514 BrkPdl_Flt 0;
BA_ "GenSigTimeoutTime_GNMM" SG_ 514 BrkPdl_Flt 0;
BA_ "GenSigTimeoutTime_ESL" SG_ 514 BrkPdl_Flt 0;
BA_ "GenSigTimeoutTime_DMSM" SG_ 514 BrkPdl_Flt 0;
BA_ "GenSigTimeoutTime_BSM" SG_ 514 BrkPdl_Flt 0;
BA_ "GenSigTimeoutTime_AGSM" SG_ 514 BrkPdl_Flt 0;
BA_ "GenSigTimeoutTime_ADCAM" SG_ 514 BrkPdl_Flt 0;
BA_ "GenSigTimeoutTime_GNMM" SG_ 514 BrkPdl_Stat 0;
BA_ "GenSigTimeoutTime_ESL" SG_ 514 BrkPdl_Stat 0;
BA_ "GenSigTimeoutTime_DMSM" SG_ 514 BrkPdl_Stat 0;
BA_ "GenSigTimeoutTime_BSM" SG_ 514 BrkPdl_Stat 0;
BA_ "GenSigTimeoutTime_AGSM" SG_ 514 BrkPdl_Stat 0;
BA_ "GenSigTimeoutTime_ADCAM" SG_ 514 BrkPdl_Stat 0;
BA_ "GenSigStartValue" SG_ 514 BrkPdl_Stat 3;
BA_ "GenSigTimeoutTime_SGW" SG_ 514 Rear_Diff_BSM_RQ 0;
BA_ "GenSigTimeoutTime_RFHM" SG_ 514 Rear_Diff_BSM_RQ 0;
BA_ "GenSigTimeoutTime_MPAD" SG_ 514 Rear_Diff_BSM_RQ 0;
BA_ "GenSigTimeoutTime_IPC" SG_ 514 Rear_Diff_BSM_RQ 0;
BA_ "GenSigTimeoutTime_GNMM" SG_ 514 Rear_Diff_BSM_RQ 0;
BA_ "GenSigTimeoutTime_EVCU2" SG_ 514 Rear_Diff_BSM_RQ 0;
BA_ "GenSigTimeoutTime_ESL" SG_ 514 Rear_Diff_BSM_RQ 0;
BA_ "GenSigTimeoutTime_ECM" SG_ 514 Rear_Diff_BSM_RQ 0;
BA_ "GenSigTimeoutTime_DMSM" SG_ 514 Rear_Diff_BSM_RQ 0;
BA_ "GenSigTimeoutTime_BSM" SG_ 514 Rear_Diff_BSM_RQ 0;
BA_ "GenSigTimeoutTime_AGSM" SG_ 514 Rear_Diff_BSM_RQ 0;
BA_ "GenSigTimeoutTime_ADCAM" SG_ 514 Rear_Diff_BSM_RQ 0;
BA_ "GenSigTimeoutTime_BCM" SG_ 514 AVHTextDispaly 0;
BA_ "GenSigTimeoutTime_AGSM" SG_ 514 AVHTextDispaly 0;
BA_ "GenSigTimeoutTime_ADCAM" SG_ 514 AVHTextDispaly 0;
BA_ "GenSigTimeoutTime_SGW" SG_ 514 AutoVehHoldSts 0;
BA_ "GenSigTimeoutTime_RFHM" SG_ 514 AutoVehHoldSts 0;
BA_ "GenSigTimeoutTime_GNMM" SG_ 514 AutoVehHoldSts 0;
BA_ "GenSigTimeoutTime_ESL" SG_ 514 AutoVehHoldSts 0;
BA_ "GenSigTimeoutTime_ECM" SG_ 514 AutoVehHoldSts 0;
BA_ "GenSigTimeoutTime_DTCM" SG_ 514 AutoVehHoldSts 0;
BA_ "GenSigTimeoutTime_DMSM" SG_ 514 AutoVehHoldSts 0;
BA_ "GenSigTimeoutTime_BSM" SG_ 514 AutoVehHoldSts 0;
BA_ "GenSigTimeoutTime_AGSM" SG_ 514 AutoVehHoldSts 0;
BA_ "GenSigTimeoutTime_ADCAM" SG_ 514 AutoVehHoldSts 0;
BA_ "GenSigTimeoutTime_SGW" SG_ 1155 HDCUserFdBck 0;
BA_ "GenSigTimeoutTime_RFHM" SG_ 1155 HDCUserFdBck 0;
BA_ "GenSigTimeoutTime_MPAD" SG_ 1155 HDCUserFdBck 0;
BA_ "GenSigTimeoutTime_GNMM" SG_ 1155 HDCUserFdBck 0;
BA_ "GenSigTimeoutTime_EVCU2" SG_ 1155 HDCUserFdBck 0;
BA_ "GenSigTimeoutTime_ESL" SG_ 1155 HDCUserFdBck 0;
BA_ "GenSigTimeoutTime_ECM" SG_ 1155 HDCUserFdBck 0;
BA_ "GenSigTimeoutTime_DTCM" SG_ 1155 HDCUserFdBck 0;
BA_ "GenSigTimeoutTime_DMSM" SG_ 1155 HDCUserFdBck 0;
BA_ "GenSigTimeoutTime_BSM" SG_ 1155 HDCUserFdBck 0;
BA_ "GenSigTimeoutTime_BCM" SG_ 1155 HDCUserFdBck 0;
BA_ "GenSigTimeoutTime_AGSM" SG_ 1155 HDCUserFdBck 0;
BA_ "GenSigTimeoutTime_ADCAM" SG_ 1155 HDCUserFdBck 0;
BA_ "GenSigSendType" SG_ 1155 HDCUserFdBck 3;
BA_ "GenSigStartValue" SG_ 1155 HDCUserFdBck 1;
BA_ "GenSigTimeoutTime_SGW" SG_ 1155 CRC_BRAKE5 0;
BA_ "GenSigTimeoutTime_RFHM" SG_ 1155 CRC_BRAKE5 0;
BA_ "GenSigTimeoutTime_GNMM" SG_ 1155 CRC_BRAKE5 0;
BA_ "GenSigTimeoutTime_ESL" SG_ 1155 CRC_BRAKE5 0;
BA_ "GenSigTimeoutTime_ECM" SG_ 1155 CRC_BRAKE5 0;
BA_ "GenSigTimeoutTime_DTCM" SG_ 1155 CRC_BRAKE5 0;
BA_ "GenSigTimeoutTime_DMSM" SG_ 1155 CRC_BRAKE5 0;
BA_ "GenSigTimeoutTime_BSM" SG_ 1155 CRC_BRAKE5 0;
BA_ "GenSigTimeoutTime_BCM" SG_ 1155 CRC_BRAKE5 0;
BA_ "GenSigTimeoutTime_AGSM" SG_ 1155 CRC_BRAKE5 0;
BA_ "GenSigTimeoutTime_ADCAM" SG_ 1155 CRC_BRAKE5 0;
BA_ "GenSigTimeoutTime_SGW" SG_ 1155 MessageCounter_BRAKE5 0;
BA_ "GenSigTimeoutTime_RFHM" SG_ 1155 MessageCounter_BRAKE5 0;
BA_ "GenSigTimeoutTime_GNMM" SG_ 1155 MessageCounter_BRAKE5 0;
BA_ "GenSigTimeoutTime_ESL" SG_ 1155 MessageCounter_BRAKE5 0;
BA_ "GenSigTimeoutTime_ECM" SG_ 1155 MessageCounter_BRAKE5 0;
BA_ "GenSigTimeoutTime_DTCM" SG_ 1155 MessageCounter_BRAKE5 0;
BA_ "GenSigTimeoutTime_DMSM" SG_ 1155 MessageCounter_BRAKE5 0;
BA_ "GenSigTimeoutTime_BSM" SG_ 1155 MessageCounter_BRAKE5 0;
BA_ "GenSigTimeoutTime_BCM" SG_ 1155 MessageCounter_BRAKE5 0;
BA_ "GenSigTimeoutTime_AGSM" SG_ 1155 MessageCounter_BRAKE5 0;
BA_ "GenSigTimeoutTime_ADCAM" SG_ 1155 MessageCounter_BRAKE5 0;
BA_ "GenSigTimeoutTime_SGW" SG_ 609 REPRGD_PFC_CLR_BSM 0;
BA_ "GenSigTimeoutTime_RFHM" SG_ 609 REPRGD_PFC_CLR_BSM 0;
BA_ "GenSigTimeoutTime_MPAD" SG_ 609 REPRGD_PFC_CLR_BSM 0;
BA_ "GenSigTimeoutTime_SGW" SG_ 1155 CMMIntervention 0;
BA_ "GenSigTimeoutTime_RFHM" SG_ 1155 CMMIntervention 0;
BA_ "GenSigTimeoutTime_MPAD" SG_ 1155 CMMIntervention 0;
BA_ "GenSigTimeoutTime_IPC" SG_ 1155 CMMIntervention 0;
BA_ "GenSigTimeoutTime_GNMM" SG_ 1155 CMMIntervention 0;
BA_ "GenSigTimeoutTime_EVCU2" SG_ 1155 CMMIntervention 0;
BA_ "GenSigTimeoutTime_ESL" SG_ 1155 CMMIntervention 0;
BA_ "GenSigTimeoutTime_ECM" SG_ 1155 CMMIntervention 0;
BA_ "GenSigTimeoutTime_DTCM" SG_ 1155 CMMIntervention 0;
BA_ "GenSigTimeoutTime_DMSM" SG_ 1155 CMMIntervention 0;
BA_ "GenSigTimeoutTime_BSM" SG_ 1155 CMMIntervention 0;
BA_ "GenSigTimeoutTime_BCM" SG_ 1155 CMMIntervention 0;
BA_ "GenSigTimeoutTime_AGSM" SG_ 1155 CMMIntervention 0;
BA_ "GenSigTimeoutTime_ADCAM" SG_ 1155 CMMIntervention 0;
BA_ "GenSigSendType" SG_ 1155 CMMIntervention 3;
BA_ "GenSigTimeoutTime_RFHM" SG_ 1155 EBDFailSts 0;
BA_ "GenSigTimeoutTime_MPAD" SG_ 1155 EBDFailSts 0;
BA_ "GenSigTimeoutTime_SGW" SG_ 514 Brake_OpStat_Prim 0;
BA_ "GenSigTimeoutTime_RFHM" SG_ 514 Brake_OpStat_Prim 0;
BA_ "GenSigTimeoutTime_IPC" SG_ 514 Brake_OpStat_Prim 0;
BA_ "GenSigTimeoutTime_GNMM" SG_ 514 Brake_OpStat_Prim 0;
BA_ "GenSigTimeoutTime_EVCU2" SG_ 514 Brake_OpStat_Prim 0;
BA_ "GenSigTimeoutTime_ESL" SG_ 514 Brake_OpStat_Prim 0;
BA_ "GenSigTimeoutTime_ECM" SG_ 514 Brake_OpStat_Prim 0;
BA_ "GenSigTimeoutTime_DTCM" SG_ 514 Brake_OpStat_Prim 0;
BA_ "GenSigTimeoutTime_DMSM" SG_ 514 Brake_OpStat_Prim 0;
BA_ "GenSigTimeoutTime_BSM" SG_ 514 Brake_OpStat_Prim 0;
BA_ "GenSigTimeoutTime_BCM" SG_ 514 Brake_OpStat_Prim 0;
BA_ "GenSigTimeoutTime_AGSM" SG_ 514 Brake_OpStat_Prim 0;
BA_ "GenSigTimeoutTime_ADCAM" SG_ 514 Brake_OpStat_Prim 0;
BA_ "GenSigTimeoutTime_SGW" SG_ 514 BSM_OpStat 0;
BA_ "GenSigTimeoutTime_RFHM" SG_ 514 BSM_OpStat 0;
BA_ "GenSigTimeoutTime_IPC" SG_ 514 BSM_OpStat 0;
BA_ "GenSigTimeoutTime_GNMM" SG_ 514 BSM_OpStat 0;
BA_ "GenSigTimeoutTime_EVCU2" SG_ 514 BSM_OpStat 0;
BA_ "GenSigTimeoutTime_ESL" SG_ 514 BSM_OpStat 0;
BA_ "GenSigTimeoutTime_ECM" SG_ 514 BSM_OpStat 0;
BA_ "GenSigTimeoutTime_DMSM" SG_ 514 BSM_OpStat 0;
BA_ "GenSigTimeoutTime_BSM" SG_ 514 BSM_OpStat 0;
BA_ "GenSigTimeoutTime_AGSM" SG_ 514 BSM_OpStat 0;
BA_ "GenSigTimeoutTime_ADCAM" SG_ 514 BSM_OpStat 0;
BA_ "GenSigTimeoutTime_SGW" SG_ 514 R_DIFF_TRQ_RQ 0;
BA_ "GenSigTimeoutTime_RFHM" SG_ 514 R_DIFF_TRQ_RQ 0;
BA_ "GenSigTimeoutTime_MPAD" SG_ 514 R_DIFF_TRQ_RQ 0;
BA_ "GenSigTimeoutTime_IPC" SG_ 514 R_DIFF_TRQ_RQ 0;
BA_ "GenSigTimeoutTime_GNMM" SG_ 514 R_DIFF_TRQ_RQ 0;
BA_ "GenSigTimeoutTime_EVCU2" SG_ 514 R_DIFF_TRQ_RQ 0;
BA_ "GenSigTimeoutTime_ESL" SG_ 514 R_DIFF_TRQ_RQ 0;
BA_ "GenSigTimeoutTime_ECM" SG_ 514 R_DIFF_TRQ_RQ 0;
BA_ "GenSigTimeoutTime_DMSM" SG_ 514 R_DIFF_TRQ_RQ 0;
BA_ "GenSigTimeoutTime_BSM" SG_ 514 R_DIFF_TRQ_RQ 0;
BA_ "GenSigTimeoutTime_BCM" SG_ 514 R_DIFF_TRQ_RQ 0;
BA_ "GenSigTimeoutTime_AGSM" SG_ 514 R_DIFF_TRQ_RQ 0;
BA_ "GenSigTimeoutTime_ADCAM" SG_ 514 R_DIFF_TRQ_RQ 0;
BA_ "GenSigStartValue" SG_ 514 R_DIFF_TRQ_RQ 511;
BA_ "GenSigTimeoutTime_SGW" SG_ 514 AEB_Type_Brk 0;
BA_ "GenSigTimeoutTime_RFHM" SG_ 514 AEB_Type_Brk 0;
BA_ "GenSigTimeoutTime_IPC" SG_ 514 AEB_Type_Brk 0;
BA_ "GenSigTimeoutTime_GNMM" SG_ 514 AEB_Type_Brk 0;
BA_ "GenSigTimeoutTime_EVCU2" SG_ 514 AEB_Type_Brk 0;
BA_ "GenSigTimeoutTime_ESL" SG_ 514 AEB_Type_Brk 0;
BA_ "GenSigTimeoutTime_ECM" SG_ 514 AEB_Type_Brk 0;
BA_ "GenSigTimeoutTime_DTCM" SG_ 514 AEB_Type_Brk 0;
BA_ "GenSigTimeoutTime_DMSM" SG_ 514 AEB_Type_Brk 0;
BA_ "GenSigTimeoutTime_BSM" SG_ 514 AEB_Type_Brk 0;
BA_ "GenSigTimeoutTime_BCM" SG_ 514 AEB_Type_Brk 0;
BA_ "GenSigTimeoutTime_AGSM" SG_ 514 AEB_Type_Brk 0;
BA_ "GenSigTimeoutTime_SGW" SG_ 1155 FunctionSts 0;
BA_ "GenSigTimeoutTime_RFHM" SG_ 1155 FunctionSts 0;
BA_ "GenSigTimeoutTime_GNMM" SG_ 1155 FunctionSts 0;
BA_ "GenSigTimeoutTime_EVCU2" SG_ 1155 FunctionSts 0;
BA_ "GenSigTimeoutTime_ESL" SG_ 1155 FunctionSts 0;
BA_ "GenSigTimeoutTime_ECM" SG_ 1155 FunctionSts 0;
BA_ "GenSigTimeoutTime_DMSM" SG_ 1155 FunctionSts 0;
BA_ "GenSigTimeoutTime_BSM" SG_ 1155 FunctionSts 0;
BA_ "GenSigTimeoutTime_AGSM" SG_ 1155 FunctionSts 0;
BA_ "GenSigSendType" SG_ 1155 FunctionSts 3;
BA_ "GenSigTimeoutTime_SGW" SG_ 1155 HillHolderFailSts 0;
BA_ "GenSigTimeoutTime_RFHM" SG_ 1155 HillHolderFailSts 0;
BA_ "GenSigTimeoutTime_MPAD" SG_ 1155 HillHolderFailSts 0;
BA_ "GenSigTimeoutTime_IPC" SG_ 1155 HillHolderFailSts 0;
BA_ "GenSigTimeoutTime_GNMM" SG_ 1155 HillHolderFailSts 0;
BA_ "GenSigTimeoutTime_EVCU2" SG_ 1155 HillHolderFailSts 0;
BA_ "GenSigTimeoutTime_ESL" SG_ 1155 HillHolderFailSts 0;
BA_ "GenSigTimeoutTime_ECM" SG_ 1155 HillHolderFailSts 0;
BA_ "GenSigTimeoutTime_DTCM" SG_ 1155 HillHolderFailSts 0;
BA_ "GenSigTimeoutTime_DMSM" SG_ 1155 HillHolderFailSts 0;
BA_ "GenSigTimeoutTime_BSM" SG_ 1155 HillHolderFailSts 0;
BA_ "GenSigTimeoutTime_BCM" SG_ 1155 HillHolderFailSts 0;
BA_ "GenSigTimeoutTime_AGSM" SG_ 1155 HillHolderFailSts 0;
BA_ "GenSigTimeoutTime_ADCAM" SG_ 1155 HillHolderFailSts 0;
BA_ "GenSigSendType" SG_ 1155 HillHolderFailSts 3;
BA_ "GenSigTimeoutTime_ESL" SG_ 259 RHF_Spin 0;
BA_ "GenSigTimeoutTime_ECM" SG_ 259 RHF_Spin 0;
BA_ "GenSigTimeoutTime_DMSM" SG_ 259 RHF_Spin 0;
BA_ "GenSigTimeoutTime_BSM" SG_ 259 RHF_Spin 0;
BA_ "GenSigTimeoutTime_AGSM" SG_ 259 RHF_Spin 0;
BA_ "GenSigTimeoutTime_ADCAM" SG_ 259 RHF_Spin 0;
BA_ "GenSigTimeoutTime_IPC" SG_ 259 RHFWheelSpeed 0;
BA_ "GenSigTimeoutTime_ESL" SG_ 259 RHFWheelSpeed 0;
BA_ "GenSigTimeoutTime_DMSM" SG_ 259 RHFWheelSpeed 0;
BA_ "GenSigTimeoutTime_BSM" SG_ 259 RHFWheelSpeed 0;
BA_ "GenSigTimeoutTime_AGSM" SG_ 259 RHFWheelSpeed 0;
BA_ "GenSigTimeoutTime_ADCAM" SG_ 259 RHFWheelSpeed 0;
BA_ "GenSigTimeoutTime_IPC" SG_ 259 LHF_FastPulseCounter 0;
BA_ "GenSigTimeoutTime_ESL" SG_ 259 LHF_FastPulseCounter 0;
BA_ "GenSigTimeoutTime_ECM" SG_ 259 LHF_FastPulseCounter 0;
BA_ "GenSigTimeoutTime_DTCM" SG_ 259 LHF_FastPulseCounter 0;
BA_ "GenSigTimeoutTime_DMSM" SG_ 259 LHF_FastPulseCounter 0;
BA_ "GenSigTimeoutTime_BSM" SG_ 259 LHF_FastPulseCounter 0;
BA_ "GenSigTimeoutTime_AGSM" SG_ 259 LHF_FastPulseCounter 0;
BA_ "GenSigTimeoutTime_ADCAM" SG_ 259 LHF_FastPulseCounter 0;
BA_ "GenSigTimeoutTime_RFHM" SG_ 259 LHF_WheelSensorFailSts 0;
BA_ "GenSigTimeoutTime_IPC" SG_ 259 LHF_WheelSensorFailSts 0;
BA_ "GenSigTimeoutTime_GNMM" SG_ 259 LHF_WheelSensorFailSts 0;
BA_ "GenSigTimeoutTime_ESL" SG_ 259 LHF_WheelSensorFailSts 0;
BA_ "GenSigTimeoutTime_ECM" SG_ 259 LHF_WheelSensorFailSts 0;
BA_ "GenSigTimeoutTime_DMSM" SG_ 259 LHF_WheelSensorFailSts 0;
BA_ "GenSigTimeoutTime_BSM" SG_ 259 LHF_WheelSensorFailSts 0;
BA_ "GenSigTimeoutTime_AGSM" SG_ 259 LHF_WheelSensorFailSts 0;
BA_ "GenSigTimeoutTime_ADCAM" SG_ 259 LHF_WheelSensorFailSts 0;
BA_ "GenSigTimeoutTime_IPC" SG_ 259 LHR_FastPulseCounter 0;
BA_ "GenSigTimeoutTime_ESL" SG_ 259 LHR_FastPulseCounter 0;
BA_ "GenSigTimeoutTime_ECM" SG_ 259 LHR_FastPulseCounter 0;
BA_ "GenSigTimeoutTime_DTCM" SG_ 259 LHR_FastPulseCounter 0;
BA_ "GenSigTimeoutTime_DMSM" SG_ 259 LHR_FastPulseCounter 0;
BA_ "GenSigTimeoutTime_BSM" SG_ 259 LHR_FastPulseCounter 0;
BA_ "GenSigTimeoutTime_AGSM" SG_ 259 LHR_FastPulseCounter 0;
BA_ "GenSigTimeoutTime_ADCAM" SG_ 259 LHR_FastPulseCounter 0;
BA_ "GenSigTimeoutTime_RFHM" SG_ 259 LHR_Spin 0;
BA_ "GenSigTimeoutTime_IPC" SG_ 259 LHR_Spin 0;
BA_ "GenSigTimeoutTime_GNMM" SG_ 259 LHR_Spin 0;
BA_ "GenSigTimeoutTime_ESL" SG_ 259 LHR_Spin 0;
BA_ "GenSigTimeoutTime_ECM" SG_ 259 LHR_Spin 0;
BA_ "GenSigTimeoutTime_DMSM" SG_ 259 LHR_Spin 0;
BA_ "GenSigTimeoutTime_BSM" SG_ 259 LHR_Spin 0;
BA_ "GenSigTimeoutTime_AGSM" SG_ 259 LHR_Spin 0;
BA_ "GenSigTimeoutTime_ADCAM" SG_ 259 LHR_Spin 0;
BA_ "GenSigTimeoutTime_RFHM" SG_ 259 LHR_WheelSensorFailSts 0;
BA_ "GenSigTimeoutTime_IPC" SG_ 259 LHR_WheelSensorFailSts 0;
BA_ "GenSigTimeoutTime_GNMM" SG_ 259 LHR_WheelSensorFailSts 0;
BA_ "GenSigTimeoutTime_ESL" SG_ 259 LHR_WheelSensorFailSts 0;
BA_ "GenSigTimeoutTime_ECM" SG_ 259 LHR_WheelSensorFailSts 0;
BA_ "GenSigTimeoutTime_DMSM" SG_ 259 LHR_WheelSensorFailSts 0;
BA_ "GenSigTimeoutTime_BSM" SG_ 259 LHR_WheelSensorFailSts 0;
BA_ "GenSigTimeoutTime_AGSM" SG_ 259 LHR_WheelSensorFailSts 0;
BA_ "GenSigTimeoutTime_ADCAM" SG_ 259 LHR_WheelSensorFailSts 0;
BA_ "GenSigTimeoutTime_IPC" SG_ 259 RHF_FastPulseCounter 0;
BA_ "GenSigTimeoutTime_ESL" SG_ 259 RHF_FastPulseCounter 0;
BA_ "GenSigTimeoutTime_ECM" SG_ 259 RHF_FastPulseCounter 0;
BA_ "GenSigTimeoutTime_DTCM" SG_ 259 RHF_FastPulseCounter 0;
BA_ "GenSigTimeoutTime_DMSM" SG_ 259 RHF_FastPulseCounter 0;
BA_ "GenSigTimeoutTime_BSM" SG_ 259 RHF_FastPulseCounter 0;
BA_ "GenSigTimeoutTime_AGSM" SG_ 259 RHF_FastPulseCounter 0;
BA_ "GenSigTimeoutTime_ADCAM" SG_ 259 RHF_FastPulseCounter 0;
BA_ "GenSigTimeoutTime_RFHM" SG_ 259 RHF_WheelSensorFailSts 0;
BA_ "GenSigTimeoutTime_IPC" SG_ 259 RHF_WheelSensorFailSts 0;
BA_ "GenSigTimeoutTime_GNMM" SG_ 259 RHF_WheelSensorFailSts 0;
BA_ "GenSigTimeoutTime_ESL" SG_ 259 RHF_WheelSensorFailSts 0;
BA_ "GenSigTimeoutTime_ECM" SG_ 259 RHF_WheelSensorFailSts 0;
BA_ "GenSigTimeoutTime_DMSM" SG_ 259 RHF_WheelSensorFailSts 0;
BA_ "GenSigTimeoutTime_BSM" SG_ 259 RHF_WheelSensorFailSts 0;
BA_ "GenSigTimeoutTime_AGSM" SG_ 259 RHF_WheelSensorFailSts 0;
BA_ "GenSigTimeoutTime_ADCAM" SG_ 259 RHF_WheelSensorFailSts 0;
BA_ "GenSigTimeoutTime_SGW" SG_ 1056 CRC_EPS2 0;
BA_ "GenSigTimeoutTime_RFHM" SG_ 1056 CRC_EPS2 0;
BA_ "GenSigTimeoutTime_GNMM" SG_ 1056 CRC_EPS2 0;
BA_ "GenSigTimeoutTime_EVCU2" SG_ 1056 CRC_EPS2 0;
BA_ "GenSigTimeoutTime_ESL" SG_ 1056 CRC_EPS2 0;
BA_ "GenSigTimeoutTime_ECM" SG_ 1056 CRC_EPS2 0;
BA_ "GenSigTimeoutTime_DTCM" SG_ 1056 CRC_EPS2 0;
BA_ "GenSigTimeoutTime_DMSM" SG_ 1056 CRC_EPS2 0;
BA_ "GenSigTimeoutTime_BCM" SG_ 1056 CRC_EPS2 0;
BA_ "GenSigTimeoutTime_AGSM" SG_ 1056 CRC_EPS2 0;
BA_ "GenSigTimeoutTime_ADCAM" SG_ 1056 CRC_EPS2 0;
BA_ "GenSigTimeoutTime_SGW" SG_ 1056 MessageCounter_EPS2 0;
BA_ "GenSigTimeoutTime_RFHM" SG_ 1056 MessageCounter_EPS2 0;
BA_ "GenSigTimeoutTime_GNMM" SG_ 1056 MessageCounter_EPS2 0;
BA_ "GenSigTimeoutTime_EVCU2" SG_ 1056 MessageCounter_EPS2 0;
BA_ "GenSigTimeoutTime_ESL" SG_ 1056 MessageCounter_EPS2 0;
BA_ "GenSigTimeoutTime_ECM" SG_ 1056 MessageCounter_EPS2 0;
BA_ "GenSigTimeoutTime_DTCM" SG_ 1056 MessageCounter_EPS2 0;
BA_ "GenSigTimeoutTime_DMSM" SG_ 1056 MessageCounter_EPS2 0;
BA_ "GenSigTimeoutTime_BCM" SG_ 1056 MessageCounter_EPS2 0;
BA_ "GenSigTimeoutTime_AGSM" SG_ 1056 MessageCounter_EPS2 0;
BA_ "GenSigTimeoutTime_ADCAM" SG_ 1056 MessageCounter_EPS2 0;
BA_ "GenSigTimeoutTime_SGW" SG_ 264 LwsAngle_F 0;
BA_ "GenSigTimeoutTime_RFHM" SG_ 264 LwsAngle_F 0;
BA_ "GenSigTimeoutTime_IPC" SG_ 264 LwsAngle_F 0;
BA_ "GenSigTimeoutTime_GNMM" SG_ 264 LwsAngle_F 0;
BA_ "GenSigTimeoutTime_EVCU2" SG_ 264 LwsAngle_F 0;
BA_ "GenSigTimeoutTime_ESL" SG_ 264 LwsAngle_F 0;
BA_ "GenSigTimeoutTime_ECM" SG_ 264 LwsAngle_F 0;
BA_ "GenSigTimeoutTime_DTCM" SG_ 264 LwsAngle_F 0;
BA_ "GenSigTimeoutTime_DMSM" SG_ 264 LwsAngle_F 0;
BA_ "GenSigTimeoutTime_BCM" SG_ 264 LwsAngle_F 0;
BA_ "GenSigTimeoutTime_AGSM" SG_ 264 LwsAngle_F 0;
BA_ "GenSigTimeoutTime_ADCAM" SG_ 264 LwsAngle_F 0;
BA_ "GenSigTimeoutTime_RFHM" SG_ 1056 EPS_Warn_Disp_Rq 0;
BA_ "GenSigTimeoutTime_GNMM" SG_ 1056 EPS_Warn_Disp_Rq 0;
BA_ "GenSigTimeoutTime_EVCU2" SG_ 1056 EPS_Warn_Disp_Rq 0;
BA_ "GenSigTimeoutTime_ESL" SG_ 1056 EPS_Warn_Disp_Rq 0;
BA_ "GenSigTimeoutTime_ECM" SG_ 1056 EPS_Warn_Disp_Rq 0;
BA_ "GenSigTimeoutTime_DTCM" SG_ 1056 EPS_Warn_Disp_Rq 0;
BA_ "GenSigTimeoutTime_DMSM" SG_ 1056 EPS_Warn_Disp_Rq 0;
BA_ "GenSigTimeoutTime_BCM" SG_ 1056 EPS_Warn_Disp_Rq 0;
BA_ "GenSigTimeoutTime_AGSM" SG_ 1056 EPS_Warn_Disp_Rq 0;
BA_ "GenSigTimeoutTime_ADCAM" SG_ 1056 EPS_Warn_Disp_Rq 0;
BA_ "GenSigTimeoutTime_SGW" SG_ 1056 MAC_EPS2 0;
BA_ "GenSigTimeoutTime_RFHM" SG_ 1056 MAC_EPS2 0;
BA_ "GenSigTimeoutTime_IPC" SG_ 1056 MAC_EPS2 0;
BA_ "GenSigTimeoutTime_GNMM" SG_ 1056 MAC_EPS2 0;
BA_ "GenSigTimeoutTime_EVCU2" SG_ 1056 MAC_EPS2 0;
BA_ "GenSigTimeoutTime_ESL" SG_ 1056 MAC_EPS2 0;
BA_ "GenSigTimeoutTime_ECM" SG_ 1056 MAC_EPS2 0;
BA_ "GenSigTimeoutTime_DTCM" SG_ 1056 MAC_EPS2 0;
BA_ "GenSigTimeoutTime_DMSM" SG_ 1056 MAC_EPS2 0;
BA_ "GenSigTimeoutTime_BCM" SG_ 1056 MAC_EPS2 0;
BA_ "GenSigTimeoutTime_AGSM" SG_ 1056 MAC_EPS2 0;
BA_ "GenSigTimeoutTime_ADCAM" SG_ 1056 MAC_EPS2 0;
BA_ "GenSigTimeoutTime_SGW" SG_ 1056 Cntr_EPS2 0;
BA_ "GenSigTimeoutTime_RFHM" SG_ 1056 Cntr_EPS2 0;
BA_ "GenSigTimeoutTime_IPC" SG_ 1056 Cntr_EPS2 0;
BA_ "GenSigTimeoutTime_GNMM" SG_ 1056 Cntr_EPS2 0;
BA_ "GenSigTimeoutTime_EVCU2" SG_ 1056 Cntr_EPS2 0;
BA_ "GenSigTimeoutTime_ESL" SG_ 1056 Cntr_EPS2 0;
BA_ "GenSigTimeoutTime_ECM" SG_ 1056 Cntr_EPS2 0;
BA_ "GenSigTimeoutTime_DTCM" SG_ 1056 Cntr_EPS2 0;
BA_ "GenSigTimeoutTime_DMSM" SG_ 1056 Cntr_EPS2 0;
BA_ "GenSigTimeoutTime_BCM" SG_ 1056 Cntr_EPS2 0;
BA_ "GenSigTimeoutTime_AGSM" SG_ 1056 Cntr_EPS2 0;
BA_ "GenSigTimeoutTime_ADCAM" SG_ 1056 Cntr_EPS2 0;
BA_ "GenSigTimeoutTime_SGW" SG_ 264 MAC_EPS1 0;
BA_ "GenSigTimeoutTime_RFHM" SG_ 264 MAC_EPS1 0;
BA_ "GenSigTimeoutTime_IPC" SG_ 264 MAC_EPS1 0;
BA_ "GenSigTimeoutTime_GNMM" SG_ 264 MAC_EPS1 0;
BA_ "GenSigTimeoutTime_EVCU2" SG_ 264 MAC_EPS1 0;
BA_ "GenSigTimeoutTime_ESL" SG_ 264 MAC_EPS1 0;
BA_ "GenSigTimeoutTime_ECM" SG_ 264 MAC_EPS1 0;
BA_ "GenSigTimeoutTime_DTCM" SG_ 264 MAC_EPS1 0;
BA_ "GenSigTimeoutTime_DMSM" SG_ 264 MAC_EPS1 0;
BA_ "GenSigTimeoutTime_BCM" SG_ 264 MAC_EPS1 0;
BA_ "GenSigTimeoutTime_AGSM" SG_ 264 MAC_EPS1 0;
BA_ "GenSigTimeoutTime_ADCAM" SG_ 264 MAC_EPS1 0;
BA_ "GenSigTimeoutTime_SGW" SG_ 264 Cntr_EPS1 0;
BA_ "GenSigTimeoutTime_RFHM" SG_ 264 Cntr_EPS1 0;
BA_ "GenSigTimeoutTime_IPC" SG_ 264 Cntr_EPS1 0;
BA_ "GenSigTimeoutTime_GNMM" SG_ 264 Cntr_EPS1 0;
BA_ "GenSigTimeoutTime_EVCU2" SG_ 264 Cntr_EPS1 0;
BA_ "GenSigTimeoutTime_ESL" SG_ 264 Cntr_EPS1 0;
BA_ "GenSigTimeoutTime_ECM" SG_ 264 Cntr_EPS1 0;
BA_ "GenSigTimeoutTime_DTCM" SG_ 264 Cntr_EPS1 0;
BA_ "GenSigTimeoutTime_DMSM" SG_ 264 Cntr_EPS1 0;
BA_ "GenSigTimeoutTime_BCM" SG_ 264 Cntr_EPS1 0;
BA_ "GenSigTimeoutTime_AGSM" SG_ 264 Cntr_EPS1 0;
BA_ "GenSigTimeoutTime_ADCAM" SG_ 264 Cntr_EPS1 0;
BA_ "GenSigTimeoutTime_SGW" SG_ 1055 RefuelIndication 0;
BA_ "GenSigTimeoutTime_RFHM" SG_ 1055 RefuelIndication 0;
BA_ "GenSigTimeoutTime_MPAD" SG_ 1055 RefuelIndication 0;
BA_ "GenSigTimeoutTime_GNMM" SG_ 1055 RefuelIndication 0;
BA_ "GenSigTimeoutTime_EVCU2" SG_ 1055 RefuelIndication 0;
BA_ "GenSigTimeoutTime_ESL" SG_ 1055 RefuelIndication 0;
BA_ "GenSigTimeoutTime_ECM" SG_ 1055 RefuelIndication 0;
BA_ "GenSigTimeoutTime_DTCM" SG_ 1055 RefuelIndication 0;
BA_ "GenSigTimeoutTime_DMSM" SG_ 1055 RefuelIndication 0;
BA_ "GenSigTimeoutTime_BSM" SG_ 1055 RefuelIndication 0;
BA_ "GenSigTimeoutTime_BCM" SG_ 1055 RefuelIndication 0;
BA_ "GenSigTimeoutTime_AGSM" SG_ 1055 RefuelIndication 0;
BA_ "GenSigTimeoutTime_ADCAM" SG_ 1055 RefuelIndication 0;
BA_ "GenSigTimeoutTime_SGW" SG_ 1448 MntncSts 0;
BA_ "GenSigTimeoutTime_RFHM" SG_ 1448 MntncSts 0;
BA_ "GenSigTimeoutTime_MPAD" SG_ 1448 MntncSts 0;
BA_ "GenSigTimeoutTime_GNMM" SG_ 1448 MntncSts 0;
BA_ "GenSigTimeoutTime_EVCU2" SG_ 1448 MntncSts 0;
BA_ "GenSigTimeoutTime_ESL" SG_ 1448 MntncSts 0;
BA_ "GenSigTimeoutTime_ECM" SG_ 1448 MntncSts 0;
BA_ "GenSigTimeoutTime_DTCM" SG_ 1448 MntncSts 0;
BA_ "GenSigTimeoutTime_DMSM" SG_ 1448 MntncSts 0;
BA_ "GenSigTimeoutTime_BSM" SG_ 1448 MntncSts 0;
BA_ "GenSigTimeoutTime_BCM" SG_ 1448 MntncSts 0;
BA_ "GenSigTimeoutTime_AGSM" SG_ 1448 MntncSts 0;
BA_ "GenSigTimeoutTime_ADCAM" SG_ 1448 MntncSts 0;
BA_ "GenSigTimeoutTime_SGW" SG_ 259 LwsAngleOffset_BSM 0;
BA_ "GenSigTimeoutTime_RFHM" SG_ 259 LwsAngleOffset_BSM 0;
BA_ "GenSigTimeoutTime_MPAD" SG_ 259 LwsAngleOffset_BSM 0;
BA_ "GenSigTimeoutTime_IPC" SG_ 259 LwsAngleOffset_BSM 0;
BA_ "GenSigTimeoutTime_EVCU2" SG_ 259 LwsAngleOffset_BSM 0;
BA_ "GenSigTimeoutTime_ESL" SG_ 259 LwsAngleOffset_BSM 0;
BA_ "GenSigTimeoutTime_ECM" SG_ 259 LwsAngleOffset_BSM 0;
BA_ "GenSigTimeoutTime_DTCM" SG_ 259 LwsAngleOffset_BSM 0;
BA_ "GenSigTimeoutTime_DMSM" SG_ 259 LwsAngleOffset_BSM 0;
BA_ "GenSigTimeoutTime_BSM" SG_ 259 LwsAngleOffset_BSM 0;
BA_ "GenSigTimeoutTime_BCM" SG_ 259 LwsAngleOffset_BSM 0;
BA_ "GenSigTimeoutTime_AGSM" SG_ 259 LwsAngleOffset_BSM 0;
BA_ "GenSigTimeoutTime_ADCAM" SG_ 259 LwsAngleOffset_BSM 0;
BA_ "GenSigStartValue" SG_ 259 LwsAngleOffset_BSM 1023;
BA_ "GenSigTimeoutTime_SGW" SG_ 259 LongAccelerationOffset_BSM 0;
BA_ "GenSigTimeoutTime_RFHM" SG_ 259 LongAccelerationOffset_BSM 0;
BA_ "GenSigTimeoutTime_MPAD" SG_ 259 LongAccelerationOffset_BSM 0;
BA_ "GenSigTimeoutTime_IPC" SG_ 259 LongAccelerationOffset_BSM 0;
BA_ "GenSigTimeoutTime_GNMM" SG_ 259 LongAccelerationOffset_BSM 0;
BA_ "GenSigTimeoutTime_EVCU2" SG_ 259 LongAccelerationOffset_BSM 0;
BA_ "GenSigTimeoutTime_ESL" SG_ 259 LongAccelerationOffset_BSM 0;
BA_ "GenSigTimeoutTime_ECM" SG_ 259 LongAccelerationOffset_BSM 0;
BA_ "GenSigTimeoutTime_DTCM" SG_ 259 LongAccelerationOffset_BSM 0;
BA_ "GenSigTimeoutTime_DMSM" SG_ 259 LongAccelerationOffset_BSM 0;
BA_ "GenSigTimeoutTime_BSM" SG_ 259 LongAccelerationOffset_BSM 0;
BA_ "GenSigTimeoutTime_BCM" SG_ 259 LongAccelerationOffset_BSM 0;
BA_ "GenSigTimeoutTime_AGSM" SG_ 259 LongAccelerationOffset_BSM 0;
BA_ "GenSigTimeoutTime_ADCAM" SG_ 259 LongAccelerationOffset_BSM 0;
BA_ "GenSigStartValue" SG_ 259 LongAccelerationOffset_BSM 255;
BA_ "GenSigTimeoutTime_SGW" SG_ 259 LatAccelerationOffset_BSM 0;
BA_ "GenSigTimeoutTime_RFHM" SG_ 259 LatAccelerationOffset_BSM 0;
BA_ "GenSigTimeoutTime_MPAD" SG_ 259 LatAccelerationOffset_BSM 0;
BA_ "GenSigTimeoutTime_IPC" SG_ 259 LatAccelerationOffset_BSM 0;
BA_ "GenSigTimeoutTime_GNMM" SG_ 259 LatAccelerationOffset_BSM 0;
BA_ "GenSigTimeoutTime_EVCU2" SG_ 259 LatAccelerationOffset_BSM 0;
BA_ "GenSigTimeoutTime_ESL" SG_ 259 LatAccelerationOffset_BSM 0;
BA_ "GenSigTimeoutTime_ECM" SG_ 259 LatAccelerationOffset_BSM 0;
BA_ "GenSigTimeoutTime_DTCM" SG_ 259 LatAccelerationOffset_BSM 0;
BA_ "GenSigTimeoutTime_DMSM" SG_ 259 LatAccelerationOffset_BSM 0;
BA_ "GenSigTimeoutTime_BSM" SG_ 259 LatAccelerationOffset_BSM 0;
BA_ "GenSigTimeoutTime_BCM" SG_ 259 LatAccelerationOffset_BSM 0;
BA_ "GenSigTimeoutTime_AGSM" SG_ 259 LatAccelerationOffset_BSM 0;
BA_ "GenSigTimeoutTime_ADCAM" SG_ 259 LatAccelerationOffset_BSM 0;
BA_ "GenSigStartValue" SG_ 259 LatAccelerationOffset_BSM 255;
BA_ "GenSigTimeoutTime_SGW" SG_ 1054 HighPressureFuelSystemFailure 0;
BA_ "GenSigTimeoutTime_RFHM" SG_ 1054 HighPressureFuelSystemFailure 0;
BA_ "GenSigTimeoutTime_MPAD" SG_ 1054 HighPressureFuelSystemFailure 0;
BA_ "GenSigTimeoutTime_GNMM" SG_ 1054 HighPressureFuelSystemFailure 0;
BA_ "GenSigTimeoutTime_EVCU2" SG_ 1054 HighPressureFuelSystemFailure 0;
BA_ "GenSigTimeoutTime_ESL" SG_ 1054 HighPressureFuelSystemFailure 0;
BA_ "GenSigTimeoutTime_ECM" SG_ 1054 HighPressureFuelSystemFailure 0;
BA_ "GenSigTimeoutTime_DTCM" SG_ 1054 HighPressureFuelSystemFailure 0;
BA_ "GenSigTimeoutTime_DMSM" SG_ 1054 HighPressureFuelSystemFailure 0;
BA_ "GenSigTimeoutTime_BSM" SG_ 1054 HighPressureFuelSystemFailure 0;
BA_ "GenSigTimeoutTime_BCM" SG_ 1054 HighPressureFuelSystemFailure 0;
BA_ "GenSigTimeoutTime_AGSM" SG_ 1054 HighPressureFuelSystemFailure 0;
BA_ "GenSigTimeoutTime_ADCAM" SG_ 1054 HighPressureFuelSystemFailure 0;
BA_ "GenSigTimeoutTime_RFHM" SG_ 751 MessageCounter_ENGINE6 0;
BA_ "GenSigTimeoutTime_MPAD" SG_ 751 MessageCounter_ENGINE6 0;
BA_ "GenSigTimeoutTime_IPC" SG_ 751 MessageCounter_ENGINE6 0;
BA_ "GenSigTimeoutTime_GNMM" SG_ 751 MessageCounter_ENGINE6 0;
BA_ "GenSigTimeoutTime_EVCU2" SG_ 751 MessageCounter_ENGINE6 0;
BA_ "GenSigTimeoutTime_ESL" SG_ 751 MessageCounter_ENGINE6 0;
BA_ "GenSigTimeoutTime_ECM" SG_ 751 MessageCounter_ENGINE6 0;
BA_ "GenSigTimeoutTime_DTCM" SG_ 751 MessageCounter_ENGINE6 0;
BA_ "GenSigTimeoutTime_DMSM" SG_ 751 MessageCounter_ENGINE6 0;
BA_ "GenSigTimeoutTime_BSM" SG_ 751 MessageCounter_ENGINE6 0;
BA_ "GenSigTimeoutTime_BCM" SG_ 751 MessageCounter_ENGINE6 0;
BA_ "GenSigTimeoutTime_AGSM" SG_ 751 MessageCounter_ENGINE6 0;
BA_ "GenSigTimeoutTime_ADCAM" SG_ 751 MessageCounter_ENGINE6 0;
BA_ "GenSigTimeoutTime_SGW" SG_ 751 LeakCheckTimerValue 0;
BA_ "GenSigTimeoutTime_RFHM" SG_ 751 LeakCheckTimerValue 0;
BA_ "GenSigTimeoutTime_MPAD" SG_ 751 LeakCheckTimerValue 0;
BA_ "GenSigTimeoutTime_IPC" SG_ 751 LeakCheckTimerValue 0;
BA_ "GenSigTimeoutTime_GNMM" SG_ 751 LeakCheckTimerValue 0;
BA_ "GenSigTimeoutTime_EVCU2" SG_ 751 LeakCheckTimerValue 0;
BA_ "GenSigTimeoutTime_ESL" SG_ 751 LeakCheckTimerValue 0;
BA_ "GenSigTimeoutTime_ECM" SG_ 751 LeakCheckTimerValue 0;
BA_ "GenSigTimeoutTime_DTCM" SG_ 751 LeakCheckTimerValue 0;
BA_ "GenSigTimeoutTime_DMSM" SG_ 751 LeakCheckTimerValue 0;
BA_ "GenSigTimeoutTime_BSM" SG_ 751 LeakCheckTimerValue 0;
BA_ "GenSigTimeoutTime_AGSM" SG_ 751 LeakCheckTimerValue 0;
BA_ "GenSigTimeoutTime_ADCAM" SG_ 751 LeakCheckTimerValue 0;
BA_ "GenSigTimeoutTime_SGW" SG_ 751 LeakTestRequest 0;
BA_ "GenSigTimeoutTime_RFHM" SG_ 751 LeakTestRequest 0;
BA_ "GenSigTimeoutTime_MPAD" SG_ 751 LeakTestRequest 0;
BA_ "GenSigTimeoutTime_IPC" SG_ 751 LeakTestRequest 0;
BA_ "GenSigTimeoutTime_GNMM" SG_ 751 LeakTestRequest 0;
BA_ "GenSigTimeoutTime_EVCU2" SG_ 751 LeakTestRequest 0;
BA_ "GenSigTimeoutTime_ESL" SG_ 751 LeakTestRequest 0;
BA_ "GenSigTimeoutTime_ECM" SG_ 751 LeakTestRequest 0;
BA_ "GenSigTimeoutTime_DTCM" SG_ 751 LeakTestRequest 0;
BA_ "GenSigTimeoutTime_DMSM" SG_ 751 LeakTestRequest 0;
BA_ "GenSigTimeoutTime_BSM" SG_ 751 LeakTestRequest 0;
BA_ "GenSigTimeoutTime_AGSM" SG_ 751 LeakTestRequest 0;
BA_ "GenSigTimeoutTime_ADCAM" SG_ 751 LeakTestRequest 0;
BA_ "GenSigTimeoutTime_SGW" SG_ 751 LeakTestSts 0;
BA_ "GenSigTimeoutTime_RFHM" SG_ 751 LeakTestSts 0;
BA_ "GenSigTimeoutTime_MPAD" SG_ 751 LeakTestSts 0;
BA_ "GenSigTimeoutTime_IPC" SG_ 751 LeakTestSts 0;
BA_ "GenSigTimeoutTime_GNMM" SG_ 751 LeakTestSts 0;
BA_ "GenSigTimeoutTime_EVCU2" SG_ 751 LeakTestSts 0;
BA_ "GenSigTimeoutTime_ESL" SG_ 751 LeakTestSts 0;
BA_ "GenSigTimeoutTime_ECM" SG_ 751 LeakTestSts 0;
BA_ "GenSigTimeoutTime_DTCM" SG_ 751 LeakTestSts 0;
BA_ "GenSigTimeoutTime_DMSM" SG_ 751 LeakTestSts 0;
BA_ "GenSigTimeoutTime_BSM" SG_ 751 LeakTestSts 0;
BA_ "GenSigTimeoutTime_AGSM" SG_ 751 LeakTestSts 0;
BA_ "GenSigTimeoutTime_ADCAM" SG_ 751 LeakTestSts 0;
BA_ "GenSigTimeoutTime_SGW" SG_ 518 CRC_ENGINE5 0;
BA_ "GenSigTimeoutTime_RFHM" SG_ 518 CRC_ENGINE5 0;
BA_ "GenSigTimeoutTime_MPAD" SG_ 518 CRC_ENGINE5 0;
BA_ "GenSigTimeoutTime_IPC" SG_ 518 CRC_ENGINE5 0;
BA_ "GenSigTimeoutTime_GNMM" SG_ 518 CRC_ENGINE5 0;
BA_ "GenSigTimeoutTime_ESL" SG_ 518 CRC_ENGINE5 0;
BA_ "GenSigTimeoutTime_ECM" SG_ 518 CRC_ENGINE5 0;
BA_ "GenSigTimeoutTime_DTCM" SG_ 518 CRC_ENGINE5 0;
BA_ "GenSigTimeoutTime_DMSM" SG_ 518 CRC_ENGINE5 0;
BA_ "GenSigTimeoutTime_BSM" SG_ 518 CRC_ENGINE5 0;
BA_ "GenSigTimeoutTime_BCM" SG_ 518 CRC_ENGINE5 0;
BA_ "GenSigTimeoutTime_AGSM" SG_ 518 CRC_ENGINE5 0;
BA_ "GenSigTimeoutTime_ADCAM" SG_ 518 CRC_ENGINE5 0;
BA_ "GenSigTimeoutTime_SGW" SG_ 518 ECM_CODE_CLR_W 0;
BA_ "GenSigTimeoutTime_RFHM" SG_ 518 ECM_CODE_CLR_W 0;
BA_ "GenSigTimeoutTime_MPAD" SG_ 518 ECM_CODE_CLR_W 0;
BA_ "GenSigTimeoutTime_IPC" SG_ 518 ECM_CODE_CLR_W 0;
BA_ "GenSigTimeoutTime_GNMM" SG_ 518 ECM_CODE_CLR_W 0;
BA_ "GenSigTimeoutTime_ESL" SG_ 518 ECM_CODE_CLR_W 0;
BA_ "GenSigTimeoutTime_ECM" SG_ 518 ECM_CODE_CLR_W 0;
BA_ "GenSigTimeoutTime_DTCM" SG_ 518 ECM_CODE_CLR_W 0;
BA_ "GenSigTimeoutTime_DMSM" SG_ 518 ECM_CODE_CLR_W 0;
BA_ "GenSigTimeoutTime_BCM" SG_ 518 ECM_CODE_CLR_W 0;
BA_ "GenSigTimeoutTime_AGSM" SG_ 518 ECM_CODE_CLR_W 0;
BA_ "GenSigTimeoutTime_ADCAM" SG_ 518 ECM_CODE_CLR_W 0;
BA_ "GenSigTimeoutTime_SGW" SG_ 518 ECM_READINESS_RESET_W 0;
BA_ "GenSigTimeoutTime_RFHM" SG_ 518 ECM_READINESS_RESET_W 0;
BA_ "GenSigTimeoutTime_MPAD" SG_ 518 ECM_READINESS_RESET_W 0;
BA_ "GenSigTimeoutTime_IPC" SG_ 518 ECM_READINESS_RESET_W 0;
BA_ "GenSigTimeoutTime_GNMM" SG_ 518 ECM_READINESS_RESET_W 0;
BA_ "GenSigTimeoutTime_ESL" SG_ 518 ECM_READINESS_RESET_W 0;
BA_ "GenSigTimeoutTime_ECM" SG_ 518 ECM_READINESS_RESET_W 0;
BA_ "GenSigTimeoutTime_DTCM" SG_ 518 ECM_READINESS_RESET_W 0;
BA_ "GenSigTimeoutTime_DMSM" SG_ 518 ECM_READINESS_RESET_W 0;
BA_ "GenSigTimeoutTime_BCM" SG_ 518 ECM_READINESS_RESET_W 0;
BA_ "GenSigTimeoutTime_AGSM" SG_ 518 ECM_READINESS_RESET_W 0;
BA_ "GenSigTimeoutTime_ADCAM" SG_ 518 ECM_READINESS_RESET_W 0;
BA_ "GenSigTimeoutTime_SGW" SG_ 518 MessageCounter_ENGINE5 0;
BA_ "GenSigTimeoutTime_RFHM" SG_ 518 MessageCounter_ENGINE5 0;
BA_ "GenSigTimeoutTime_MPAD" SG_ 518 MessageCounter_ENGINE5 0;
BA_ "GenSigTimeoutTime_IPC" SG_ 518 MessageCounter_ENGINE5 0;
BA_ "GenSigTimeoutTime_GNMM" SG_ 518 MessageCounter_ENGINE5 0;
BA_ "GenSigTimeoutTime_ESL" SG_ 518 MessageCounter_ENGINE5 0;
BA_ "GenSigTimeoutTime_ECM" SG_ 518 MessageCounter_ENGINE5 0;
BA_ "GenSigTimeoutTime_DTCM" SG_ 518 MessageCounter_ENGINE5 0;
BA_ "GenSigTimeoutTime_DMSM" SG_ 518 MessageCounter_ENGINE5 0;
BA_ "GenSigTimeoutTime_BSM" SG_ 518 MessageCounter_ENGINE5 0;
BA_ "GenSigTimeoutTime_BCM" SG_ 518 MessageCounter_ENGINE5 0;
BA_ "GenSigTimeoutTime_AGSM" SG_ 518 MessageCounter_ENGINE5 0;
BA_ "GenSigTimeoutTime_ADCAM" SG_ 518 MessageCounter_ENGINE5 0;
BA_ "GenSigTimeoutTime_RFHM" SG_ 518 PdlPosActual 0;
BA_ "GenSigTimeoutTime_MPAD" SG_ 518 PdlPosActual 0;
BA_ "GenSigTimeoutTime_IPC" SG_ 518 PdlPosActual 0;
BA_ "GenSigTimeoutTime_GNMM" SG_ 518 PdlPosActual 0;
BA_ "GenSigTimeoutTime_EVCU2" SG_ 518 PdlPosActual 0;
BA_ "GenSigTimeoutTime_ESL" SG_ 518 PdlPosActual 0;
BA_ "GenSigTimeoutTime_ECM" SG_ 518 PdlPosActual 0;
BA_ "GenSigTimeoutTime_DTCM" SG_ 518 PdlPosActual 0;
BA_ "GenSigTimeoutTime_DMSM" SG_ 518 PdlPosActual 0;
BA_ "GenSigTimeoutTime_BSM" SG_ 518 PdlPosActual 0;
BA_ "GenSigTimeoutTime_AGSM" SG_ 518 PdlPosActual 0;
BA_ "GenSigTimeoutTime_ADCAM" SG_ 518 PdlPosActual 0;
BA_ "GenSigStartValue" SG_ 518 PdlPosActual 1;
BA_ "GenSigTimeoutTime_SGW" SG_ 518 RPMOverRev_W 0;
BA_ "GenSigTimeoutTime_RFHM" SG_ 518 RPMOverRev_W 0;
BA_ "GenSigTimeoutTime_MPAD" SG_ 518 RPMOverRev_W 0;
BA_ "GenSigTimeoutTime_IPC" SG_ 518 RPMOverRev_W 0;
BA_ "GenSigTimeoutTime_GNMM" SG_ 518 RPMOverRev_W 0;
BA_ "GenSigTimeoutTime_EVCU2" SG_ 518 RPMOverRev_W 0;
BA_ "GenSigTimeoutTime_ESL" SG_ 518 RPMOverRev_W 0;
BA_ "GenSigTimeoutTime_ECM" SG_ 518 RPMOverRev_W 0;
BA_ "GenSigTimeoutTime_DTCM" SG_ 518 RPMOverRev_W 0;
BA_ "GenSigTimeoutTime_DMSM" SG_ 518 RPMOverRev_W 0;
BA_ "GenSigTimeoutTime_BSM" SG_ 518 RPMOverRev_W 0;
BA_ "GenSigTimeoutTime_BCM" SG_ 518 RPMOverRev_W 0;
BA_ "GenSigTimeoutTime_AGSM" SG_ 518 RPMOverRev_W 0;
BA_ "GenSigTimeoutTime_ADCAM" SG_ 518 RPMOverRev_W 0;
BA_ "GenSigTimeoutTime_RFHM" SG_ 751 CRC_ENGINE6 0;
BA_ "GenSigTimeoutTime_MPAD" SG_ 751 CRC_ENGINE6 0;
BA_ "GenSigTimeoutTime_IPC" SG_ 751 CRC_ENGINE6 0;
BA_ "GenSigTimeoutTime_GNMM" SG_ 751 CRC_ENGINE6 0;
BA_ "GenSigTimeoutTime_EVCU2" SG_ 751 CRC_ENGINE6 0;
BA_ "GenSigTimeoutTime_ESL" SG_ 751 CRC_ENGINE6 0;
BA_ "GenSigTimeoutTime_ECM" SG_ 751 CRC_ENGINE6 0;
BA_ "GenSigTimeoutTime_DTCM" SG_ 751 CRC_ENGINE6 0;
BA_ "GenSigTimeoutTime_DMSM" SG_ 751 CRC_ENGINE6 0;
BA_ "GenSigTimeoutTime_BSM" SG_ 751 CRC_ENGINE6 0;
BA_ "GenSigTimeoutTime_BCM" SG_ 751 CRC_ENGINE6 0;
BA_ "GenSigTimeoutTime_AGSM" SG_ 751 CRC_ENGINE6 0;
BA_ "GenSigTimeoutTime_ADCAM" SG_ 751 CRC_ENGINE6 0;
BA_ "GenSigTimeoutTime_SGW" SG_ 1448 ECM_WARN 0;
BA_ "GenSigTimeoutTime_RFHM" SG_ 1448 ECM_WARN 0;
BA_ "GenSigTimeoutTime_MPAD" SG_ 1448 ECM_WARN 0;
BA_ "GenSigTimeoutTime_GNMM" SG_ 1448 ECM_WARN 0;
BA_ "GenSigTimeoutTime_EVCU2" SG_ 1448 ECM_WARN 0;
BA_ "GenSigTimeoutTime_SGW" SG_ 1068 AxleLckrEvicDisp 0;
BA_ "GenSigTimeoutTime_RFHM" SG_ 1068 AxleLckrEvicDisp 0;
BA_ "GenSigTimeoutTime_MPAD" SG_ 1068 AxleLckrEvicDisp 0;
BA_ "GenSigTimeoutTime_GNMM" SG_ 1068 AxleLckrEvicDisp 0;
BA_ "GenSigTimeoutTime_EVCU2" SG_ 1068 AxleLckrEvicDisp 0;
BA_ "GenSigTimeoutTime_ESL" SG_ 1068 AxleLckrEvicDisp 0;
BA_ "GenSigTimeoutTime_ECM" SG_ 1068 AxleLckrEvicDisp 0;
BA_ "GenSigTimeoutTime_DTCM" SG_ 1068 AxleLckrEvicDisp 0;
BA_ "GenSigTimeoutTime_DMSM" SG_ 1068 AxleLckrEvicDisp 0;
BA_ "GenSigTimeoutTime_BSM" SG_ 1068 AxleLckrEvicDisp 0;
BA_ "GenSigTimeoutTime_BCM" SG_ 1068 AxleLckrEvicDisp 0;
BA_ "GenSigTimeoutTime_AGSM" SG_ 1068 AxleLckrEvicDisp 0;
BA_ "GenSigTimeoutTime_ADCAM" SG_ 1068 AxleLckrEvicDisp 0;
BA_ "GenSigSendType" SG_ 1068 AxleLckrEvicDisp 3;
BA_ "GenSigTimeoutTime_SGW" SG_ 1068 AxleLckr_SRV_RQ 0;
BA_ "GenSigTimeoutTime_RFHM" SG_ 1068 AxleLckr_SRV_RQ 0;
BA_ "GenSigTimeoutTime_MPAD" SG_ 1068 AxleLckr_SRV_RQ 0;
BA_ "GenSigTimeoutTime_GNMM" SG_ 1068 AxleLckr_SRV_RQ 0;
BA_ "GenSigTimeoutTime_EVCU2" SG_ 1068 AxleLckr_SRV_RQ 0;
BA_ "GenSigTimeoutTime_ESL" SG_ 1068 AxleLckr_SRV_RQ 0;
BA_ "GenSigTimeoutTime_ECM" SG_ 1068 AxleLckr_SRV_RQ 0;
BA_ "GenSigTimeoutTime_DTCM" SG_ 1068 AxleLckr_SRV_RQ 0;
BA_ "GenSigTimeoutTime_DMSM" SG_ 1068 AxleLckr_SRV_RQ 0;
BA_ "GenSigTimeoutTime_BSM" SG_ 1068 AxleLckr_SRV_RQ 0;
BA_ "GenSigTimeoutTime_BCM" SG_ 1068 AxleLckr_SRV_RQ 0;
BA_ "GenSigTimeoutTime_AGSM" SG_ 1068 AxleLckr_SRV_RQ 0;
BA_ "GenSigTimeoutTime_ADCAM" SG_ 1068 AxleLckr_SRV_RQ 0;
BA_ "GenSigSendType" SG_ 1068 AxleLckr_SRV_RQ 3;
BA_ "GenSigTimeoutTime_RFHM" SG_ 1068 AxleLckr_Stat 0;
BA_ "GenSigTimeoutTime_MPAD" SG_ 1068 AxleLckr_Stat 0;
BA_ "GenSigTimeoutTime_GNMM" SG_ 1068 AxleLckr_Stat 0;
BA_ "GenSigTimeoutTime_EVCU2" SG_ 1068 AxleLckr_Stat 0;
BA_ "GenSigTimeoutTime_ESL" SG_ 1068 AxleLckr_Stat 0;
BA_ "GenSigTimeoutTime_ECM" SG_ 1068 AxleLckr_Stat 0;
BA_ "GenSigTimeoutTime_DTCM" SG_ 1068 AxleLckr_Stat 0;
BA_ "GenSigTimeoutTime_DMSM" SG_ 1068 AxleLckr_Stat 0;
BA_ "GenSigTimeoutTime_BSM" SG_ 1068 AxleLckr_Stat 0;
BA_ "GenSigTimeoutTime_BCM" SG_ 1068 AxleLckr_Stat 0;
BA_ "GenSigTimeoutTime_AGSM" SG_ 1068 AxleLckr_Stat 0;
BA_ "GenSigTimeoutTime_ADCAM" SG_ 1068 AxleLckr_Stat 0;
BA_ "GenSigSendType" SG_ 1068 AxleLckr_Stat 3;
BA_ "GenSigTimeoutTime_ADCAM" SG_ 1068 CRC__DRIVETRAIN3 0;
BA_ "GenSigTimeoutTime_AGSM" SG_ 1068 CRC__DRIVETRAIN3 0;
BA_ "GenSigTimeoutTime_BSM" SG_ 1068 CRC__DRIVETRAIN3 0;
BA_ "GenSigTimeoutTime_DMSM" SG_ 1068 CRC__DRIVETRAIN3 0;
BA_ "GenSigTimeoutTime_DTCM" SG_ 1068 CRC__DRIVETRAIN3 0;
BA_ "GenSigTimeoutTime_ECM" SG_ 1068 CRC__DRIVETRAIN3 0;
BA_ "GenSigTimeoutTime_ESL" SG_ 1068 CRC__DRIVETRAIN3 0;
BA_ "GenSigTimeoutTime_EVCU2" SG_ 1068 CRC__DRIVETRAIN3 0;
BA_ "GenSigTimeoutTime_GNMM" SG_ 1068 CRC__DRIVETRAIN3 0;
BA_ "GenSigTimeoutTime_IPC" SG_ 1068 CRC__DRIVETRAIN3 0;
BA_ "GenSigTimeoutTime_MPAD" SG_ 1068 CRC__DRIVETRAIN3 0;
BA_ "GenSigTimeoutTime_RFHM" SG_ 1068 CRC__DRIVETRAIN3 0;
BA_ "GenSigTimeoutTime_SGW" SG_ 1068 CRC__DRIVETRAIN3 0;
BA_ "GenSigTimeoutTime_ADCAM" SG_ 1068 MessageCounter_DRIVETRAIN3 0;
BA_ "GenSigTimeoutTime_AGSM" SG_ 1068 MessageCounter_DRIVETRAIN3 0;
BA_ "GenSigTimeoutTime_BSM" SG_ 1068 MessageCounter_DRIVETRAIN3 0;
BA_ "GenSigTimeoutTime_DMSM" SG_ 1068 MessageCounter_DRIVETRAIN3 0;
BA_ "GenSigTimeoutTime_DTCM" SG_ 1068 MessageCounter_DRIVETRAIN3 0;
BA_ "GenSigTimeoutTime_ECM" SG_ 1068 MessageCounter_DRIVETRAIN3 0;
BA_ "GenSigTimeoutTime_ESL" SG_ 1068 MessageCounter_DRIVETRAIN3 0;
BA_ "GenSigTimeoutTime_EVCU2" SG_ 1068 MessageCounter_DRIVETRAIN3 0;
BA_ "GenSigTimeoutTime_GNMM" SG_ 1068 MessageCounter_DRIVETRAIN3 0;
BA_ "GenSigTimeoutTime_IPC" SG_ 1068 MessageCounter_DRIVETRAIN3 0;
BA_ "GenSigTimeoutTime_MPAD" SG_ 1068 MessageCounter_DRIVETRAIN3 0;
BA_ "GenSigTimeoutTime_RFHM" SG_ 1068 MessageCounter_DRIVETRAIN3 0;
BA_ "GenSigTimeoutTime_SGW" SG_ 1068 MessageCounter_DRIVETRAIN3 0;
BA_ "GenSigTimeoutTime_SGW" SG_ 1447 Ft_RrCouplingTrq_percentage 0;
BA_ "GenSigTimeoutTime_RFHM" SG_ 1447 Ft_RrCouplingTrq_percentage 0;
BA_ "GenSigTimeoutTime_MPAD" SG_ 1447 Ft_RrCouplingTrq_percentage 0;
BA_ "GenSigTimeoutTime_IPC" SG_ 1447 Ft_RrCouplingTrq_percentage 0;
BA_ "GenSigTimeoutTime_GNMM" SG_ 1447 Ft_RrCouplingTrq_percentage 0;
BA_ "GenSigTimeoutTime_EVCU2" SG_ 1447 Ft_RrCouplingTrq_percentage 0;
BA_ "GenSigTimeoutTime_ESL" SG_ 1447 Ft_RrCouplingTrq_percentage 0;
BA_ "GenSigTimeoutTime_ECM" SG_ 1447 Ft_RrCouplingTrq_percentage 0;
BA_ "GenSigTimeoutTime_DTCM" SG_ 1447 Ft_RrCouplingTrq_percentage 0;
BA_ "GenSigTimeoutTime_DMSM" SG_ 1447 Ft_RrCouplingTrq_percentage 0;
BA_ "GenSigTimeoutTime_BSM" SG_ 1447 Ft_RrCouplingTrq_percentage 0;
BA_ "GenSigTimeoutTime_BCM" SG_ 1447 Ft_RrCouplingTrq_percentage 0;
BA_ "GenSigTimeoutTime_AGSM" SG_ 1447 Ft_RrCouplingTrq_percentage 0;
BA_ "GenSigTimeoutTime_ADCAM" SG_ 1447 Ft_RrCouplingTrq_percentage 0;
BA_ "GenSigSendType" SG_ 1447 Ft_RrCouplingTrq_percentage 3;
BA_ "GenSigTimeoutTime_SGW" SG_ 517 TCASE_TargetRangeState 0;
BA_ "GenSigTimeoutTime_RFHM" SG_ 517 TCASE_TargetRangeState 0;
BA_ "GenSigTimeoutTime_MPAD" SG_ 517 TCASE_TargetRangeState 0;
BA_ "GenSigTimeoutTime_IPC" SG_ 517 TCASE_TargetRangeState 0;
BA_ "GenSigTimeoutTime_GNMM" SG_ 517 TCASE_TargetRangeState 0;
BA_ "GenSigTimeoutTime_ESL" SG_ 517 TCASE_TargetRangeState 0;
BA_ "GenSigTimeoutTime_ECM" SG_ 517 TCASE_TargetRangeState 0;
BA_ "GenSigTimeoutTime_DTCM" SG_ 517 TCASE_TargetRangeState 0;
BA_ "GenSigTimeoutTime_DMSM" SG_ 517 TCASE_TargetRangeState 0;
BA_ "GenSigTimeoutTime_BSM" SG_ 517 TCASE_TargetRangeState 0;
BA_ "GenSigTimeoutTime_BCM" SG_ 517 TCASE_TargetRangeState 0;
BA_ "GenSigTimeoutTime_AGSM" SG_ 517 TCASE_TargetRangeState 0;
BA_ "GenSigTimeoutTime_ADCAM" SG_ 517 TCASE_TargetRangeState 0;
BA_ "GenSigTimeoutTime_SGW" SG_ 517 SpeedSyncRq 0;
BA_ "GenSigTimeoutTime_RFHM" SG_ 517 SpeedSyncRq 0;
BA_ "GenSigTimeoutTime_MPAD" SG_ 517 SpeedSyncRq 0;
BA_ "GenSigTimeoutTime_IPC" SG_ 517 SpeedSyncRq 0;
BA_ "GenSigTimeoutTime_GNMM" SG_ 517 SpeedSyncRq 0;
BA_ "GenSigTimeoutTime_ESL" SG_ 517 SpeedSyncRq 0;
BA_ "GenSigTimeoutTime_ECM" SG_ 517 SpeedSyncRq 0;
BA_ "GenSigTimeoutTime_DTCM" SG_ 517 SpeedSyncRq 0;
BA_ "GenSigTimeoutTime_DMSM" SG_ 517 SpeedSyncRq 0;
BA_ "GenSigTimeoutTime_BSM" SG_ 517 SpeedSyncRq 0;
BA_ "GenSigTimeoutTime_BCM" SG_ 517 SpeedSyncRq 0;
BA_ "GenSigTimeoutTime_AGSM" SG_ 517 SpeedSyncRq 0;
BA_ "GenSigTimeoutTime_ADCAM" SG_ 517 SpeedSyncRq 0;
BA_ "GenSigTimeoutTime_SGW" SG_ 517 RDU_State 0;
BA_ "GenSigTimeoutTime_RFHM" SG_ 517 RDU_State 0;
BA_ "GenSigTimeoutTime_MPAD" SG_ 517 RDU_State 0;
BA_ "GenSigTimeoutTime_IPC" SG_ 517 RDU_State 0;
BA_ "GenSigTimeoutTime_GNMM" SG_ 517 RDU_State 0;
BA_ "GenSigTimeoutTime_ESL" SG_ 517 RDU_State 0;
BA_ "GenSigTimeoutTime_ECM" SG_ 517 RDU_State 0;
BA_ "GenSigTimeoutTime_DTCM" SG_ 517 RDU_State 0;
BA_ "GenSigTimeoutTime_DMSM" SG_ 517 RDU_State 0;
BA_ "GenSigTimeoutTime_BSM" SG_ 517 RDU_State 0;
BA_ "GenSigTimeoutTime_BCM" SG_ 517 RDU_State 0;
BA_ "GenSigTimeoutTime_AGSM" SG_ 517 RDU_State 0;
BA_ "GenSigTimeoutTime_ADCAM" SG_ 517 RDU_State 0;
BA_ "GenSigTimeoutTime_SGW" SG_ 517 PTU_State 0;
BA_ "GenSigTimeoutTime_RFHM" SG_ 517 PTU_State 0;
BA_ "GenSigTimeoutTime_MPAD" SG_ 517 PTU_State 0;
BA_ "GenSigTimeoutTime_IPC" SG_ 517 PTU_State 0;
BA_ "GenSigTimeoutTime_GNMM" SG_ 517 PTU_State 0;
BA_ "GenSigTimeoutTime_ESL" SG_ 517 PTU_State 0;
BA_ "GenSigTimeoutTime_ECM" SG_ 517 PTU_State 0;
BA_ "GenSigTimeoutTime_DTCM" SG_ 517 PTU_State 0;
BA_ "GenSigTimeoutTime_DMSM" SG_ 517 PTU_State 0;
BA_ "GenSigTimeoutTime_BSM" SG_ 517 PTU_State 0;
BA_ "GenSigTimeoutTime_BCM" SG_ 517 PTU_State 0;
BA_ "GenSigTimeoutTime_AGSM" SG_ 517 PTU_State 0;
BA_ "GenSigTimeoutTime_ADCAM" SG_ 517 PTU_State 0;
BA_ "GenSigTimeoutTime_ADCAM" SG_ 517 CRC_DRIVETRAIN1 0;
BA_ "GenSigTimeoutTime_AGSM" SG_ 517 CRC_DRIVETRAIN1 0;
BA_ "GenSigTimeoutTime_BCM" SG_ 517 CRC_DRIVETRAIN1 0;
BA_ "GenSigTimeoutTime_BSM" SG_ 517 CRC_DRIVETRAIN1 0;
BA_ "GenSigTimeoutTime_DMSM" SG_ 517 CRC_DRIVETRAIN1 0;
BA_ "GenSigTimeoutTime_DTCM" SG_ 517 CRC_DRIVETRAIN1 0;
BA_ "GenSigTimeoutTime_ECM" SG_ 517 CRC_DRIVETRAIN1 0;
BA_ "GenSigTimeoutTime_ESL" SG_ 517 CRC_DRIVETRAIN1 0;
BA_ "GenSigTimeoutTime_GNMM" SG_ 517 CRC_DRIVETRAIN1 0;
BA_ "GenSigTimeoutTime_IPC" SG_ 517 CRC_DRIVETRAIN1 0;
BA_ "GenSigTimeoutTime_MPAD" SG_ 517 CRC_DRIVETRAIN1 0;
BA_ "GenSigTimeoutTime_RFHM" SG_ 517 CRC_DRIVETRAIN1 0;
BA_ "GenSigTimeoutTime_SGW" SG_ 517 CRC_DRIVETRAIN1 0;
BA_ "GenSigTimeoutTime_ADCAM" SG_ 517 MessageCounter_DRIVETRAIN1 0;
BA_ "GenSigTimeoutTime_AGSM" SG_ 517 MessageCounter_DRIVETRAIN1 0;
BA_ "GenSigTimeoutTime_BCM" SG_ 517 MessageCounter_DRIVETRAIN1 0;
BA_ "GenSigTimeoutTime_BSM" SG_ 517 MessageCounter_DRIVETRAIN1 0;
BA_ "GenSigTimeoutTime_DMSM" SG_ 517 MessageCounter_DRIVETRAIN1 0;
BA_ "GenSigTimeoutTime_DTCM" SG_ 517 MessageCounter_DRIVETRAIN1 0;
BA_ "GenSigTimeoutTime_ECM" SG_ 517 MessageCounter_DRIVETRAIN1 0;
BA_ "GenSigTimeoutTime_ESL" SG_ 517 MessageCounter_DRIVETRAIN1 0;
BA_ "GenSigTimeoutTime_GNMM" SG_ 517 MessageCounter_DRIVETRAIN1 0;
BA_ "GenSigTimeoutTime_IPC" SG_ 517 MessageCounter_DRIVETRAIN1 0;
BA_ "GenSigTimeoutTime_MPAD" SG_ 517 MessageCounter_DRIVETRAIN1 0;
BA_ "GenSigTimeoutTime_RFHM" SG_ 517 MessageCounter_DRIVETRAIN1 0;
BA_ "GenSigTimeoutTime_SGW" SG_ 517 MessageCounter_DRIVETRAIN1 0;
BA_ "GenSigTimeoutTime_SGW" SG_ 517 DrvLnTrqRq_Axle 0;
BA_ "GenSigTimeoutTime_RFHM" SG_ 517 DrvLnTrqRq_Axle 0;
BA_ "GenSigTimeoutTime_MPAD" SG_ 517 DrvLnTrqRq_Axle 0;
BA_ "GenSigTimeoutTime_IPC" SG_ 517 DrvLnTrqRq_Axle 0;
BA_ "GenSigTimeoutTime_GNMM" SG_ 517 DrvLnTrqRq_Axle 0;
BA_ "GenSigTimeoutTime_ESL" SG_ 517 DrvLnTrqRq_Axle 0;
BA_ "GenSigTimeoutTime_ECM" SG_ 517 DrvLnTrqRq_Axle 0;
BA_ "GenSigTimeoutTime_DTCM" SG_ 517 DrvLnTrqRq_Axle 0;
BA_ "GenSigTimeoutTime_DMSM" SG_ 517 DrvLnTrqRq_Axle 0;
BA_ "GenSigTimeoutTime_BSM" SG_ 517 DrvLnTrqRq_Axle 0;
BA_ "GenSigTimeoutTime_BCM" SG_ 517 DrvLnTrqRq_Axle 0;
BA_ "GenSigTimeoutTime_AGSM" SG_ 517 DrvLnTrqRq_Axle 0;
BA_ "GenSigTimeoutTime_ADCAM" SG_ 517 DrvLnTrqRq_Axle 0;
BA_ "GenSigTimeoutTime_ESL" SG_ 1448 ECM_WARN 0;
BA_ "GenSigTimeoutTime_ECM" SG_ 1448 ECM_WARN 0;
BA_ "GenSigTimeoutTime_DTCM" SG_ 1448 ECM_WARN 0;
BA_ "GenSigTimeoutTime_DMSM" SG_ 1448 ECM_WARN 0;
BA_ "GenSigTimeoutTime_BSM" SG_ 1448 ECM_WARN 0;
BA_ "GenSigTimeoutTime_BCM" SG_ 1448 ECM_WARN 0;
BA_ "GenSigTimeoutTime_AGSM" SG_ 1448 ECM_WARN 0;
BA_ "GenSigTimeoutTime_ADCAM" SG_ 1448 ECM_WARN 0;
BA_ "GenSigSendType" SG_ 1448 ECM_WARN 3;
BA_ "GenSigTimeoutTime_RFHM" SG_ 751 EngineWaterTemp 0;
BA_ "GenSigTimeoutTime_MPAD" SG_ 751 EngineWaterTemp 0;
BA_ "GenSigTimeoutTime_GNMM" SG_ 751 EngineWaterTemp 0;
BA_ "GenSigTimeoutTime_EVCU2" SG_ 751 EngineWaterTemp 0;
BA_ "GenSigTimeoutTime_ESL" SG_ 751 EngineWaterTemp 0;
BA_ "GenSigTimeoutTime_ECM" SG_ 751 EngineWaterTemp 0;
BA_ "GenSigTimeoutTime_DTCM" SG_ 751 EngineWaterTemp 0;
BA_ "GenSigTimeoutTime_DMSM" SG_ 751 EngineWaterTemp 0;
BA_ "GenSigTimeoutTime_BSM" SG_ 751 EngineWaterTemp 0;
BA_ "GenSigTimeoutTime_AGSM" SG_ 751 EngineWaterTemp 0;
BA_ "GenSigTimeoutTime_ADCAM" SG_ 751 EngineWaterTemp 0;
BA_ "GenSigTimeoutTime_ECM" SG_ 1448 EMSFailSts 0;
BA_ "GenSigTimeoutTime_DTCM" SG_ 1448 EMSFailSts 0;
BA_ "GenSigTimeoutTime_DMSM" SG_ 1448 EMSFailSts 0;
BA_ "GenSigTimeoutTime_BSM" SG_ 1448 EMSFailSts 0;
BA_ "GenSigTimeoutTime_AGSM" SG_ 1448 EMSFailSts 0;
BA_ "GenSigTimeoutTime_ADCAM" SG_ 1448 EMSFailSts 0;
BA_ "GenSigSendType" SG_ 1448 EMSFailSts 3;
BA_ "GenSigStartValue" SG_ 1448 EMSFailSts 2;
BA_ "GenSigTimeoutTime_SGW" SG_ 1068 DTCM_Vehicle_Hold_Rq 0;
BA_ "GenSigTimeoutTime_RFHM" SG_ 1068 DTCM_Vehicle_Hold_Rq 0;
BA_ "GenSigTimeoutTime_MPAD" SG_ 1068 DTCM_Vehicle_Hold_Rq 0;
BA_ "GenSigTimeoutTime_IPC" SG_ 1068 DTCM_Vehicle_Hold_Rq 0;
BA_ "GenSigTimeoutTime_GNMM" SG_ 1068 DTCM_Vehicle_Hold_Rq 0;
BA_ "GenSigTimeoutTime_EVCU2" SG_ 1068 DTCM_Vehicle_Hold_Rq 0;
BA_ "GenSigTimeoutTime_ESL" SG_ 1068 DTCM_Vehicle_Hold_Rq 0;
BA_ "GenSigTimeoutTime_ECM" SG_ 1068 DTCM_Vehicle_Hold_Rq 0;
BA_ "GenSigTimeoutTime_DTCM" SG_ 1068 DTCM_Vehicle_Hold_Rq 0;
BA_ "GenSigTimeoutTime_DMSM" SG_ 1068 DTCM_Vehicle_Hold_Rq 0;
BA_ "GenSigTimeoutTime_BSM" SG_ 1068 DTCM_Vehicle_Hold_Rq 0;
BA_ "GenSigTimeoutTime_RFHM" SG_ 1054 ThrottlePosition 0;
BA_ "GenSigTimeoutTime_MPAD" SG_ 1054 ThrottlePosition 0;
BA_ "GenSigTimeoutTime_IPC" SG_ 1054 ThrottlePosition 0;
BA_ "GenSigTimeoutTime_GNMM" SG_ 1054 ThrottlePosition 0;
BA_ "GenSigTimeoutTime_EVCU2" SG_ 1054 ThrottlePosition 0;
BA_ "GenSigTimeoutTime_ESL" SG_ 1054 ThrottlePosition 0;
BA_ "GenSigTimeoutTime_ECM" SG_ 1054 ThrottlePosition 0;
BA_ "GenSigTimeoutTime_DTCM" SG_ 1054 ThrottlePosition 0;
BA_ "GenSigTimeoutTime_DMSM" SG_ 1054 ThrottlePosition 0;
BA_ "GenSigTimeoutTime_BSM" SG_ 1054 ThrottlePosition 0;
BA_ "GenSigTimeoutTime_AGSM" SG_ 1054 ThrottlePosition 0;
BA_ "GenSigTimeoutTime_ADCAM" SG_ 1054 ThrottlePosition 0;
BA_ "GenSigTimeoutTime_SGW" SG_ 2654817991 ECU_APPL_FD_RFHM 0;
BA_ "GenSigTimeoutTime_RFHM" SG_ 2654817991 ECU_APPL_FD_RFHM 0;
BA_ "GenSigTimeoutTime_MPAD" SG_ 2654817991 ECU_APPL_FD_RFHM 0;
BA_ "GenSigTimeoutTime_IPC" SG_ 2654817991 ECU_APPL_FD_RFHM 0;
BA_ "GenSigTimeoutTime_GNMM" SG_ 2654817991 ECU_APPL_FD_RFHM 0;
BA_ "GenSigTimeoutTime_EVCU2" SG_ 2654817991 ECU_APPL_FD_RFHM 0;
BA_ "GenSigTimeoutTime_ESL" SG_ 2654817991 ECU_APPL_FD_RFHM 0;
BA_ "GenSigTimeoutTime_ECM" SG_ 2654817991 ECU_APPL_FD_RFHM 0;
BA_ "GenSigTimeoutTime_DTCM" SG_ 2654817991 ECU_APPL_FD_RFHM 0;
BA_ "GenSigTimeoutTime_DMSM" SG_ 2654817991 ECU_APPL_FD_RFHM 0;
BA_ "GenSigTimeoutTime_BSM" SG_ 2654817991 ECU_APPL_FD_RFHM 0;
BA_ "GenSigTimeoutTime_BCM" SG_ 2654817991 ECU_APPL_FD_RFHM 0;
BA_ "GenSigTimeoutTime_AGSM" SG_ 2654817991 ECU_APPL_FD_RFHM 0;
BA_ "GenSigTimeoutTime_ADCAM" SG_ 2654817991 ECU_APPL_FD_RFHM 0;
BA_ "GenSigTimeoutTime_RFHM" SG_ 2654817818 ECU_APPL_FD_DTCM 0;
BA_ "GenSigTimeoutTime_MPAD" SG_ 2654817818 ECU_APPL_FD_DTCM 0;
BA_ "GenSigTimeoutTime_IPC" SG_ 2654817818 ECU_APPL_FD_DTCM 0;
BA_ "GenSigTimeoutTime_GNMM" SG_ 2654817818 ECU_APPL_FD_DTCM 0;
BA_ "GenSigTimeoutTime_EVCU2" SG_ 2654817818 ECU_APPL_FD_DTCM 0;
BA_ "GenSigTimeoutTime_ESL" SG_ 2654817818 ECU_APPL_FD_DTCM 0;
BA_ "GenSigTimeoutTime_ECM" SG_ 2654817818 ECU_APPL_FD_DTCM 0;
BA_ "GenSigTimeoutTime_DTCM" SG_ 2654817818 ECU_APPL_FD_DTCM 0;
BA_ "GenSigTimeoutTime_DMSM" SG_ 2654817818 ECU_APPL_FD_DTCM 0;
BA_ "GenSigTimeoutTime_BSM" SG_ 2654817818 ECU_APPL_FD_DTCM 0;
BA_ "GenSigTimeoutTime_BCM" SG_ 2654817818 ECU_APPL_FD_DTCM 0;
BA_ "GenSigTimeoutTime_AGSM" SG_ 2654817818 ECU_APPL_FD_DTCM 0;
BA_ "GenSigTimeoutTime_ADCAM" SG_ 2654817818 ECU_APPL_FD_DTCM 0;
BA_ "GenSigTimeoutTime_RFHM" SG_ 2654817823 ECU_APPL_FD_AGSM 0;
BA_ "GenSigTimeoutTime_MPAD" SG_ 2654817823 ECU_APPL_FD_AGSM 0;
BA_ "GenSigTimeoutTime_IPC" SG_ 2654817823 ECU_APPL_FD_AGSM 0;
BA_ "GenSigTimeoutTime_GNMM" SG_ 2654817823 ECU_APPL_FD_AGSM 0;
BA_ "GenSigTimeoutTime_EVCU2" SG_ 2654817823 ECU_APPL_FD_AGSM 0;
BA_ "GenSigTimeoutTime_ESL" SG_ 2654817823 ECU_APPL_FD_AGSM 0;
BA_ "GenSigTimeoutTime_ECM" SG_ 2654817823 ECU_APPL_FD_AGSM 0;
BA_ "GenSigTimeoutTime_DTCM" SG_ 2654817823 ECU_APPL_FD_AGSM 0;
BA_ "GenSigTimeoutTime_DMSM" SG_ 2654817823 ECU_APPL_FD_AGSM 0;
BA_ "GenSigTimeoutTime_BSM" SG_ 2654817823 ECU_APPL_FD_AGSM 0;
BA_ "GenSigTimeoutTime_BCM" SG_ 2654817823 ECU_APPL_FD_AGSM 0;
BA_ "GenSigTimeoutTime_AGSM" SG_ 2654817823 ECU_APPL_FD_AGSM 0;
BA_ "GenSigTimeoutTime_ADCAM" SG_ 2654817823 ECU_APPL_FD_AGSM 0;
BA_ "GenSigTimeoutTime_SGW" SG_ 1054 EngMaxRPM_W 0;
BA_ "GenSigTimeoutTime_RFHM" SG_ 1054 EngMaxRPM_W 0;
BA_ "GenSigTimeoutTime_MPAD" SG_ 1054 EngMaxRPM_W 0;
BA_ "GenSigTimeoutTime_IPC" SG_ 1054 EngMaxRPM_W 0;
BA_ "GenSigTimeoutTime_GNMM" SG_ 1054 EngMaxRPM_W 0;
BA_ "GenSigTimeoutTime_ESL" SG_ 1054 EngMaxRPM_W 0;
BA_ "GenSigTimeoutTime_ECM" SG_ 1054 EngMaxRPM_W 0;
BA_ "GenSigTimeoutTime_DTCM" SG_ 1054 EngMaxRPM_W 0;
BA_ "GenSigTimeoutTime_DMSM" SG_ 1054 EngMaxRPM_W 0;
BA_ "GenSigTimeoutTime_BSM" SG_ 1054 EngMaxRPM_W 0;
BA_ "GenSigTimeoutTime_BCM" SG_ 1054 EngMaxRPM_W 0;
BA_ "GenSigTimeoutTime_AGSM" SG_ 1054 EngMaxRPM_W 0;
BA_ "GenSigTimeoutTime_ADCAM" SG_ 1054 EngMaxRPM_W 0;
BA_ "GenSigStartValue" SG_ 1054 EngMaxRPM_W 255;
BA_ "GenSigTimeoutTime_SGW" SG_ 1054 CRC_ENGINE1 0;
BA_ "GenSigTimeoutTime_RFHM" SG_ 1054 CRC_ENGINE1 0;
BA_ "GenSigTimeoutTime_MPAD" SG_ 1054 CRC_ENGINE1 0;
BA_ "GenSigTimeoutTime_IPC" SG_ 1054 CRC_ENGINE1 0;
BA_ "GenSigTimeoutTime_GNMM" SG_ 1054 CRC_ENGINE1 0;
BA_ "GenSigTimeoutTime_ESL" SG_ 1054 CRC_ENGINE1 0;
BA_ "GenSigTimeoutTime_ECM" SG_ 1054 CRC_ENGINE1 0;
BA_ "GenSigTimeoutTime_DTCM" SG_ 1054 CRC_ENGINE1 0;
BA_ "GenSigTimeoutTime_DMSM" SG_ 1054 CRC_ENGINE1 0;
BA_ "GenSigTimeoutTime_BSM" SG_ 1054 CRC_ENGINE1 0;
BA_ "GenSigTimeoutTime_BCM" SG_ 1054 CRC_ENGINE1 0;
BA_ "GenSigTimeoutTime_AGSM" SG_ 1054 CRC_ENGINE1 0;
BA_ "GenSigTimeoutTime_ADCAM" SG_ 1054 CRC_ENGINE1 0;
BA_ "GenSigTimeoutTime_RFHM" SG_ 1054 BrkSw2Stat 0;
BA_ "GenSigTimeoutTime_MPAD" SG_ 1054 BrkSw2Stat 0;
BA_ "GenSigTimeoutTime_IPC" SG_ 1054 BrkSw2Stat 0;
BA_ "GenSigTimeoutTime_GNMM" SG_ 1054 BrkSw2Stat 0;
BA_ "GenSigTimeoutTime_EVCU2" SG_ 1054 BrkSw2Stat 0;
BA_ "GenSigTimeoutTime_ESL" SG_ 1054 BrkSw2Stat 0;
BA_ "GenSigTimeoutTime_ECM" SG_ 1054 BrkSw2Stat 0;
BA_ "GenSigTimeoutTime_DTCM" SG_ 1054 BrkSw2Stat 0;
BA_ "GenSigTimeoutTime_DMSM" SG_ 1054 BrkSw2Stat 0;
BA_ "GenSigTimeoutTime_BSM" SG_ 1054 BrkSw2Stat 0;
BA_ "GenSigTimeoutTime_AGSM" SG_ 1054 BrkSw2Stat 0;
BA_ "GenSigTimeoutTime_ADCAM" SG_ 1054 BrkSw2Stat 0;
BA_ "GenSigTimeoutTime_RFHM" SG_ 1054 BrkSw1Stat 0;
BA_ "GenSigTimeoutTime_MPAD" SG_ 1054 BrkSw1Stat 0;
BA_ "GenSigTimeoutTime_IPC" SG_ 1054 BrkSw1Stat 0;
BA_ "GenSigTimeoutTime_GNMM" SG_ 1054 BrkSw1Stat 0;
BA_ "GenSigTimeoutTime_EVCU2" SG_ 1054 BrkSw1Stat 0;
BA_ "GenSigTimeoutTime_ESL" SG_ 1054 BrkSw1Stat 0;
BA_ "GenSigTimeoutTime_ECM" SG_ 1054 BrkSw1Stat 0;
BA_ "GenSigTimeoutTime_DTCM" SG_ 1054 BrkSw1Stat 0;
BA_ "GenSigTimeoutTime_DMSM" SG_ 1054 BrkSw1Stat 0;
BA_ "GenSigTimeoutTime_BSM" SG_ 1054 BrkSw1Stat 0;
BA_ "GenSigTimeoutTime_BCM" SG_ 1054 BrkSw1Stat 0;
BA_ "GenSigTimeoutTime_AGSM" SG_ 1054 BrkSw1Stat 0;
BA_ "GenSigTimeoutTime_ADCAM" SG_ 1054 BrkSw1Stat 0;
BA_ "GenSigTimeoutTime_SGW" SG_ 1054 AtmosphericPressureFailSts_W 0;
BA_ "GenSigTimeoutTime_RFHM" SG_ 1054 AtmosphericPressureFailSts_W 0;
BA_ "GenSigTimeoutTime_MPAD" SG_ 1054 AtmosphericPressureFailSts_W 0;
BA_ "GenSigTimeoutTime_IPC" SG_ 1054 AtmosphericPressureFailSts_W 0;
BA_ "GenSigTimeoutTime_GNMM" SG_ 1054 AtmosphericPressureFailSts_W 0;
BA_ "GenSigTimeoutTime_EVCU2" SG_ 1054 AtmosphericPressureFailSts_W 0;
BA_ "GenSigTimeoutTime_ESL" SG_ 1054 AtmosphericPressureFailSts_W 0;
BA_ "GenSigTimeoutTime_ECM" SG_ 1054 AtmosphericPressureFailSts_W 0;
BA_ "GenSigTimeoutTime_DTCM" SG_ 1054 AtmosphericPressureFailSts_W 0;
BA_ "GenSigTimeoutTime_DMSM" SG_ 1054 AtmosphericPressureFailSts_W 0;
BA_ "GenSigTimeoutTime_BSM" SG_ 1054 AtmosphericPressureFailSts_W 0;
BA_ "GenSigTimeoutTime_BCM" SG_ 1054 AtmosphericPressureFailSts_W 0;
BA_ "GenSigTimeoutTime_AGSM" SG_ 1054 AtmosphericPressureFailSts_W 0;
BA_ "GenSigTimeoutTime_ADCAM" SG_ 1054 AtmosphericPressureFailSts_W 0;
BA_ "GenSigTimeoutTime_SGW" SG_ 1054 AtmosphericPressure_W 0;
BA_ "GenSigTimeoutTime_MPAD" SG_ 1054 AtmosphericPressure_W 0;
BA_ "GenSigTimeoutTime_IPC" SG_ 1054 AtmosphericPressure_W 0;
BA_ "GenSigTimeoutTime_GNMM" SG_ 1054 AtmosphericPressure_W 0;
BA_ "GenSigTimeoutTime_EVCU2" SG_ 1054 AtmosphericPressure_W 0;
BA_ "GenSigTimeoutTime_ESL" SG_ 1054 AtmosphericPressure_W 0;
BA_ "GenSigTimeoutTime_ECM" SG_ 1054 AtmosphericPressure_W 0;
BA_ "GenSigTimeoutTime_DTCM" SG_ 1054 AtmosphericPressure_W 0;
BA_ "GenSigTimeoutTime_DMSM" SG_ 1054 AtmosphericPressure_W 0;
BA_ "GenSigTimeoutTime_BSM" SG_ 1054 AtmosphericPressure_W 0;
BA_ "GenSigTimeoutTime_BCM" SG_ 1054 AtmosphericPressure_W 0;
BA_ "GenSigTimeoutTime_AGSM" SG_ 1054 AtmosphericPressure_W 0;
BA_ "GenSigTimeoutTime_ADCAM" SG_ 1054 AtmosphericPressure_W 0;
BA_ "GenSigStartValue" SG_ 1054 AtmosphericPressure_W 255;
BA_ "GenSigTimeoutTime_BSM" SG_ 1054 RawTPS1 0;
BA_ "GenSigTimeoutTime_AGSM" SG_ 1054 RawTPS1 0;
BA_ "GenSigTimeoutTime_ADCAM" SG_ 1054 RawTPS1 0;
BA_ "GenSigStartValue" SG_ 1054 RawTPS1 255;
BA_ "GenSigTimeoutTime_SGW" SG_ 1054 MessageCounter_ENGINE1 0;
BA_ "GenSigTimeoutTime_RFHM" SG_ 1054 MessageCounter_ENGINE1 0;
BA_ "GenSigTimeoutTime_MPAD" SG_ 1054 MessageCounter_ENGINE1 0;
BA_ "GenSigTimeoutTime_IPC" SG_ 1054 MessageCounter_ENGINE1 0;
BA_ "GenSigTimeoutTime_GNMM" SG_ 1054 MessageCounter_ENGINE1 0;
BA_ "GenSigTimeoutTime_ESL" SG_ 1054 MessageCounter_ENGINE1 0;
BA_ "GenSigTimeoutTime_ECM" SG_ 1054 MessageCounter_ENGINE1 0;
BA_ "GenSigTimeoutTime_DTCM" SG_ 1054 MessageCounter_ENGINE1 0;
BA_ "GenSigTimeoutTime_DMSM" SG_ 1054 MessageCounter_ENGINE1 0;
BA_ "GenSigTimeoutTime_BSM" SG_ 1054 MessageCounter_ENGINE1 0;
BA_ "GenSigTimeoutTime_BCM" SG_ 1054 MessageCounter_ENGINE1 0;
BA_ "GenSigTimeoutTime_AGSM" SG_ 1054 MessageCounter_ENGINE1 0;
BA_ "GenSigTimeoutTime_ADCAM" SG_ 1054 MessageCounter_ENGINE1 0;
BA_ "GenSigTimeoutTime_RFHM" SG_ 1054 Lv1CrsCtrlOff 0;
BA_ "GenSigTimeoutTime_MPAD" SG_ 1054 Lv1CrsCtrlOff 0;
BA_ "GenSigTimeoutTime_IPC" SG_ 1054 Lv1CrsCtrlOff 0;
BA_ "GenSigTimeoutTime_GNMM" SG_ 1054 Lv1CrsCtrlOff 0;
BA_ "GenSigTimeoutTime_EVCU2" SG_ 1054 Lv1CrsCtrlOff 0;
BA_ "GenSigTimeoutTime_ESL" SG_ 1054 Lv1CrsCtrlOff 0;
BA_ "GenSigTimeoutTime_ECM" SG_ 1054 Lv1CrsCtrlOff 0;
BA_ "GenSigTimeoutTime_DTCM" SG_ 1054 Lv1CrsCtrlOff 0;
BA_ "GenSigTimeoutTime_DMSM" SG_ 1054 Lv1CrsCtrlOff 0;
BA_ "GenSigTimeoutTime_BSM" SG_ 1054 Lv1CrsCtrlOff 0;
BA_ "GenSigTimeoutTime_AGSM" SG_ 1054 Lv1CrsCtrlOff 0;
BA_ "GenSigTimeoutTime_ADCAM" SG_ 1054 Lv1CrsCtrlOff 0;
BA_ "GenSigTimeoutTime_RFHM" SG_ 1054 ESP_TrqRqEnabl 0;
BA_ "GenSigTimeoutTime_MPAD" SG_ 1054 ESP_TrqRqEnabl 0;
BA_ "GenSigTimeoutTime_IPC" SG_ 1054 ESP_TrqRqEnabl 0;
BA_ "GenSigTimeoutTime_GNMM" SG_ 1054 ESP_TrqRqEnabl 0;
BA_ "GenSigTimeoutTime_EVCU2" SG_ 1054 ESP_TrqRqEnabl 0;
BA_ "GenSigTimeoutTime_ESL" SG_ 1054 ESP_TrqRqEnabl 0;
BA_ "GenSigTimeoutTime_ECM" SG_ 1054 ESP_TrqRqEnabl 0;
BA_ "GenSigTimeoutTime_DTCM" SG_ 1054 ESP_TrqRqEnabl 0;
BA_ "GenSigTimeoutTime_DMSM" SG_ 1054 ESP_TrqRqEnabl 0;
BA_ "GenSigTimeoutTime_BSM" SG_ 1054 ESP_TrqRqEnabl 0;
BA_ "GenSigTimeoutTime_AGSM" SG_ 1054 ESP_TrqRqEnabl 0;
BA_ "GenSigTimeoutTime_ADCAM" SG_ 1054 ESP_TrqRqEnabl 0;
VAL_ 264 LwsAngle 65535 "SNA";
VAL_ 264 LwsSpeed 4095 "SNA";
VAL_ 1448 ExhaustTemperature 255 "SNA";
VAL_ 1448 ETCFailSts 0 "Fail_Not_Present" 1 "Fail_Flash_Light_Indication" 2 "Fail_Fix_Light_Indication" 3 "Flash_For_Service";
VAL_ 1448 EngineOperatingMode 0 "Normal" 1 "DPF Regeneration LO" 2 "DPF Regeneration HI" 3 "NSC DeNOx Regeneration" 4 "NSC DeSOx Regeneration" 5 "SCR Heat-up strategy";
VAL_ 1448 EMSFailSts 0 "Fail_Not_Present" 1 "Fail_Flash_Light_Indication" 2 "Fail_Fix_Light_Indication" 3 "Flash_For_Service";
VAL_ 1448 ECM_WARN 0 "NONE" 1 "CC_NOT_AVAIL_PLACE_SHIFTER_IN_D" 2 "CC_NOT_AVAIL_PARKBRAKE_ENGAGED" 3 "CC_NOT_AVAIL_STABIL_EVENT_OCCUR" 4 "CC_NOT_AVAIL_LOW_RANGE_4WD" 5 "CC_NOT_AVAIL_VEHICLE_SYSTEM_ERR" 6 "SL_NOT_AVAIL_HDC_SET" 7 "CC_CANC_PLACE_SHIFTER_IN_DRIVE" 8 "CC_CANC_PARKBRAKE_ENGAGED" 9 "CC_CANC_STABILITY_EVENT_OCCUR" 10 "SL_NOT_AVAILABLE_SSC_SET" 11 "CC_CANC_VEHICLE_SYSTEM_ERROR" 12 "CC_OFF_ASL_ACTIVE" 13 "ASL OFF CRUISE ACTIVE" 14 "CC_NOT_AVAIL_BELOW_MIN_RES_SPD" 15 "CC_CANCELLED_ESC_OFF" 16 "CC_UNAVAILABLE_ESC_OFF" 17 "CC_CANCELLED_BY_DRIVER" 18 "CC_OFF" 19 "CC_CANCELLED_RPM_DROPS_TOO_LOW" 20 "CC_NOT_AVAIL_RPM_DROPS_TOO_LOW" 21 "CC_CANCELLED_RPM_TOO_HIGH" 22 "CC_NOT_AVAILABLE_RPM_TOO_HIGH" 23 "DRIVER_CRUISE_OVERRIDE" 24 "CC_NOT_AVAILABLE_HDC_SET" 25 "ISA_NOT_AVAIL_TSR_NOT_AVAIL" 26 "ISA_NOT_AVAIL_SPEED_TOO_HIGH" 27 "ISA_NOT_AVAIL_SPEED_TOO_ LOW" 28 "CC_NOT_AVAIL_ABOVE_MAX_SPD" 29 "CC_UNAVAIL_CORSA_MODE_ON" 30 "SL_UNAVAIL_CORSA_MODE_ON" 31 "CNA_OFF_ROAD_PLUS_ACTIVE";
VAL_ 751 EngineWaterTemp 255 "SNA";
VAL_ 1447 TerSt_SWITCH2 0 "Off" 1 "Continuous" 2 "Blink" 3 "SNA";
VAL_ 1447 TerSt_SWITCH1 0 "Off" 1 "Continuous" 2 "Blink" 3 "SNA";
VAL_ 1447 DTCM_HMI_Rq 0 "No_request" 1 "SCREEN_1" 2 "SCREEN_2" 3 "SCREEN_3" 4 "SCREEN_4" 5 "SCREEN_5" 6 "SCREEN_6" 7 "SCREEN_7" 8 "SCREEN_8" 9 "SCREEN_9" 10 "SCREEN_10" 11 "SCREEN_11" 12 "SCREEN_12" 13 "SCREEN_13" 14 "SCREEN_14" 15 "SCREEN_15" 16 "SCREEN_16" 17 "SCREEN_17" 18 "SCREEN_18" 19 "SCREEN_19" 20 "SCREEN_20" 21 "SCREEN_21" 22 "SCREEN_22" 23 "SCREEN_23" 24 "SCREEN_24" 25 "SCREEN_25" 26 "SCREEN_26" 27 "SCREEN_27" 28 "SCREEN_28" 29 "SCREEN_29" 30 "SCREEN_30" 31 "SNA";
VAL_ 517 Ft_RrCouplingTrq_Desired 255 "SNA";
VAL_ 517 Ft_RrCouplingTrq_Actual 255 "SNA";
VAL_ 517 DrvLnMinTrqMd 0 "False" 1 "True";
VAL_ 517 CCMFailSts 0 "FailNotPresent" 1 "FailPresent";
VAL_ 517 AWDSysStat 0 "SH_IPG" 1 "4LO" 2 "4HI" 3 "2WD" 4 "NEUTRAL" 5 "SYNC_IPG" 6 "4WDLock" 7 "SNA";
VAL_ 1155 TSCActive 0 "Not_Active" 1 "Active";
VAL_ 1155 RollsModeAct 0 "Not_active" 1 "Active";
VAL_ 1155 FunctionIntervention 0 "No_intervention" 1 "Intervention_blinking_lamp";
VAL_ 1155 FunctionFailSts 0 "Fail_Not_Present" 1 "Fail_Present";
VAL_ 1155 Function2Sts 0 "Not_Active" 1 "Active";
VAL_ 1155 ESCIntervention 0 "No_intervention" 1 "Intervention_blinking_lamp";
VAL_ 1155 ESCFailSts 0 "Fail_Not_Present" 1 "Fail_Present";
VAL_ 1155 ERMActive 0 "Not_Active" 1 "Active";
VAL_ 1155 EBDFailSts 0 "Fail_Not_Present" 1 "Fail_Present";
VAL_ 1155 CMMIntervention 0 "No_intervention" 1 "Intervention";
VAL_ 1155 BSMSysSts 0 "Normal mode" 1 "Diagnosis mode" 2 "Alternative mode" 3 "SNA";
VAL_ 1155 ACCEngaged 0 "Not_Engaged" 1 "Engaged";
VAL_ 1155 ABSFailSts 0 "Fail_Not_Present" 1 "Fail_Present";
VAL_ 609 TravelDistance 255 "SNA";
VAL_ 609 RedLampReq 0 "Off" 1 "Fixed" 2 "Blinking" 3 "SNA";
VAL_ 609 MSRActive 0 "Not_Active" 1 "Active";
VAL_ 609 EPBSwitchPosition 0 "No request" 1 "Release request" 2 "Apply request" 3 "Error";
VAL_ 609 EPBSts 0 "Released" 1 "Applied" 2 "DynamicBrkESC" 3 "DynamicBrkEPB" 4 "Emergency_Braking" 5 "Applying" 6 "Maintenance_Mode" 7 "Assembly_Check" 8 "Inspection_Mode" 9 "Re_Clamping" 10 "Adjuste_Mode" 11 "Releasing" 12 "Fault_EPB_Released" 13 "Fault_EPB_Applied" 14 "Fault_Present" 15 "SNA";
VAL_ 609 EPBMaintenanceSts 0 "Maintenance_Disabled" 1 "Maintenance_Enabled";
VAL_ 609 EPBAutoAppSts 0 "AutoApply_Disable" 1 "AutoApply_Enable";
VAL_ 609 EPB_HMI_Management 0 "No_Ind" 1 "Ind1" 2 "Ind2" 3 "Ind3" 4 "Ind4" 5 "Ind5" 6 "Ind6" 7 "Ind7" 8 "Ind8" 9 "Ind9" 10 "Ind10" 11 "Ind11" 12 "Ind12" 13 "Ind13" 14 "Ind14" 15 "Ind15" 16 "Ind16" 17 "Ind17" 18 "Ind18" 19 "Ind19" 20 "Ind20" 21 "Ind21" 22 "Ind22" 23 "Ind23" 24 "Ind24" 25 "Ind25" 26 "Ind26" 27 "Ind27" 28 "Ind28" 29 "Ind29" 30 "Ind30" 31 "Ind31";
VAL_ 609 ClampForce 0 "Initialization" 511 "SNA";
VAL_ 609 ASRActive 0 "Not_active" 1 "Active";
VAL_ 259 RHR_WheelSensorFailSts 0 "Fail_Not_Present" 1 "Fail_Present";
VAL_ 259 RHR_Spin 0 "Stand_Still" 1 "Forward" 2 "Backward" 3 "SNA";
VAL_ 259 RHR_FastPulseCounter 255 "SNA";
VAL_ 259 RHF_WheelSensorFailSts 0 "Fail_Not_Present" 1 "Fail_Present";
VAL_ 259 RHF_FastPulseCounter 255 "SNA";
VAL_ 259 LHR_WheelSensorFailSts 0 "Fail_Not_Present" 1 "Fail_Present";
VAL_ 259 LHR_Spin 0 "Stand_Still" 1 "Forward" 2 "Backward" 3 "SNA";
VAL_ 259 LHR_FastPulseCounter 255 "SNA";
VAL_ 259 LHF_WheelSensorFailSts 0 "Fail_Not_Present" 1 "Fail_Present";
VAL_ 259 LHF_FastPulseCounter 255 "SNA";
VAL_ 1055 RevOilLifeRst 65535 "SNA";
VAL_ 1055 RefuelEvent 0 "NONE" 1 "PEND" 2 "TRUE" 3 "COMP" 4 "FAULT";
VAL_ 1055 OIL_PRESS 255 "SNA";
VAL_ 1055 MAP_4_BAR 511 "SNA";
VAL_ 1055 AM_ECM_Prsnt 0 "DEFAULT" 2 "AM_ECM_PRESENT" 3 "SNA";
VAL_ 1448 OilPressureSts 0 "Normal_Pressure" 1 "Low_Pressure";
VAL_ 1448 HoursOilLifeRst 4095 "SNA";
VAL_ 751 LeakTestSts 0 "NONE" 1 "PEND" 2 "COMPLETE" 3 "DELAY";
VAL_ 751 LeakTestRequest 0 "No_Request" 1 "Leak_Test_Requested";
VAL_ 751 LeakCheckTimerValue 511 "SNA";
VAL_ 518 RPMOverRev_W 0 "FALSE" 1 "TRUE";
VAL_ 518 PdlPosActual 255 "SNA";
VAL_ 518 ECM_READINESS_RESET_W 0 "Not Set" 1 "Set";
VAL_ 518 ECM_CODE_CLR_W 0 "Not Cleared" 1 "Cleared";
VAL_ 1054 ThermalManagementActive_W 0 "Not_active" 1 "Active";
VAL_ 1054 EngMaxRPM_W 255 "SNA";
VAL_ 1054 AtmosphericPressureFailSts_W 0 "Fail_Not_Present" 1 "Fail_Present";
VAL_ 1054 AtmosphericPressure_W 255 "SNA";
VAL_ 1068 DTCM_Vehicle_Hold_Rq 0 "NotActive" 1 "Active";
VAL_ 514 PAM_Brk_Rq_RspSts 0 "Not_Active" 1 "Active" 2 "Faulted_Condition" 3 "SNA";
VAL_ 514 HoldnGoLEDSts 0 "OFF" 1 "ON" 2 "Blinking" 3 "SNA";
VAL_ 514 BrkPdl_Stat 0 "UPSTOP" 1 "PSD" 2 "NDEF2" 3 "SNA";
VAL_ 514 BrkPdl_Flt 0 "NOT FAULTED" 1 "FAULTED";
VAL_ 514 BrakePdlPosn 255 "SNA";
VAL_ 514 AVHTextDispaly 0 "Text0" 1 "Text1" 2 "Text2" 3 "Text3" 4 "Text4" 5 "Text5" 6 "Text6" 7 "Text7" 8 "Text8" 9 "Text9" 10 "Text10" 11 "Text11" 12 "Text12" 13 "Text13" 14 "Text14" 15 "SNA";
VAL_ 514 AutoVehHoldSts 0 "Enabled" 1 "NOT Enabled" 2 "Active" 3 "Failed";
VAL_ 1155 HDCUserFdBck 0 "On" 1 "Off" 2 "Blink" 3 "SNA";
VAL_ 609 REPRGD_PFC_CLR_BSM 0 "Do_Nothing" 1 "Set_Incomplete";
VAL_ 609 MIL_OnRq_BSM 0 "False" 1 "True";
VAL_ 609 EPBWarningLampReq 0 "OFF" 1 "CONT" 2 "BLINK" 3 "SNA";
VAL_ 609 CODE_CLR_BSM 0 "Do_Nothing" 1 "Set_Incomplete";
VAL_ 259 RHRWheelSpeed 8191 "SNA";
VAL_ 259 RHFWheelSpeed 8191 "SNA";
VAL_ 259 RHF_Spin 0 "Stand_Still" 1 "Forward" 2 "Backward" 3 "SNA";
VAL_ 259 LHRWheelSpeed 8191 "SNA";
VAL_ 259 LHFWheelSpeed 8191 "SNA";
VAL_ 259 LHF_Spin 0 "Stand_Still" 1 "Forward" 2 "Backward" 3 "SNA";
VAL_ 264 LwsCalibration 0 "Not_calibrated" 1 "Calibrated";
VAL_ 264 LwsAngleType 0 "Absolute" 1 "Relative" 3 "SNA";
VAL_ 264 EngineFanRequestActivation 0 "False" 1 "True";
VAL_ 264 ElectricSteeringFailSts 0 "Fail_Not_Present" 1 "Fail_Present";
VAL_ 514 Rear_Diff_BSM_RQ 0 "FREE" 1 "HOLD" 2 "OPEN" 3 "SNA";
VAL_ 1056 EPS_Warn_Disp_Rq 0 "EPS function active OK" 1 "Warning - Service power steering ERR" 2 "Warning - Power steering-over temp ERR2" 3 "Service Required - High Priority SERV_HI" 7 "SNA";
VAL_ 1068 TCASERANGESTATUS 0 "HIGH" 1 "NTRL" 2 "LOW" 3 "SNA";
VAL_ 514 R_DIFF_TRQ_RQ 511 "SNA";
VAL_ 514 BSM_OpStat 0 "Inactive" 1 "FullService" 2 "FailOperational" 3 "FailDegraded" 4 "Emergency" 5 "No_Function";
VAL_ 514 Brake_OpStat_Prim 0 "Inactive" 1 "FullService" 2 "FailOperational" 3 "FailDegraded" 4 "Emergency" 5 "No_Function";
VAL_ 514 AEB_Type_Brk 0 "NONE" 1 "ACC" 2 "CMS" 3 "CMS_XTD" 4 "ABA" 5 "LSCM" 6 "PEB" 7 "ICA_L" 8 "ICA_R" 9 "HAS_MRM" 10 "RRCC" 11 "L3" 15 "SNA";
VAL_ 1155 FunctionSts 0 "Not_Active" 1 "Active";
VAL_ 1054 HighPressureFuelSystemFailure 0 "No_Fault" 1 "Fault";
VAL_ 259 LongAccelerationOffset_BSM 255 "SNA";
VAL_ 259 LatAccelerationOffset_BSM 255 "SNA";
VAL_ 259 LwsAngleOffset_BSM 1023 "SNA";
VAL_ 1448 MntncSts 0 "NONE" 1 "SOON" 2 "NOW" 3 "SNA";
VAL_ 609 ESC_OFF_Hrd_Sft_Button_sts 0 "STREET" 1 "SPORT" 2 "TRACK" 3 "OFF" 4 "SNOW" 5 "OFFROAD" 6 "DRAG" 7 "SNA";
VAL_ 1447 Ft_RrCouplingTrq_percentage 255 "SNA";
VAL_ 517 SpeedSyncRq 0 "Inactive" 1 "Hi_Sync" 2 "Lo_Sync" 3 "Neutral" 7 "SNA";
VAL_ 517 RDU_State 0 "High" 1 "Neutral" 2 "Low" 3 "SNA";
VAL_ 517 PTU_State 0 "High_4" 1 "High_2" 2 "Neutral" 3 "Low" 7 "SNA";
VAL_ 1155 HillHolderFailSts 0 "Fail_Not_Present" 1 "Fail_Present";
VAL_ 1055 RefuelIndication 0 "NONE" 1 "WAIT" 2 "PARK" 3 "OK" 4 "DOOR" 5 "BLOCKAGE" 6 "SERVICE";
VAL_ 1068 RrAxleLockerIndRq 0 "OFF" 1 "ON" 2 "BLINK" 3 "SNA";
VAL_ 1068 AxleLckrEvicDisp 0 "None" 1 "SCREEN_1" 2 "SCREEN_2" 3 "SCREEN_3" 4 "SCREEN_4" 5 "SCREEN_5" 6 "SCREEN_6" 7 "SCREEN_7" 8 "SCREEN_8" 9 "SCREEN_9" 10 "SCREEN_10" 11 "SCREEN_11" 12 "SCREEN_12" 13 "SCREEN_13" 14 "SCREEN_14" 15 "SCREEN_15" 16 "SCREEN_16" 17 "SCREEN_17" 18 "SCREEN_18" 19 "SCREEN_19" 20 "SCREEN_20" 21 "SCREEN_21" 22 "SCREEN_22" 23 "SCREEN_23" 24 "SCREEN_24" 25 "SCREEN_25" 26 "SCREEN_26" 27 "SCREEN_27" 28 "SCREEN_28" 29 "SCREEN_29" 30 "SCREEN_30" 31 "SNA";
VAL_ 1068 AxleLckr_Stat 0 "Unlocked" 1 "Rear_Locked" 2 "Front_Rear_Locked" 3 "SNA";
VAL_ 1068 AxleLckr_SRV_RQ 0 "OFF" 1 "ON" 2 "BLINK" 3 "SNA";
VAL_ 264 LwsAngle_F 65535 "SNA";
VAL_ 751 ECM_FOTA_Conflict 0 "False" 1 "True";
VAL_ 517 TCASE_TargetRangeState 0 "High" 1 "Neutral" 2 "Low" 3 "SNA";

SIG_GROUP_ 1054 ENGINE_FD_1_Pkt 1 : ThrottlePosition ThermalManagementActive_W RawTPS2 RawTPS1 MessageCounter_ENGINE1 Lv1CrsCtrlOff ESP_TrqRqEnabl EngMaxRPM_W CRC_ENGINE1 BrkSw2Stat BrkSw1Stat AtmosphericPressureFailSts_W AtmosphericPressure_W HighPressureFuelSystemFailure;
SIG_GROUP_ 264 EPS_FD_1_Pkt 1 : LwsAngle LwsSpeed MessageCounter_EPS1 CRC_EPS1 LwsCalibration LwsAngleType EngineFanRequestActivation ElectricSteeringFailSts LwsAngle_F MAC_EPS1 Cntr_EPS1;
SIG_GROUP_ 518 ENGINE_FD_5_Pkt 1 : RPMOverRev_W PdlPosActual MessageCounter_ENGINE5 ECM_READINESS_RESET_W ECM_CODE_CLR_W CRC_ENGINE5;
SIG_GROUP_ 1068 DRIVETRAIN_FD_3_Pkt 1 : MessageCounter_DRIVETRAIN3 CRC__DRIVETRAIN3 DTCM_Vehicle_Hold_Rq TCASERANGESTATUS RrAxleLockerIndRq AxleLckrEvicDisp AxleLckr_Stat AxleLckr_SRV_RQ;
SIG_GROUP_ 517 DRIVETRAIN_FD_1_Pkt 1 : MessageCounter_DRIVETRAIN1 CRC_DRIVETRAIN1 Ft_RrCouplingTrq_Desired Ft_RrCouplingTrq_Actual DrvLnMinTrqMd CCMFailSts AWDSysStat TCASE_TargetRangeState SpeedSyncRq RDU_State PTU_State DrvLnTrqRq_Axle;
SIG_GROUP_ 514 BRAKE_FD_7_Pkt 1 : PAM_Brk_Rq_RspSts MessageCounter_BRAKE7 HoldnGoLEDSts CRC_BRAKE7 BrkPdl_Stat BrkPdl_Flt BrakePdlPosn AVHTextDispaly AutoVehHoldSts Rear_Diff_BSM_RQ R_DIFF_TRQ_RQ BSM_OpStat Brake_OpStat_Prim AEB_Type_Brk;
SIG_GROUP_ 1155 BRAKE_FD_5_Pkt 1 : TSCActive RollsModeAct FunctionIntervention FunctionFailSts Function2Sts ESCIntervention ESCFailSts ERMActive EBDFailSts CMMIntervention BSMSysSts ACCEngaged ABSFailSts MessageCounter_BRAKE5 HDCUserFdBck CRC_BRAKE5 FunctionSts HillHolderFailSts;
SIG_GROUP_ 609 BRAKE_FD_4_Pkt 1 : TravelDistance RedLampReq MSRActive EPBSwitchPosition EPBSts EPBMaintenanceSts EPBAutoAppSts EPB_HMI_Management ClampForce ASRActive REPRGD_PFC_CLR_BSM MIL_OnRq_BSM MessageCounter_BRAKE4 ESCSysEmsMlfAtv EPBWarningLampReq CRC_BRAKE4 CODE_CLR_BSM ESC_OFF_Hrd_Sft_Button_sts;
SIG_GROUP_ 259 BRAKE_FD_3_Pkt 1 : RHR_WheelSensorFailSts RHR_Spin RHR_FastPulseCounter RHF_WheelSensorFailSts RHF_FastPulseCounter LHR_WheelSensorFailSts LHR_Spin LHR_FastPulseCounter LHF_WheelSensorFailSts LHF_FastPulseCounter RHRWheelSpeed RHFWheelSpeed RHF_Spin MessageCounter_BRAKE3 LHRWheelSpeed LHFWheelSpeed LHF_Spin CRC__BRAKE3 LongAccelerationOffset_BSM LatAccelerationOffset_BSM LwsAngleOffset_BSM;
